VERSION ""

NS_ :

BS_:

BU_: DCM CCU C_ECU C_ECU_GW

BO_ 914 MET392: 32 C_ECU_GW
 SG_ MET392_23_0_ADD_ACNON_DRVRANG : 184|11@1+ (1,0) [0|1999] "km"  CCU
 SG_ MET392_21_0_ADD_ACNOFF_DRVRANG : 168|11@1+ (1,0) [0|1999] "km"  CCU
 SG_ MET392_18_0_TRIP_LASTCHG_TOTM : 144|20@1+ (1,0) [0|599940] "min"  CCU
 SG_ MET392_15_0_TRIPB_TOTAL_TIME : 120|20@1+ (1,0) [0|599940] "min"  CCU
 SG_ MET392_12_0_TRIPA_TOTAL_TIME : 96|20@1+ (1,0) [0|599940] "min"  CCU
 SG_ MET392_9_0_TRIP_LASTCHARGE_KM : 72|18@1+ (0.1,0) [0|16200] "km"  CCU
 SG_ MET392_8_2_TRIPB_RESET : 66|1@1+ (1,0) [0|1] "" Vector__XXX
 SG_ MET392_6_0_TRIPB_KM : 48|18@1+ (0.1,0) [0|16200] "km"  CCU
 SG_ MET392_5_2_TRIPA_RESET : 42|1@1+ (1,0) [0|1] "" Vector__XXX
 SG_ MET392_3_0_TRIPA_KM : 24|18@1+ (0.1,0) [0|16200] "km"  CCU
 SG_ MET392_2_0_E2E_COUNTER : 16|8@1+ (1,0) [0|255] ""  CCU
 SG_ MET392_0_0_CRC : 0|16@1+ (1,0) [0|65535] ""  CCU

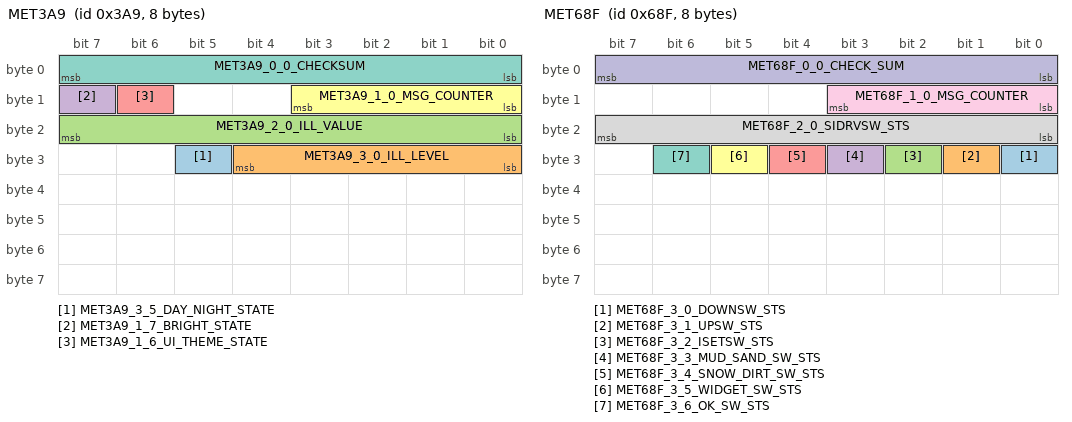
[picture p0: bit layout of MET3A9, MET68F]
BO_ 937 MET3A9: 8 C_ECU_GW
 SG_ MET3A9_3_5_DAY_NIGHT_STATE : 29|1@1+ (1,0) [0|1] ""  CCU
 SG_ MET3A9_3_0_ILL_LEVEL : 24|5@1+ (1,0) [0|21] ""  CCU
 SG_ MET3A9_2_0_ILL_VALUE : 16|8@1+ (0.4,0) [0|100] "%" Vector__XXX
 SG_ MET3A9_1_7_BRIGHT_STATE : 15|1@1+ (1,0) [0|1] ""  CCU
 SG_ MET3A9_1_6_UI_THEME_STATE : 14|1@1+ (1,0) [0|1] ""  CCU
 SG_ MET3A9_1_0_MSG_COUNTER : 8|4@1+ (1,0) [0|15] ""  CCU
 SG_ MET3A9_0_0_CHECKSUM : 0|8@1+ (1,0) [0|255] ""  CCU

BO_ 1679 MET68F: 8 C_ECU_GW
 SG_ MET68F_3_0_DOWNSW_STS : 24|1@1+ (1,0) [0|1] ""  CCU
 SG_ MET68F_3_1_UPSW_STS : 25|1@1+ (1,0) [0|1] ""  CCU
 SG_ MET68F_3_2_ISETSW_STS : 26|1@1+ (1,0) [0|1] ""  CCU
 SG_ MET68F_3_3_MUD_SAND_SW_STS : 27|1@1+ (1,0) [0|1] ""  CCU
 SG_ MET68F_3_4_SNOW_DIRT_SW_STS : 28|1@1+ (1,0) [0|1] ""  CCU
 SG_ MET68F_3_5_WIDGET_SW_STS : 29|1@1+ (1,0) [0|1] ""  CCU
 SG_ MET68F_3_6_OK_SW_STS : 30|1@1+ (1,0) [0|1] ""  CCU
 SG_ MET68F_2_0_SIDRVSW_STS : 16|8@1+ (1,0) [0|3] ""  CCU
 SG_ MET68F_1_0_MSG_COUNTER : 8|4@1+ (1,0) [0|15] ""  CCU
 SG_ MET68F_0_0_CHECK_SUM : 0|8@1+ (1,0) [0|255] ""  CCU

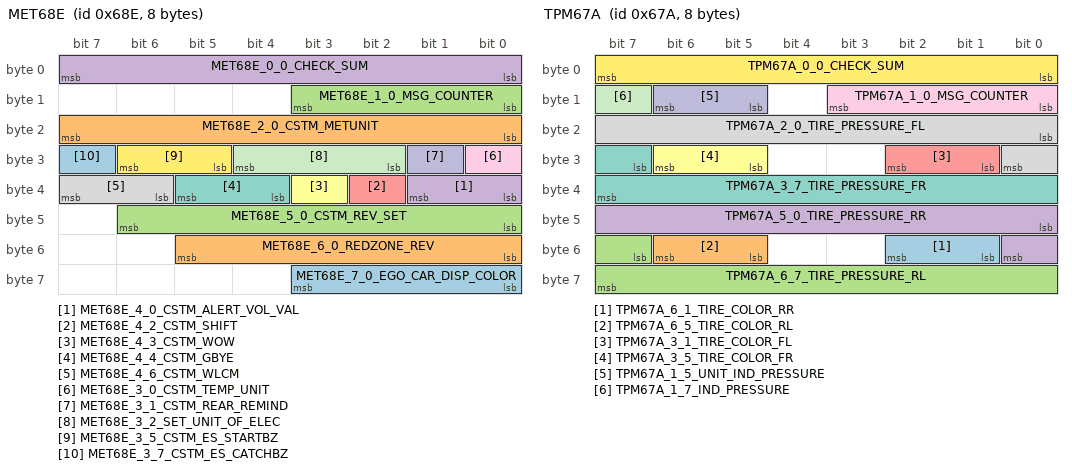
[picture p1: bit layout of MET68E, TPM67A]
BO_ 1678 MET68E: 8 C_ECU_GW
 SG_ MET68E_7_0_EGO_CAR_DISP_COLOR : 56|4@1+ (1,0) [0|9] "" Vector__XXX
 SG_ MET68E_6_0_REDZONE_REV : 48|6@1+ (100,5000) [0|40] "rpm"  CCU
 SG_ MET68E_5_0_CSTM_REV_SET : 40|7@1+ (1,0) [0|127] "" Vector__XXX
 SG_ MET68E_4_0_CSTM_ALERT_VOL_VAL : 32|2@1+ (1,0) [0|3] ""  CCU
 SG_ MET68E_4_2_CSTM_SHIFT : 34|1@1+ (1,0) [0|1] ""  CCU
 SG_ MET68E_4_3_CSTM_WOW : 35|1@1+ (1,0) [0|1] ""  CCU
 SG_ MET68E_4_4_CSTM_GBYE : 36|2@1+ (1,0) [0|3] ""  CCU
 SG_ MET68E_4_6_CSTM_WLCM : 38|2@1+ (1,0) [0|3] ""  CCU
 SG_ MET68E_3_0_CSTM_TEMP_UNIT : 24|1@1+ (1,0) [0|1] ""  CCU
 SG_ MET68E_3_1_CSTM_REAR_REMIND : 25|1@1+ (1,0) [0|1] ""  CCU
 SG_ MET68E_3_2_SET_UNIT_OF_ELEC : 26|3@1+ (1,0) [0|7] ""  DCM,CCU
 SG_ MET68E_3_5_CSTM_ES_STARTBZ : 29|2@1+ (1,0) [0|2] ""  CCU
 SG_ MET68E_3_7_CSTM_ES_CATCHBZ : 31|1@1+ (1,0) [0|1] ""  CCU
 SG_ MET68E_2_0_CSTM_METUNIT : 16|8@1+ (1,0) [0|0] ""  CCU
 SG_ MET68E_1_0_MSG_COUNTER : 8|4@1+ (1,0) [0|15] ""  DCM,CCU
 SG_ MET68E_0_0_CHECK_SUM : 0|8@1+ (1,0) [0|255] ""  DCM,CCU

BO_ 1674 MET68A: 32 C_ECU_GW
 SG_ MET68A_31_0_METBZ_STS_CH0 : 248|1@1+ (1,0) [0|1] ""  CCU
 SG_ MET68A_31_1_METBZ_STS_CH1 : 249|1@1+ (1,0) [0|1] ""  CCU
 SG_ MET68A_31_2_METBZ_WARN_CH0 : 250|1@1+ (1,0) [0|1] ""  CCU
 SG_ MET68A_31_3_METBZ_PTN_CH0 : 251|1@1+ (1,0) [0|1] ""  CCU
 SG_ MET68A_31_4_METBZ_WARN_CH1 : 252|1@1+ (1,0) [0|1] ""  CCU
 SG_ MET68A_31_5_METBZ_PTN_CH1 : 253|1@1+ (1,0) [0|1] ""  CCU
 SG_ MET68A_31_6_VOL_ATN_REQ : 254|2@1+ (1,0) [0|3] ""  CCU
 SG_ MET68A_30_0_METBZ_KIND_CH1 : 240|8@1+ (1,0) [0|255] ""  CCU
 SG_ MET68A_29_0_METBZ_KIND_CH0 : 232|8@1+ (1,0) [0|255] ""  CCU
 SG_ MET68A_26_0_TRIPB_VAL : 208|24@1+ (0.1,0) [0|1677721.5] ""  CCU
 SG_ MET68A_23_0_TRIPA_VAL : 184|24@1+ (0.1,0) [0|1677721.5] ""  CCU
 SG_ MET68A_22_6_VOL_MUTE_REQ : 182|2@1+ (1,0) [0|3] ""  CCU
 SG_ MET68A_21_0_IGNONDIST_VAL : 168|14@1+ (1,0) [0|16383] ""  CCU
 SG_ MET68A_20_1_IGNONTM_MIN_VAL : 161|6@1+ (1,0) [0|59] "min"  CCU
 SG_ MET68A_19_0_AVSP_TRIPB_VAL : 152|9@1+ (1,0) [0|300] ""  CCU
 SG_ MET68A_18_1_IGNONTM_HOUR_VAL : 145|7@1+ (1,0) [0|99] "h"  CCU
 SG_ MET68A_17_0_AVSP_TRIPA_VAL : 136|9@1+ (1,0) [0|300] ""  CCU
 SG_ MET68A_16_0_TRIP_DISP_TYPE : 128|8@1+ (1,0) [0|0] ""  DCM,CCU
 SG_ MET68A_13_0_TRIP_VAL : 104|24@1+ (0.1,0) [0|9999.9] ""  CCU
 SG_ MET68A_12_0_TEMPBAR_PER : 96|8@1+ (1,0) [0|250] ""  CCU
 SG_ MET68A_11_0_FUELBAR_PER : 88|8@1+ (1,0) [0|100] ""  CCU
 SG_ MET68A_9_0_TACHOREV_VAL : 72|16@1+ (1,0) [0|8000] "rpm"  CCU
 SG_ MET68A_7_0_SPD_COR_VAL : 56|16@1+ (1,0) [0|65535] ""  CCU
 SG_ MET68A_6_1_CID_TONE_DOWN : 49|5@1+ (1,0) [0|31] ""  CCU
 SG_ MET68A_6_6_SI_FAIL_FLAG : 54|1@1+ (1,0) [0|1] ""  CCU
 SG_ MET68A_5_0_DMSPD_SUB_VAL : 40|9@1+ (1,0) [0|300] ""  CCU
 SG_ MET68A_4_1_ILM_AIDM : 33|1@1+ (1,0) [0|1] ""  CCU
 SG_ MET68A_4_2_TEMP_ICON : 34|3@1+ (1,0) [0|7] ""  CCU
 SG_ MET68A_4_5_SIDRIVE_MET_DISP : 37|3@1+ (1,0) [0|7] ""  CCU
 SG_ MET68A_3_0_DMSPD_VAL : 24|9@1+ (1,0) [0|300] ""  CCU
 SG_ MET68A_2_0_E2E_COUNTER : 16|8@1+ (1,0) [0|255] ""  DCM,CCU
 SG_ MET68A_0_0_CRC : 0|16@1+ (1,0) [0|65535] ""  DCM,CCU

BO_ 1673 MET689: 32 C_ECU_GW
 SG_ MET689_20_0_VOICE_GUIDE_SUP : 160|1@1+ (1,0) [0|1] ""  CCU
 SG_ MET689_19_0_SPORT_CONT : 152|8@1+ (1,0) [0|255] ""  CCU
 SG_ MET689_18_0_STI_SUP : 144|8@1+ (1,0) [0|255] "" Vector__XXX
 SG_ MET689_17_0_REARVIEW : 136|1@1+ (1,0) [0|1] ""  CCU
 SG_ MET689_16_0_GSR_ELKS_SUP : 128|1@1+ (1,0) [0|1] ""  CCU
 SG_ MET689_16_1_GSR_AEBS_SUP : 129|1@1+ (1,0) [0|1] ""  CCU
 SG_ MET689_16_2_GSR_DDAW_SUP : 130|1@1+ (1,0) [0|1] ""  CCU
 SG_ MET689_16_3_GSR_ISA_SUP : 131|1@1+ (1,0) [0|1] ""  CCU
 SG_ MET689_16_4_IACC_SUP : 132|1@1+ (1,0) [0|1] ""  CCU
 SG_ MET689_16_5_REAR_PANEL_SUP : 133|1@1+ (1,0) [0|1] ""  CCU
 SG_ MET689_16_6_SEAT_HEATER_SUP : 134|1@1+ (1,0) [0|1] ""  CCU
 SG_ MET689_16_7_SEAT_VENT_SUP : 135|1@1+ (1,0) [0|1] ""  CCU
 SG_ MET689_15_0_CAMERA : 120|8@1+ (1,0) [0|8] ""  CCU
 SG_ MET689_14_0_SXM_VARIANT : 112|8@1+ (1,0) [0|255] "" Vector__XXX
 SG_ MET689_13_0_DAB : 104|1@1+ (1,0) [0|1] ""  CCU
 SG_ MET689_13_1_SXM : 105|1@1+ (1,0) [0|1] ""  CCU
 SG_ MET689_13_2_EMBEDDED_NAVI : 106|1@1+ (1,0) [0|1] ""  CCU
 SG_ MET689_12_0_SPK_AMP : 96|8@1+ (1,0) [0|17] ""  CCU
 SG_ MET689_11_0_DEST_VEHICLE : 88|8@1+ (1,0) [0|255] ""  CCU
 SG_ MET689_10_0_RDIFF_TEMP_SUP : 80|1@1+ (1,0) [0|1] ""  CCU
 SG_ MET689_10_1_SIDRIVE_SW_TYPE : 81|2@1+ (1,0) [0|3] ""  CCU
 SG_ MET689_10_3_XMODE_SW_TYPE : 83|2@1+ (1,0) [0|3] ""  CCU
 SG_ MET689_9_0_GPF_SUP : 72|1@1+ (1,0) [0|1] ""  CCU
 SG_ MET689_9_1_SRH_SUP : 73|1@1+ (1,0) [0|1] ""  CCU
 SG_ MET689_9_2_AUTO_DOOR_MIRROR_SUP : 74|1@1+ (1,0) [0|1] ""  CCU
 SG_ MET689_9_3_REAR_REMIND_SUP : 75|1@1+ (1,0) [0|1] ""  CCU
 SG_ MET689_9_4_DRIVE_TYPE : 76|1@1+ (1,0) [0|1] ""  CCU
 SG_ MET689_9_5_TPMSDISP_SUP : 77|1@1+ (1,0) [0|1] ""  CCU
 SG_ MET689_9_6_GSI_SUP : 78|1@1+ (1,0) [0|1] ""  CCU
 SG_ MET689_9_7_SRVD_SUP : 79|1@1+ (1,0) [0|1] ""  CCU
 SG_ MET689_8_0_XMODE_SUP : 64|8@1+ (1,0) [0|3] ""  CCU
 SG_ MET689_7_0_SIDRIVE_SUP : 56|8@1+ (1,0) [0|19] ""  CCU
 SG_ MET689_6_0_GRADE_INFO : 48|8@1+ (1,0) [0|1] ""  CCU
 SG_ MET689_5_0_VEHICLE_TYPE : 40|8@1+ (1,0) [0|255] ""  CCU
 SG_ MET689_4_0_DEST_GRP : 32|8@1+ (1,0) [0|255] ""  CCU
 SG_ MET689_3_0_VEHICLE_MODEL : 24|8@1+ (1,0) [0|255] ""  CCU
 SG_ MET689_2_0_E2E_COUNTER : 16|8@1+ (1,0) [0|255] ""  CCU
 SG_ MET689_0_0_CRC : 0|16@1+ (1,0) [0|65535] ""  CCU

BO_ 1658 TPM67A: 8 C_ECU_GW
 SG_ TPM67A_6_1_TIRE_COLOR_RR : 49|2@1+ (1,0) [0|3] ""  CCU
 SG_ TPM67A_6_5_TIRE_COLOR_RL : 53|2@1+ (1,0) [0|3] ""  CCU
 SG_ TPM67A_6_7_TIRE_PRESSURE_RL : 55|9@1+ (1,0) [0|511] ""  DCM,CCU
 SG_ TPM67A_5_0_TIRE_PRESSURE_RR : 40|9@1+ (1,0) [0|511] ""  DCM,CCU
 SG_ TPM67A_3_1_TIRE_COLOR_FL : 25|2@1+ (1,0) [0|3] ""  CCU
 SG_ TPM67A_3_5_TIRE_COLOR_FR : 29|2@1+ (1,0) [0|3] ""  CCU
 SG_ TPM67A_3_7_TIRE_PRESSURE_FR : 31|9@1+ (1,0) [0|511] ""  DCM,CCU
 SG_ TPM67A_2_0_TIRE_PRESSURE_FL : 16|9@1+ (1,0) [0|511] ""  DCM,CCU
 SG_ TPM67A_1_0_MSG_COUNTER : 8|4@1+ (1,0) [0|15] ""  DCM,CCU
 SG_ TPM67A_1_5_UNIT_IND_PRESSURE : 13|2@1+ (1,0) [0|3] ""  DCM,CCU
 SG_ TPM67A_1_7_IND_PRESSURE : 15|1@1+ (1,0) [0|1] ""  CCU
 SG_ TPM67A_0_0_CHECK_SUM : 0|8@1+ (1,0) [0|255] ""  DCM,CCU

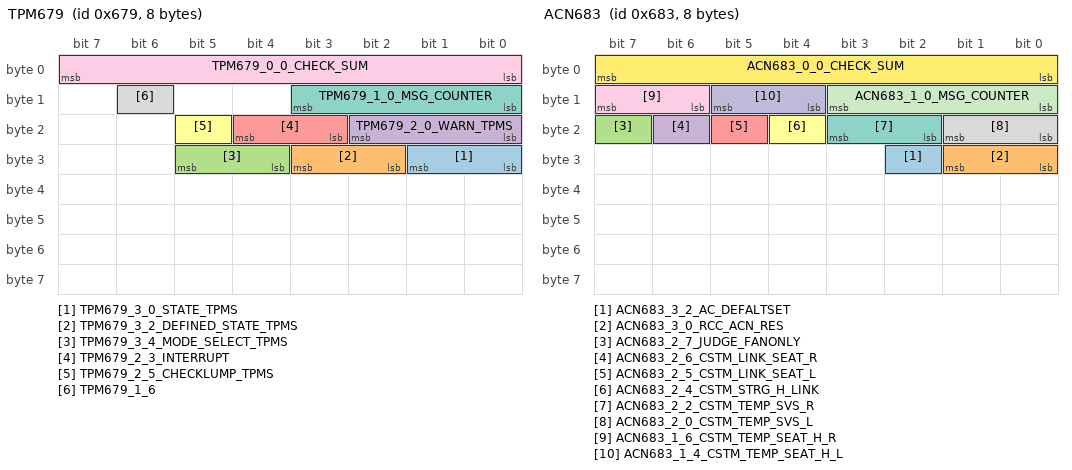
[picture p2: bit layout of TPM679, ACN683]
BO_ 1657 TPM679: 8 C_ECU_GW
 SG_ TPM679_3_0_STATE_TPMS : 24|2@1+ (1,0) [0|3] ""  CCU
 SG_ TPM679_3_2_DEFINED_STATE_TPMS : 26|2@1+ (1,0) [0|3] ""  CCU
 SG_ TPM679_3_4_MODE_SELECT_TPMS : 28|2@1+ (1,0) [0|3] ""  CCU
 SG_ TPM679_2_0_WARN_TPMS : 16|3@1+ (1,0) [0|7] ""  DCM
 SG_ TPM679_2_3_INTERRUPT : 19|2@1+ (1,0) [0|2] "" Vector__XXX
 SG_ TPM679_2_5_CHECKLUMP_TPMS : 21|1@1+ (1,0) [0|1] "" Vector__XXX
 SG_ TPM679_1_0_MSG_COUNTER : 8|4@1+ (1,0) [0|15] ""  DCM,CCU
 SG_ TPM679_1_6 : 14|1@1+ (1,0) [0|1] "" Vector__XXX
 SG_ TPM679_0_0_CHECK_SUM : 0|8@1+ (1,0) [0|255] ""  DCM,CCU

BO_ 826 ABG33A: 8 C_ECU_GW
 SG_ ABG33A_7_0_VELOCITYCHANGE_VX_MAX : 56|8@1+ (1,0) [-101|101] "km/h" Vector__XXX
 SG_ ABG33A_6_0_VELOCITYCHANGE_VX_MAX : 48|8@1+ (1,0) [-101|101] "km/h" Vector__XXX
 SG_ ABG33A_5_0_P_SIDE_ABG_DEPLOY : 40|1@1+ (1,0) [0|1] ""  CCU
 SG_ ABG33A_5_1_D_SIDE_ABG_DEPLOY : 41|1@1+ (1,0) [0|1] ""  CCU
 SG_ ABG33A_5_2_FRONT_FAR_ABG_DEPLOY : 42|1@1+ (1,0) [0|1] ""  CCU
 SG_ ABG33A_5_3_REAR_FAR_ABG_DEPLOY : 43|1@1+ (1,0) [0|1] ""  CCU
 SG_ ABG33A_5_4_REAR_RH_ABG_DEPLOY : 44|1@1+ (1,0) [0|1] ""  CCU
 SG_ ABG33A_5_5_REAR_LH_ABG_DEPLOY : 45|1@1+ (1,0) [0|1] ""  CCU
 SG_ ABG33A_5_6_P_CURTAIN_ABG_DEPLOY : 46|1@1+ (1,0) [0|1] ""  CCU
 SG_ ABG33A_5_7_D_CURTAIN_ABG_DEPLOY : 47|1@1+ (1,0) [0|1] ""  CCU
 SG_ ABG33A_4_0_D_FRONT_ABG_DEPLOY : 32|1@1+ (1,0) [0|1] ""  CCU
 SG_ ABG33A_4_1_P_FRONT_ABG_DEPLOY : 33|1@1+ (1,0) [0|1] ""  CCU
 SG_ ABG33A_4_2_P_ABG_DEPLOY : 34|1@1+ (1,0) [0|1] ""  CCU
 SG_ ABG33A_4_3_D_ABG_DEPLOY : 35|1@1+ (1,0) [0|1] ""  CCU
 SG_ ABG33A_4_4_P_BELT_PRETENTION : 36|1@1+ (1,0) [0|1] ""  CCU
 SG_ ABG33A_4_5_D_BELT_PRETENTION : 37|1@1+ (1,0) [0|1] ""  CCU
 SG_ ABG33A_4_6_D_KNEE_ABG_DEPLOY : 38|1@1+ (1,0) [0|1] ""  CCU
 SG_ ABG33A_4_7_P_KNEE_ABG_DEPLOY : 39|1@1+ (1,0) [0|1] "" Vector__XXX
 SG_ ABG33A_3_0_BELT_WRNING_PASS : 24|2@1+ (1,0) [0|3] "" Vector__XXX
 SG_ ABG33A_3_2_BUCKLESW_DRVR : 26|2@1+ (1,0) [0|3] "" Vector__XXX
 SG_ ABG33A_3_4_OCCUPATION_PASS : 28|2@1+ (1,0) [0|3] ""  CCU
 SG_ ABG33A_3_6_IND_ACT_ABG_PASS : 30|2@1+ (1,0) [0|3] "" Vector__XXX
 SG_ ABG33A_2_0_IND_WARN_ABG : 16|2@1+ (1,0) [0|3] ""  CCU
 SG_ ABG33A_2_2_DETECT_CRUSH : 18|3@1+ (1,0) [0|7] ""  CCU
 SG_ ABG33A_2_5_STATUS_CRUSH_ECALL : 21|3@1+ (1,0) [0|7] "" Vector__XXX
 SG_ ABG33A_1_0_MSG_COUNTER : 8|4@1+ (1,0) [0|15] "" Vector__XXX
 SG_ ABG33A_1_4_FLG_ABGIND_CTRL : 12|1@1+ (1,0) [0|1] "" Vector__XXX
 SG_ ABG33A_1_5_REQ_COMM_CONT : 13|1@1+ (1,0) [0|1] "" Vector__XXX
 SG_ ABG33A_1_6_COLLISION_COUNTER : 14|2@1+ (1,0) [0|3] "" Vector__XXX
 SG_ ABG33A_0_0_CHECK_SUM : 0|8@1+ (1,0) [0|255] "" Vector__XXX

BO_ 961 DMS3C1: 8 C_ECU_GW
 SG_ DMS3C1_7_4_SHORT_DIST_DETECT : 60|1@1+ (1,0) [0|1] ""  CCU
 SG_ DMS3C1_7_5_PRESENCE_DETECT : 61|1@1+ (1,0) [0|1] "" Vector__XXX
 SG_ DMS3C1_7_6_RADER_EQUIP : 62|1@1+ (1,0) [0|1] "" Vector__XXX
 SG_ DMS3C1_7_7_LOSING_POSTURE_DETECT : 63|1@1+ (1,0) [0|1] ""  CCU
 SG_ DMS3C1_6_0_ID_RECOG_CANCEL : 48|1@1+ (1,0) [0|1] ""  CCU
 SG_ DMS3C1_6_1_ID_ENABLE_FLAG : 49|1@1+ (1,0) [0|1] "" Vector__XXX
 SG_ DMS3C1_6_2_PERMIT_AVN_FLAG : 50|1@1+ (1,0) [0|1] "" Vector__XXX
 SG_ DMS3C1_6_4_DISTRACTION_STATUS : 52|1@1+ (1,0) [0|1] ""  CCU
 SG_ DMS3C1_6_5_DROWSINESS_STATUS : 53|1@1+ (1,0) [0|1] ""  CCU
 SG_ DMS3C1_6_6_DROWSINESS_LV2_STATUS : 54|1@1+ (1,0) [0|1] ""  CCU
 SG_ DMS3C1_6_7_NOT_DETECTED_STATUS : 55|1@1+ (1,0) [0|1] "" Vector__XXX
 SG_ DMS3C1_5_0_ID_LIST : 40|5@1+ (1,0) [0|31] ""  CCU
 SG_ DMS3C1_5_5_ID_EDIT_FLAG : 45|3@1+ (1,0) [0|6] ""  CCU
 SG_ DMS3C1_4_0_DMS_IND_REQ_FLAG : 32|3@1+ (1,0) [0|7] ""  CCU
 SG_ DMS3C1_4_3_DMS_RECOG_STATUS : 35|1@1+ (1,0) [0|1] ""  CCU
 SG_ DMS3C1_4_4_DRIVER_STATUS : 36|4@1+ (1,0) [0|3] "" Vector__XXX
 SG_ DMS3C1_3_0_DRIVER_REGIST_ID : 24|4@1+ (1,0) [0|15] ""  CCU
 SG_ DMS3C1_3_4_CUST_EDIT_FLAG : 28|2@1+ (1,0) [0|3] ""  CCU
 SG_ DMS3C1_3_6_ID_RECOG_FLAG : 30|1@1+ (1,0) [0|1] ""  CCU
 SG_ DMS3C1_2_0_LEVEL_DROWS : 16|3@1+ (1,0) [0|2] ""  CCU
 SG_ DMS3C1_2_3_DROWS_DETECT_FLAG : 19|1@1+ (1,0) [0|1] ""  CCU
 SG_ DMS3C1_2_7_DIST_DETECT_FLAG : 23|1@1+ (1,0) [0|1] ""  CCU
 SG_ DMS3C1_1_0_MSG_COUNTER : 8|4@1+ (1,0) [0|15] ""  CCU
 SG_ DMS3C1_1_4_WAKE_UP_FRAME : 12|1@1+ (1,0) [0|1] "" Vector__XXX
 SG_ DMS3C1_1_5_REQ_COMM_CONT : 13|1@1+ (1,0) [0|1] "" Vector__XXX
 SG_ DMS3C1_1_7_EYE_DIST_FLAG : 15|1@1+ (1,0) [0|1] "" Vector__XXX
 SG_ DMS3C1_0_0_CHKSUM : 0|8@1+ (1,0) [0|255] ""  CCU

BO_ 1651 ACN673: 8 C_ECU_GW
 SG_ ACN673_7_2_REQ_STRG_H : 58|2@1+ (1,0) [0|3] "" Vector__XXX
 SG_ ACN673_7_1_SEAT_H_L_AUTOIND : 57|1@1+ (1,0) [0|1] ""  CCU
 SG_ ACN673_7_0_SEAT_H_R_AUTOIND : 56|1@1+ (1,0) [0|1] ""  CCU
 SG_ ACN673_6_0_RR_FAN_SYMBOL : 48|1@1+ (1,0) [0|1] ""  CCU
 SG_ ACN673_6_2_SEAT_H_R : 50|3@1+ (1,0) [0|7] ""  CCU
 SG_ ACN673_6_5_SEAT_H_L : 53|3@1+ (1,0) [0|7] ""  CCU
 SG_ ACN673_5_0_DR_ONLY : 40|2@1+ (1,0) [0|3] ""  CCU
 SG_ ACN673_5_2_STRG_H : 42|2@1+ (1,0) [0|3] ""  CCU
 SG_ ACN673_5_4_AC_SI_DS_SET : 44|2@1+ (1,0) [0|3] "" Vector__XXX
 SG_ ACN673_5_6_STRG_H_AUTOIND : 46|1@1+ (1,0) [0|1] ""  CCU
 SG_ ACN673_5_7_AC_SI_DS_FLG : 47|1@1+ (1,0) [0|1] "" Vector__XXX
 SG_ ACN673_4_0_SEAT_HEATER_DR : 32|2@1+ (1,0) [0|3] ""  CCU
 SG_ ACN673_4_2_SEAT_HEATER_PA : 34|2@1+ (1,0) [0|3] ""  CCU
 SG_ ACN673_4_4_SEAT_HEATER : 36|1@1+ (1,0) [0|1] "" Vector__XXX
 SG_ ACN673_4_5_TEMP_SET_TYPE : 37|2@1+ (1,0) [0|3] ""  CCU
 SG_ ACN673_4_7_VENTI_SEAT_EX_HI : 39|1@1+ (1,0) [0|1] "" Vector__XXX
 SG_ ACN673_1_0_MSG_COUNTER : 8|4@1+ (1,0) [0|15] ""  CCU
 SG_ ACN673_1_6_SYNC_RR : 14|1@1+ (1,0) [0|1] "" Vector__XXX
 SG_ ACN673_1_7_RR_LOCK : 15|1@1+ (1,0) [0|1] "" Vector__XXX
 SG_ ACN673_0_0_CHECK_SUM : 0|8@1+ (1,0) [0|255] ""  CCU

BO_ 1650 ACN672: 8 C_ECU_GW
 SG_ ACN672_7_0_INFO_AUTO3MODE : 56|2@1+ (1,0) [0|3] ""  CCU
 SG_ ACN672_7_2_INFO_REAR_TEMP : 58|6@1+ (1,0) [0|44] "" Vector__XXX
 SG_ ACN672_6_0_DEF : 48|1@1+ (1,0) [0|1] ""  CCU
 SG_ ACN672_6_1_FAN_SYMBOL : 49|1@1+ (1,0) [0|1] ""  CCU
 SG_ ACN672_6_2_REAR_MODE : 50|2@1+ (1,0) [0|3] "" Vector__XXX
 SG_ ACN672_6_4_UNIT_TEMP : 52|1@1+ (1,0) [0|1] ""  CCU
 SG_ ACN672_6_5_SPEC_AC_UNIT : 53|2@1+ (1,0) [0|3] ""  CCU
 SG_ ACN672_6_7_REAR_AC : 55|1@1+ (1,0) [0|1] ""  CCU
 SG_ ACN672_5_0_AC_VR_MODE : 40|2@1+ (1,0) [0|3] ""  CCU
 SG_ ACN672_5_2_INFO_TEMP_PASS : 42|6@1+ (1,0) [0|63] ""  CCU
 SG_ ACN672_4_0_AC_INTERRUPT_DISPLAY : 32|1@1+ (1,0) [0|1] "" Vector__XXX
 SG_ ACN672_4_1_AC_VR_ACTION : 33|1@1+ (1,0) [0|1] "" Vector__XXX
 SG_ ACN672_4_2_INFO_TEMP_DRVR : 34|6@1+ (1,0) [0|63] ""  CCU
 SG_ ACN672_3_0_MAX_AC : 24|1@1+ (1,0) [0|1] ""  CCU
 SG_ ACN672_3_1_INFO_SYNC_OR_SING : 25|1@1+ (1,0) [0|1] ""  CCU
 SG_ ACN672_3_2_INFO_FULL_OR_AUTO : 26|2@1+ (1,0) [0|3] ""  CCU
 SG_ ACN672_3_4_INFO_AC_ON : 28|1@1+ (1,0) [0|1] ""  CCU
 SG_ ACN672_3_5_INFO_RDEF : 29|1@1+ (1,0) [0|1] ""  CCU
 SG_ ACN672_3_6_INFO_CIRCULATION : 30|2@1+ (1,0) [0|3] ""  CCU
 SG_ ACN672_2_0_INFO_MODE_VENT : 16|4@1+ (1,0) [0|15] ""  CCU
 SG_ ACN672_2_4_INFO_FANONLY : 20|1@1+ (1,0) [0|1] ""  CCU
 SG_ ACN672_2_5_INFO_LEV_BLOWERFAN : 21|3@1+ (1,0) [0|7] ""  CCU
 SG_ ACN672_1_0_MSG_COUNTER : 8|4@1+ (1,0) [0|15] ""  CCU
 SG_ ACN672_1_4_LVL_BLOWERFAN_RR : 12|3@1+ (1,0) [0|7] "" Vector__XXX
 SG_ ACN672_1_7_REAR_AUTO : 15|1@1+ (1,0) [0|1] ""  CCU
 SG_ ACN672_0_0_CHECK_SUM : 0|8@1+ (1,0) [0|255] ""  CCU

BO_ 722 ACN2D2: 8 C_ECU_GW
 SG_ ACN2D2_7_0_PD_PRESSURE : 56|8@1+ (0.0146866,0) [0|3.74509] "Mpa" Vector__XXX
 SG_ ACN2D2_6_0_TRQ_COMP_ESTM : 48|8@1+ (0.3921568627451,0) [0|100] "Nm" Vector__XXX
 SG_ ACN2D2_5_0_REQ_ENG_RPM : 40|3@1+ (1,0) [0|6] "" Vector__XXX
 SG_ ACN2D2_5_3_REQ_IDLE_COMP_RPM : 43|5@1+ (25,650) [650|1425] "rpm" Vector__XXX
 SG_ ACN2D2_4_0_LVL_PTC : 32|2@1+ (1,0) [0|3] "" Vector__XXX
 SG_ ACN2D2_4_2_MARGIN_OF_AC : 34|3@1+ (1,0) [0|7] "" Vector__XXX
 SG_ ACN2D2_4_5_LVL_BLOWER_FAN : 37|3@1+ (1,0) [0|7] "" Vector__XXX
 SG_ ACN2D2_3_0_PERMIT_ISS : 24|2@1+ (1,0) [0|3] "" Vector__XXX
 SG_ ACN2D2_3_2_TRQ_PAT_COMP_ESTM : 26|3@1+ (1,0) [0|6] "" Vector__XXX
 SG_ ACN2D2_3_5_IND_ROOM_TEMP : 29|3@1+ (1,0) [0|4] ""  CCU
 SG_ ACN2D2_2_0_FAIL_TRQ_COMP_ESTM : 16|1@1+ (1,0) [0|1] "" Vector__XXX
 SG_ ACN2D2_2_1_FAIL_AC : 17|1@1+ (1,0) [0|1] "" Vector__XXX
 SG_ ACN2D2_2_2_REQ_INHIBIT_LOCKUP : 18|1@1+ (1,0) [0|1] "" Vector__XXX
 SG_ ACN2D2_2_3_AC_ON : 19|1@1+ (1,0) [0|1] "" Vector__XXX
 SG_ ACN2D2_2_4_RDEFOGSW : 20|1@1+ (1,0) [0|1] "" Vector__XXX
 SG_ ACN2D2_2_5_WARM_UP : 21|1@1+ (1,0) [0|1] "" Vector__XXX
 SG_ ACN2D2_2_6_AC_AUTO_MANUAL : 22|1@1+ (1,0) [0|1] "" Vector__XXX
 SG_ ACN2D2_2_7_COMP_TYPE : 23|1@1+ (1,0) [0|1] "" Vector__XXX
 SG_ ACN2D2_1_0_MSG_COUNTER : 8|4@1+ (1,0) [0|15] "" Vector__XXX
 SG_ ACN2D2_1_4 : 12|1@1+ (1,0) [0|1] "" Vector__XXX
 SG_ ACN2D2_1_5 : 13|1@1+ (1,0) [0|1] "" Vector__XXX
 SG_ ACN2D2_1_6 : 14|1@1+ (1,0) [0|1] "" Vector__XXX
 SG_ ACN2D2_1_7_WARM_POWER_CONT : 15|1@1+ (1,0) [0|1] "" Vector__XXX
 SG_ ACN2D2_0_0_CHECK_SUM : 0|8@1+ (1,0) [0|255] "" Vector__XXX

BO_ 1667 ACN683: 8 C_ECU_GW
 SG_ ACN683_3_2_AC_DEFALTSET : 26|1@1+ (1,0) [0|1] ""  CCU
 SG_ ACN683_3_0_RCC_ACN_RES : 24|2@1+ (1,0) [0|3] "" Vector__XXX
 SG_ ACN683_2_7_JUDGE_FANONLY : 23|1@1+ (1,0) [0|1] ""  CCU
 SG_ ACN683_2_6_CSTM_LINK_SEAT_R : 22|1@1+ (1,0) [0|1] ""  CCU
 SG_ ACN683_2_5_CSTM_LINK_SEAT_L : 21|1@1+ (1,0) [0|1] ""  CCU
 SG_ ACN683_2_4_CSTM_STRG_H_LINK : 20|1@1+ (1,0) [0|1] ""  CCU
 SG_ ACN683_2_2_CSTM_TEMP_SVS_R : 18|2@1+ (1,0) [0|3] ""  CCU
 SG_ ACN683_2_0_CSTM_TEMP_SVS_L : 16|2@1+ (1,0) [0|3] ""  CCU
 SG_ ACN683_1_6_CSTM_TEMP_SEAT_H_R : 14|2@1+ (1,0) [0|3] ""  CCU
 SG_ ACN683_1_4_CSTM_TEMP_SEAT_H_L : 12|2@1+ (1,0) [0|3] ""  CCU
 SG_ ACN683_1_0_MSG_COUNTER : 8|4@1+ (1,0) [0|15] ""  CCU
 SG_ ACN683_0_0_CHECK_SUM : 0|8@1+ (1,0) [0|255] ""  CCU

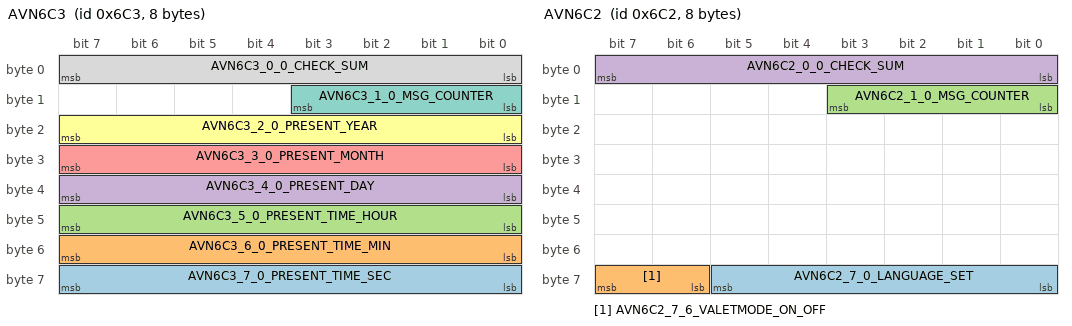
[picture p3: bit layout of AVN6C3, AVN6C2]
BO_ 1731 AVN6C3: 8 CCU
 SG_ AVN6C3_7_0_PRESENT_TIME_SEC : 63|8@0+ (1,0) [0|255] "s"  C_ECU
 SG_ AVN6C3_6_0_PRESENT_TIME_MIN : 55|8@0+ (1,0) [0|255] "m"  C_ECU
 SG_ AVN6C3_5_0_PRESENT_TIME_HOUR : 47|8@0+ (1,0) [0|255] "h"  C_ECU
 SG_ AVN6C3_4_0_PRESENT_DAY : 39|8@0+ (1,0) [0|255] "Day"  C_ECU
 SG_ AVN6C3_3_0_PRESENT_MONTH : 31|8@0+ (1,0) [0|255] "Month"  C_ECU
 SG_ AVN6C3_2_0_PRESENT_YEAR : 23|8@0+ (1,0) [0|255] "Year"  C_ECU
 SG_ AVN6C3_1_0_MSG_COUNTER : 11|4@0+ (1,0) [0|15] ""  C_ECU
 SG_ AVN6C3_0_0_CHECK_SUM : 7|8@0+ (1,0) [0|255] ""  C_ECU

BO_ 1730 AVN6C2: 8 CCU
 SG_ AVN6C2_7_0_LANGUAGE_SET : 61|6@0+ (1,0) [0|33] ""  DCM,C_ECU_GW
 SG_ AVN6C2_7_6_VALETMODE_ON_OFF : 63|2@0+ (1,0) [0|3] ""  C_ECU,C_ECU_GW
 SG_ AVN6C2_1_0_MSG_COUNTER : 11|4@0+ (1,0) [0|15] ""  DCM,C_ECU_GW
 SG_ AVN6C2_0_0_CHECK_SUM : 7|8@0+ (1,0) [0|255] ""  DCM,C_ECU_GW

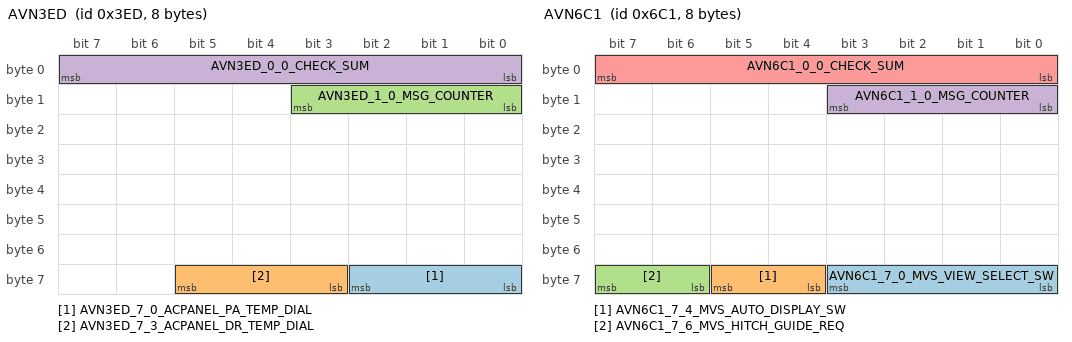
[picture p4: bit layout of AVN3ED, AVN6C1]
BO_ 1005 AVN3ED: 8 CCU
 SG_ AVN3ED_7_0_ACPANEL_PA_TEMP_DIAL : 58|3@0+ (1,0) [0|7] ""  C_ECU_GW
 SG_ AVN3ED_7_3_ACPANEL_DR_TEMP_DIAL : 61|3@0+ (1,0) [0|7] ""  C_ECU_GW
 SG_ AVN3ED_1_0_MSG_COUNTER : 11|4@0+ (1,0) [0|15] ""  C_ECU_GW
 SG_ AVN3ED_0_0_CHECK_SUM : 7|8@0+ (1,0) [0|255] ""  C_ECU_GW

BO_ 1729 AVN6C1: 8 CCU
 SG_ AVN6C1_7_0_MVS_VIEW_SELECT_SW : 59|4@0+ (1,0) [0|6] ""  C_ECU_GW
 SG_ AVN6C1_7_4_MVS_AUTO_DISPLAY_SW : 61|2@0+ (1,0) [0|3] ""  C_ECU_GW
 SG_ AVN6C1_7_6_MVS_HITCH_GUIDE_REQ : 63|2@0+ (1,0) [0|3] ""  C_ECU_GW
 SG_ AVN6C1_1_0_MSG_COUNTER : 11|4@0+ (1,0) [0|15] ""  C_ECU_GW
 SG_ AVN6C1_0_0_CHECK_SUM : 7|8@0+ (1,0) [0|255] ""  C_ECU_GW

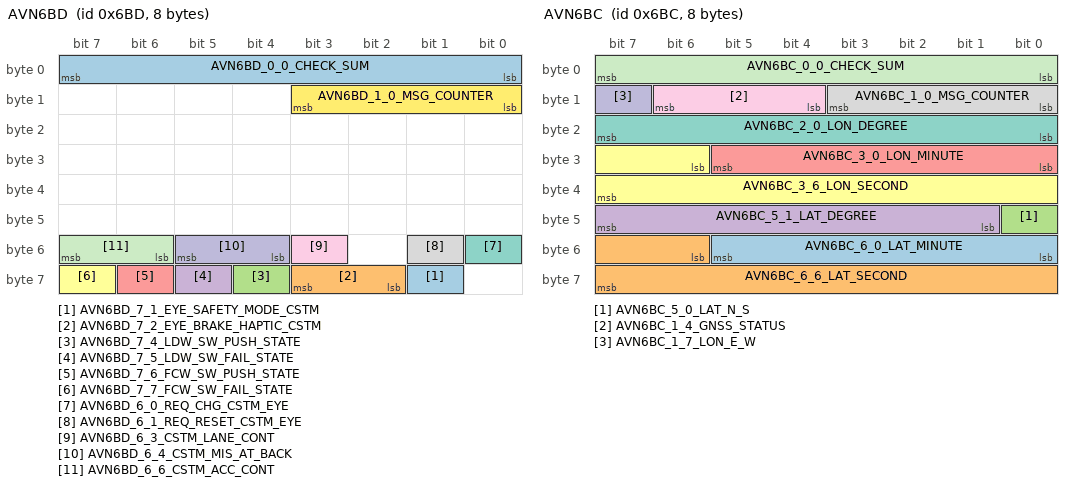
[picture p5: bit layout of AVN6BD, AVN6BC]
BO_ 1725 AVN6BD: 8 CCU
 SG_ AVN6BD_7_1_EYE_SAFETY_MODE_CSTM : 57|1@0+ (1,0) [0|1] ""  C_ECU_GW
 SG_ AVN6BD_7_2_EYE_BRAKE_HAPTIC_CSTM : 59|2@0+ (1,0) [0|3] ""  C_ECU_GW
 SG_ AVN6BD_7_4_LDW_SW_PUSH_STATE : 60|1@0+ (1,0) [0|1] ""  C_ECU_GW
 SG_ AVN6BD_7_5_LDW_SW_FAIL_STATE : 61|1@0+ (1,0) [0|1] ""  C_ECU_GW
 SG_ AVN6BD_7_6_FCW_SW_PUSH_STATE : 62|1@0+ (1,0) [0|1] ""  C_ECU_GW
 SG_ AVN6BD_7_7_FCW_SW_FAIL_STATE : 63|1@0+ (1,0) [0|1] ""  C_ECU_GW
 SG_ AVN6BD_6_0_REQ_CHG_CSTM_EYE : 48|1@0+ (1,0) [0|1] ""  C_ECU_GW
 SG_ AVN6BD_6_1_REQ_RESET_CSTM_EYE : 49|1@0+ (1,0) [0|1] ""  C_ECU_GW
 SG_ AVN6BD_6_3_CSTM_LANE_CONT : 51|1@0+ (1,0) [0|1] ""  C_ECU_GW
 SG_ AVN6BD_6_4_CSTM_MIS_AT_BACK : 53|2@0+ (1,0) [0|3] ""  C_ECU_GW
 SG_ AVN6BD_6_6_CSTM_ACC_CONT : 55|2@0+ (1,0) [0|3] ""  C_ECU_GW
 SG_ AVN6BD_1_0_MSG_COUNTER : 11|4@0+ (1,0) [0|15] ""  C_ECU_GW
 SG_ AVN6BD_0_0_CHECK_SUM : 7|8@0+ (1,0) [0|255] ""  C_ECU_GW

BO_ 1724 AVN6BC: 8 CCU
 SG_ AVN6BC_6_0_LAT_MINUTE : 48|6@1+ (1,0) [0|59] ""  C_ECU,C_ECU_GW
 SG_ AVN6BC_6_6_LAT_SECOND : 54|10@1+ (0.1,0) [0|59.9] ""  C_ECU,C_ECU_GW
 SG_ AVN6BC_5_0_LAT_N_S : 40|1@1+ (1,0) [0|1] ""  C_ECU,C_ECU_GW
 SG_ AVN6BC_5_1_LAT_DEGREE : 41|7@1+ (1,0) [0|90] ""  C_ECU,C_ECU_GW
 SG_ AVN6BC_3_0_LON_MINUTE : 24|6@1+ (1,0) [0|59] ""  C_ECU,C_ECU_GW
 SG_ AVN6BC_3_6_LON_SECOND : 30|10@1+ (0.1,0) [0|59.9] ""  C_ECU,C_ECU_GW
 SG_ AVN6BC_2_0_LON_DEGREE : 16|8@1+ (1,0) [0|180] ""  C_ECU,C_ECU_GW
 SG_ AVN6BC_1_0_MSG_COUNTER : 8|4@1+ (1,0) [0|15] ""  C_ECU,C_ECU_GW
 SG_ AVN6BC_1_4_GNSS_STATUS : 12|3@1+ (1,0) [0|7] ""  C_ECU,C_ECU_GW
 SG_ AVN6BC_1_7_LON_E_W : 15|1@1+ (1,0) [0|1] ""  C_ECU,C_ECU_GW
 SG_ AVN6BC_0_0_CHECK_SUM : 0|8@1+ (1,0) [0|255] ""  C_ECU,C_ECU_GW

BO_ 1723 AVN6BB: 8 CCU
 SG_ AVN6BB_7_0_ISA_IACC_OFFSET_CSTM : 56|5@1+ (1,0) [0|20] ""  C_ECU_GW
 SG_ AVN6BB_7_5_EYE_TOLLBOOTH_DECEL : 61|1@1+ (1,0) [0|1] ""  C_ECU_GW
 SG_ AVN6BB_7_6_EYE_CURVE_DECEL_CSTM : 62|1@1+ (1,0) [0|1] ""  C_ECU_GW
 SG_ AVN6BB_7_7_EYE_GREEN_LIGHT_CSTM : 63|1@1+ (1,0) [0|1] ""  C_ECU_GW
 SG_ AVN6BB_6_0_CCU_FAIL : 48|1@1+ (1,0) [0|1] ""  C_ECU_GW
 SG_ AVN6BB_6_1_EYE_P_CR_CSTM : 49|1@1+ (1,0) [0|1] ""  C_ECU_GW
 SG_ AVN6BB_6_2_EYE_ALK_B_LDW_CSTM : 50|2@1+ (1,0) [0|3] ""  C_ECU_GW
 SG_ AVN6BB_6_4_EYE_CSTM_REQ : 52|1@1+ (1,0) [0|1] ""  C_ECU_GW
 SG_ AVN6BB_6_5_EYE_ELK_CSTM : 53|1@1+ (1,0) [0|1] ""  C_ECU_GW
 SG_ AVN6BB_6_6_EYE_ALKB_EDGE_CSTM : 54|1@1+ (1,0) [0|1] ""  C_ECU_GW
 SG_ AVN6BB_6_7_FCW_ON_OFF : 55|1@1+ (1,0) [0|1] ""  C_ECU_GW
 SG_ AVN6BB_5_0_DMS_SELECT_ID : 40|4@1+ (1,0) [0|5] ""  C_ECU_GW
 SG_ AVN6BB_5_4_TPMS_TH_MODE_CSTM : 44|2@1+ (1,0) [0|3] ""  C_ECU_GW
 SG_ AVN6BB_5_6_DMS_SET_REQ : 46|1@1+ (1,0) [0|1] ""  C_ECU_GW
 SG_ AVN6BB_5_7_DMS_RECOG_SET : 47|1@1+ (1,0) [0|1] ""  C_ECU_GW
 SG_ AVN6BB_4_0_DMS_EDIT_REQ : 32|4@1+ (1,0) [0|15] ""  C_ECU_GW
 SG_ AVN6BB_4_4_VEHICLE_DEMO : 36|1@1+ (1,0) [0|1] ""  C_ECU_GW
 SG_ AVN6BB_4_5_SRVD_CSTM_REQ : 37|1@1+ (1,0) [0|1] ""  C_ECU_GW
 SG_ AVN6BB_4_6_SEAT_RESET_REQ : 38|1@1+ (1,0) [0|1] ""  C_ECU_GW
 SG_ AVN6BB_4_7_SEATAWAY_SET_CSTM : 39|1@1+ (1,0) [0|1] ""  C_ECU,C_ECU_GW
 SG_ AVN6BB_3_0_SRVD_ON_OFF : 24|1@1+ (1,0) [0|1] ""  C_ECU_GW
 SG_ AVN6BB_3_1_PRG_RESET_REQ : 25|1@1+ (1,0) [0|1] ""  C_ECU_GW
 SG_ AVN6BB_3_2_PRG_MEM_CSTM : 26|1@1+ (1,0) [0|1] ""  C_ECU_GW
 SG_ AVN6BB_3_3_DMS_ON_OFF : 27|1@1+ (1,0) [0|1] ""  C_ECU_GW
 SG_ AVN6BB_3_4_MIR_RESET_REQ : 28|1@1+ (1,0) [0|1] ""  C_ECU_GW
 SG_ AVN6BB_3_5_MIR_AFOLD_CSTM : 29|1@1+ (1,0) [0|1] ""  C_ECU,C_ECU_GW
 SG_ AVN6BB_3_6_MIR_RTILT_CSTM : 30|1@1+ (1,0) [0|1] ""  C_ECU_GW
 SG_ AVN6BB_3_7_EYE_TSA_CSTM : 31|1@1+ (1,0) [0|1] ""  C_ECU_GW
 SG_ AVN6BB_2_0_AVH_ON_OFF : 16|2@1+ (1,0) [0|3] ""  C_ECU_GW
 SG_ AVN6BB_2_2_VDC_ON_OFF : 18|2@1+ (1,0) [0|3] ""  C_ECU_GW
 SG_ AVN6BB_2_4_CCU_HALT_RESET : 20|1@1+ (1,0) [0|1] ""  C_ECU_GW
 SG_ AVN6BB_2_5_EYE_LDW_TIMING_CSTM : 21|1@1+ (1,0) [0|1] ""  C_ECU_GW
 SG_ AVN6BB_2_6_FCW_CSTM : 22|2@1+ (1,0) [0|3] ""  C_ECU_GW
 SG_ AVN6BB_1_0_MSG_COUNTER : 8|4@1+ (1,0) [0|15] ""  C_ECU,C_ECU_GW
 SG_ AVN6BB_1_4_EYE_WARN_CSTM : 12|1@1+ (1,0) [0|1] ""  C_ECU_GW
 SG_ AVN6BB_1_5_EYE_FCTI_CSTM : 13|2@1+ (1,0) [0|3] ""  C_ECU_GW
 SG_ AVN6BB_1_7_LDW_WARNING_ON_OFF : 15|1@1+ (1,0) [0|1] ""  C_ECU_GW
 SG_ AVN6BB_0_0_CHECK_SUM : 0|8@1+ (1,0) [0|255] ""  C_ECU,C_ECU_GW

BO_ 1722 AVN6BA: 8 CCU
 SG_ AVN6BA_7_0_GUIDE_LINE_REAR : 56|1@1+ (1,0) [0|1] ""  C_ECU_GW
 SG_ AVN6BA_7_1_GUIDE_LINE_SIDE : 57|1@1+ (1,0) [0|1] ""  C_ECU_GW
 SG_ AVN6BA_7_2_GUIDE_LINE_FRONT : 58|1@1+ (1,0) [0|1] ""  C_ECU_GW
 SG_ AVN6BA_7_3_STEER_ANGLE_INTERLOCK : 59|1@1+ (1,0) [0|1] ""  C_ECU_GW
 SG_ AVN6BA_7_4_BACK_CAMERA_DELAY : 60|1@1+ (1,0) [0|1] ""  C_ECU_GW
 SG_ AVN6BA_7_5_REQ_STOP_CAMERA_OUT : 61|1@1+ (1,0) [0|1] ""  C_ECU_GW
 SG_ AVN6BA_7_6_VIEW_CHANGE_SW : 62|2@1+ (1,0) [0|3] ""  C_ECU_GW
 SG_ AVN6BA_6_0_CLIMAITE_PA_TEMP : 48|6@1- (0.5,13) [1|44] "℃/?"  C_ECU_GW
 SG_ AVN6BA_6_6_CLIMATE_SYNC : 54|1@1+ (1,0) [0|1] ""  C_ECU_GW
 SG_ AVN6BA_6_7_CLIMATE_F_DEF : 55|1@1+ (1,0) [0|1] ""  C_ECU_GW
 SG_ AVN6BA_5_0_CLIMAITE_DR_TEMP : 40|6@1- (0.5,13) [1|44] "℃/?"  C_ECU_GW
 SG_ AVN6BA_5_6_CLIMAITE_AUTO : 46|1@1+ (1,0) [0|1] ""  C_ECU_GW
 SG_ AVN6BA_5_7_CLIMAITE_MAX_AC : 47|1@1+ (1,0) [0|1] ""  C_ECU_GW
 SG_ AVN6BA_4_0_CLIMAITE_VR : 32|3@1+ (1,0) [0|4] ""  C_ECU_GW
 SG_ AVN6BA_4_3_CLIMATE_AC : 35|1@1+ (1,0) [0|1] ""  C_ECU_GW
 SG_ AVN6BA_4_4_CLIMAITE_FAN : 36|4@1+ (1,0) [0|15] ""  C_ECU_GW
 SG_ AVN6BA_3_0_PERSONAL_IC_SH : 24|3@1+ (1,0) [0|7] ""  C_ECU_GW
 SG_ AVN6BA_3_4_CSTM_SONNER : 28|1@1+ (1,0) [0|1] ""  C_ECU_GW
 SG_ AVN6BA_3_5_CSTM_RAB : 29|1@1+ (1,0) [0|1] ""  C_ECU_GW
 SG_ AVN6BA_3_6_REQ_CHG_CSTM_RAB : 30|1@1+ (1,0) [0|1] ""  C_ECU_GW
 SG_ AVN6BA_3_7_CLIMATE_R_DEF : 31|1@1+ (1,0) [0|1] ""  C_ECU_GW
 SG_ AVN6BA_2_0_CLIMATE_PTC : 16|1@1+ (1,0) [0|1] ""  C_ECU_GW
 SG_ AVN6BA_2_1_CLIMATE_MODE : 17|1@1+ (1,0) [0|1] ""  C_ECU_GW
 SG_ AVN6BA_2_2_CLIMATE_SEAT_C_L : 18|1@1+ (1,0) [0|1] ""  C_ECU_GW
 SG_ AVN6BA_2_3_CLIMATE_SEAT_C_R : 19|1@1+ (1,0) [0|1] ""  C_ECU_GW
 SG_ AVN6BA_2_4_CLIMATE_SEAT_H_L : 20|1@1+ (1,0) [0|1] ""  C_ECU_GW
 SG_ AVN6BA_2_5_CLIMATE_SEAT_H_R : 21|1@1+ (1,0) [0|1] ""  C_ECU_GW
 SG_ AVN6BA_2_6_CLIMATE_INNER_AIR : 22|1@1+ (1,0) [0|1] ""  C_ECU_GW
 SG_ AVN6BA_2_7_CLIMATE_ON_OFF : 23|1@1+ (1,0) [0|1] ""  C_ECU_GW
 SG_ AVN6BA_1_0_MSG_COUNTER : 8|4@1+ (1,0) [0|15] ""  C_ECU_GW
 SG_ AVN6BA_1_4_CLIMAITE_STATUS : 12|3@1+ (1,0) [0|7] ""  C_ECU_GW
 SG_ AVN6BA_1_7_CLIMAITE_ON_OFF : 15|1@1+ (1,0) [0|1] ""  C_ECU_GW
 SG_ AVN6BA_0_0_CHECK_SUM : 0|8@1+ (1,0) [0|255] ""  C_ECU_GW

BO_ 1713 AVN6B1: 8 CCU
 SG_ AVN6B1_7_1_PRESENT_YEAR : 57|7@1+ (1,0) [0|126] "Year"  C_ECU,C_ECU_GW
 SG_ AVN6B1_6_0_PRESENT_DAY : 48|5@1+ (1,0) [1|31] "Day"  C_ECU,C_ECU_GW
 SG_ AVN6B1_6_5_PRESENT_MONTH : 53|4@1+ (1,0) [1|12] "Month"  C_ECU,C_ECU_GW
 SG_ AVN6B1_5_0_FAIL_AVN : 40|1@1+ (1,0) [0|1] ""  C_ECU_GW
 SG_ AVN6B1_5_1_IN_OPERATION : 41|1@1+ (1,0) [0|1] ""  C_ECU_GW
 SG_ AVN6B1_5_2_TYPE_NAVI : 42|2@1+ (1,0) [0|3] ""  C_ECU_GW
 SG_ AVN6B1_5_4_XM_ENABLE : 44|2@1+ (1,0) [0|3] ""  C_ECU_GW
 SG_ AVN6B1_5_6_FLG_ABLE_WELCOME_SCL : 46|1@1+ (1,0) [0|1] ""  C_ECU_GW
 SG_ AVN6B1_5_7_STEER_ANGLE_INTERLOCK : 47|1@1+ (1,0) [0|1] ""  C_ECU_GW
 SG_ AVN6B1_4_0_PRESENT_TIME_SEC : 32|6@1+ (1,0) [0|59] "s"  C_ECU,C_ECU_GW
 SG_ AVN6B1_4_7_BACK_CAMERA_DELAY : 39|1@1+ (1,0) [0|1] ""  C_ECU_GW
 SG_ AVN6B1_3_0_PRESENT_TIME_MIN : 24|6@1+ (1,0) [0|59] "m"  C_ECU,C_ECU_GW
 SG_ AVN6B1_3_7_MVS_FTSNR_INTERRUPT : 31|1@1+ (1,0) [0|1] ""  C_ECU_GW
 SG_ AVN6B1_2_0_GPS_CLOCK_FLG : 16|1@1+ (1,0) [0|1] ""  C_ECU_GW
 SG_ AVN6B1_2_1_PRESENT_TIME_HOUR : 17|5@1+ (1,0) [0|23] "h"  C_ECU,C_ECU_GW
 SG_ AVN6B1_2_6_TIME_FORMAT : 22|2@1+ (1,0) [0|3] ""  C_ECU_GW
 SG_ AVN6B1_1_0_MSG_COUNTER : 8|4@1+ (1,0) [0|15] ""  C_ECU,C_ECU_GW
 SG_ AVN6B1_1_4_WAKE_UP_FRAME : 12|1@1+ (1,0) [0|1] ""  C_ECU_GW
 SG_ AVN6B1_1_5_REQ_COMM_CONT : 13|1@1+ (1,0) [0|1] ""  C_ECU_GW
 SG_ AVN6B1_1_6_ACTIVE_AVN_CSTM : 14|1@1+ (1,0) [0|1] ""  C_ECU_GW
 SG_ AVN6B1_1_7_REQ_STOP_CAMERA_OUT : 15|1@1+ (1,0) [0|1] ""  C_ECU_GW
 SG_ AVN6B1_0_0_CHECK_SUM : 0|8@1+ (1,0) [0|255] ""  C_ECU,C_ECU_GW

BO_ 1019 AVN3FB: 8 CCU
 SG_ AVN3FB_7_0_SMT_TIM_RESET_REQ : 56|1@1+ (1,0) [0|1] ""  C_ECU_GW
 SG_ AVN3FB_7_1_SMT_EG_CSTM_REQ : 57|1@1+ (1,0) [0|1] ""  C_ECU_GW
 SG_ AVN3FB_7_2_EYE_YEILD_CSTM : 58|1@1+ (1,0) [0|1] ""  C_ECU_GW
 SG_ AVN3FB_7_3_EYE_STOP_CSTM : 59|1@1+ (1,0) [0|1] ""  C_ECU_GW
 SG_ AVN3FB_7_4_EYE_NO_ENTRY_CSTM : 60|1@1+ (1,0) [0|1] ""  C_ECU_GW
 SG_ AVN3FB_7_5_MVS_CAMERA_SELECT_SW : 61|1@1+ (1,0) [0|1] ""  C_ECU_GW
 SG_ AVN3FB_7_7_ACPANEL_DR_ONLY : 63|1@1+ (1,0) [0|1] ""  C_ECU_GW
 SG_ AVN3FB_6_0_ACPANEL_PA_TEMP : 48|6@1+ (0.5,13) [1|44] "℃/?"  C_ECU,C_ECU_GW
 SG_ AVN3FB_6_6_ACPANEL_MODE_DOWN : 54|1@1+ (1,0) [0|1] ""  C_ECU_GW
 SG_ AVN3FB_6_7_ACPANEL_MODE_UP : 55|1@1+ (1,0) [0|1] ""  C_ECU_GW
 SG_ AVN3FB_5_0_ACPANEL_DR_TEMP : 40|6@1+ (0.5,13) [1|44] "℃/?"  C_ECU,C_ECU_GW
 SG_ AVN3FB_5_6_ACPANEL_FAN_DOWN : 46|1@1+ (1,0) [0|1] ""  C_ECU,C_ECU_GW
 SG_ AVN3FB_5_7_ACPANEL_FAN_UP : 47|1@1+ (1,0) [0|1] ""  C_ECU,C_ECU_GW
 SG_ AVN3FB_4_0_ACPANEL_FAN_LEVEL : 32|4@1+ (1,0) [0|15] ""  C_ECU,C_ECU_GW
 SG_ AVN3FB_4_4_ACPANEL_MODE_VENT : 36|4@1+ (1,0) [0|15] ""  C_ECU_GW
 SG_ AVN3FB_3_0_ACPANEL_PA_TEMP_DOWN : 24|1@1+ (1,0) [0|1] ""  C_ECU,C_ECU_GW
 SG_ AVN3FB_3_1_ACPANEL_PA_TEMP_UP : 25|1@1+ (1,0) [0|1] ""  C_ECU,C_ECU_GW
 SG_ AVN3FB_3_2_ACPANEL_DR_TEMP_DOWN : 26|1@1+ (1,0) [0|1] ""  C_ECU,C_ECU_GW
 SG_ AVN3FB_3_3_ACPANEL_DR_TEMP_UP : 27|1@1+ (1,0) [0|1] ""  C_ECU,C_ECU_GW
 SG_ AVN3FB_3_4_ACPANEL_SYNC : 28|1@1+ (1,0) [0|1] ""  C_ECU_GW
 SG_ AVN3FB_3_5_ACPANEL_AC : 29|1@1+ (1,0) [0|1] ""  C_ECU_GW
 SG_ AVN3FB_3_6_F_DEF_SW : 30|1@1+ (1,0) [0|1] ""  C_ECU_GW
 SG_ AVN3FB_3_7_R_DEF_SW : 31|1@1+ (1,0) [0|1] ""  C_ECU_GW
 SG_ AVN3FB_2_0_ACPANEL_AUTO : 16|1@1+ (1,0) [0|1] ""  C_ECU_GW
 SG_ AVN3FB_2_1_ACPANEL_MAX_AC : 17|1@1+ (1,0) [0|1] ""  C_ECU_GW
 SG_ AVN3FB_2_2_ACPANEL_SEAT_C_P : 18|1@1+ (1,0) [0|1] ""  C_ECU_GW
 SG_ AVN3FB_2_3_ACPANEL_SEAT_C_D : 19|1@1+ (1,0) [0|1] ""  C_ECU_GW
 SG_ AVN3FB_2_4_ACPANEL_SEAT_H_P : 20|1@1+ (1,0) [0|1] ""  C_ECU_GW
 SG_ AVN3FB_2_5_ACPANEL_SEAT_H_D : 21|1@1+ (1,0) [0|1] ""  C_ECU_GW
 SG_ AVN3FB_2_6_ACPANEL_INNER_AIR : 22|1@1+ (1,0) [0|1] ""  C_ECU_GW
 SG_ AVN3FB_2_7_ACPANEL_AC_ON_OFF : 23|1@1+ (1,0) [0|1] ""  C_ECU,C_ECU_GW
 SG_ AVN3FB_1_0_MSG_COUNTER : 8|4@1+ (1,0) [0|15] ""  C_ECU_GW
 SG_ AVN3FB_1_4_EYE_CSTM_REQ_3FB : 12|1@1+ (1,0) [0|1] ""  C_ECU_GW
 SG_ AVN3FB_1_5_DDAW_WARNING_CSTM : 13|1@1+ (1,0) [0|1] ""  C_ECU_GW
 SG_ AVN3FB_1_6_SIGN_SWITCH_SND : 14|1@1+ (1,0) [0|1] ""  C_ECU_GW
 SG_ AVN3FB_1_7_SLWF_CSTM : 15|1@1+ (1,0) [0|1] ""  C_ECU_GW
 SG_ AVN3FB_0_0_CHECK_SUM : 0|8@1+ (1,0) [0|255] ""  C_ECU_GW

BO_ 1299 AVN513: 8 CCU
 SG_ AVN513_1_4_ActiveWakeUpBit : 12|1@0+ (1,0) [0|1] ""  DCM,C_ECU
 SG_ AVN513_0_0_SourceNodeID : 7|8@0+ (1,0) [0|255] ""  DCM,C_ECU

BO_ 1696 AIL6A0: 8 C_ECU_GW
 SG_ AIL6A0_7_0_AIL_RENDER_STA : 56|3@1+ (1,0) [0|7] ""  CCU
 SG_ AIL6A0_7_3_AIL_RENDER_PAT_A_DIS : 59|1@1+ (1,0) [0|1] ""  CCU
 SG_ AIL6A0_7_4_AIL_RENDER_PAT_B_DIS : 60|1@1+ (1,0) [0|1] ""  CCU
 SG_ AIL6A0_7_5_AIL_RENDER_PAT_C_DIS : 61|1@1+ (1,0) [0|1] ""  CCU
 SG_ AIL6A0_7_6_AIL_RENDER_PAT_D_DIS : 62|1@1+ (1,0) [0|1] ""  CCU
 SG_ AIL6A0_7_7_AIL_RENDER_DR_MD_DIS : 63|1@1+ (1,0) [0|1] ""  CCU
 SG_ AIL6A0_6_0_AIL_FIRST_BRIGHT_STA : 48|4@1+ (1,0) [0|9] ""  CCU
 SG_ AIL6A0_6_4_AIL_SECOND_BRIGHT_STA : 52|4@1+ (1,0) [0|15] ""  CCU
 SG_ AIL6A0_5_0_AIL_SECOND_COLOR_STA : 40|6@1+ (1,0) [0|63] ""  CCU
 SG_ AIL6A0_5_6_AIL_CSTM_PRS_DIS_REQ : 46|1@1+ (1,0) [0|1] ""  CCU
 SG_ AIL6A0_5_7_AIL_RENDER_CSTM_DIS : 47|1@1+ (1,0) [0|1] ""  CCU
 SG_ AIL6A0_4_0_AIL_FIRST_COLOR_STA : 32|6@1+ (1,0) [0|63] ""  CCU
 SG_ AIL6A0_4_6_AIL_SECOND_COLOR_DIS : 38|1@1+ (1,0) [0|1] ""  CCU
 SG_ AIL6A0_4_7_AIL_SECOND_BRIGHT_DIS : 39|1@1+ (1,0) [0|1] ""  CCU
 SG_ AIL6A0_3_0_AIL_ADAS_VEH_DIS_STA : 24|1@1+ (1,0) [0|1] ""  CCU
 SG_ AIL6A0_3_1_AIL_ADAS_VEH_DIS__DIS : 25|1@1+ (1,0) [0|1] ""  CCU
 SG_ AIL6A0_3_2_AIL_ADAS_LANE_DEV_STA : 26|1@1+ (1,0) [0|1] ""  CCU
 SG_ AIL6A0_3_3_AIL_ADAS_LANE_DEV_DIS : 27|1@1+ (1,0) [0|1] ""  CCU
 SG_ AIL6A0_3_4_AIL_ADAS_FT_CROSS_STA : 28|1@1+ (1,0) [0|1] ""  CCU
 SG_ AIL6A0_3_5_AIL_ADAS_FT_CROSS_DIS : 29|1@1+ (1,0) [0|1] ""  CCU
 SG_ AIL6A0_3_6_AIL_ADAS_HANDS_FR_STA : 30|1@1+ (1,0) [0|1] ""  CCU
 SG_ AIL6A0_3_7_AIL_ADAS_HANDS_FR_DIS : 31|1@1+ (1,0) [0|1] ""  CCU
 SG_ AIL6A0_2_0_AIL_ADAS_EXP_STA : 16|1@1+ (1,0) [0|1] ""  CCU
 SG_ AIL6A0_2_1_AIL_ADAS_EXP_DIS : 17|1@1+ (1,0) [0|1] ""  CCU
 SG_ AIL6A0_2_2_AIL_NOTIFI_EXP_STA : 18|1@1+ (1,0) [0|1] ""  CCU
 SG_ AIL6A0_2_3_AIL_NOTIFI_EXP_DIS : 19|1@1+ (1,0) [0|1] ""  CCU
 SG_ AIL6A0_2_4_AIL_AIR_CON_EXP_STA : 20|1@1+ (1,0) [0|1] ""  CCU
 SG_ AIL6A0_2_5_AIL_AIR_CON_EXP_DIS : 21|1@1+ (1,0) [0|1] ""  CCU
 SG_ AIL6A0_1_0_MSG_COUNTER : 8|4@1+ (1,0) [0|15] ""  CCU
 SG_ AIL6A0_1_4_AIL_ON_OFF_STA : 12|1@1+ (1,0) [0|1] ""  CCU
 SG_ AIL6A0_1_6_AIL_WEL_FOL_STA : 14|1@1+ (1,0) [0|1] ""  CCU
 SG_ AIL6A0_1_7_AIL_WEL_FOL_DIS : 15|1@1+ (1,0) [0|1] ""  CCU
 SG_ AIL6A0_0_0_CHECK_SUM : 0|8@1+ (1,0) [0|255] ""  CCU

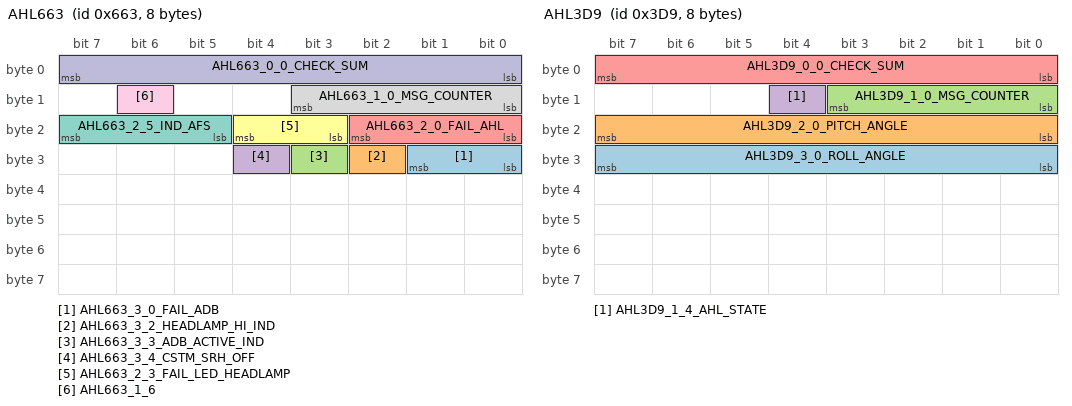
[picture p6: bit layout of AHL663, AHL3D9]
BO_ 1635 AHL663: 8 C_ECU_GW
 SG_ AHL663_3_0_FAIL_ADB : 24|2@1+ (1,0) [0|3] "" Vector__XXX
 SG_ AHL663_3_2_HEADLAMP_HI_IND : 26|1@1+ (1,0) [0|1] "" Vector__XXX
 SG_ AHL663_3_3_ADB_ACTIVE_IND : 27|1@1+ (1,0) [0|1] "" Vector__XXX
 SG_ AHL663_3_4_CSTM_SRH_OFF : 28|1@1+ (1,0) [0|1] ""  CCU
 SG_ AHL663_2_0_FAIL_AHL : 16|3@1+ (1,0) [0|7] "" Vector__XXX
 SG_ AHL663_2_3_FAIL_LED_HEADLAMP : 19|2@1+ (1,0) [0|3] "" Vector__XXX
 SG_ AHL663_2_5_IND_AFS : 21|3@1+ (1,0) [0|7] "" Vector__XXX
 SG_ AHL663_1_0_MSG_COUNTER : 8|4@1+ (1,0) [0|15] ""  CCU
 SG_ AHL663_1_6 : 14|1@1+ (1,0) [0|1] "" Vector__XXX
 SG_ AHL663_0_0_CHECK_SUM : 0|8@1+ (1,0) [0|255] ""  CCU

BO_ 985 AHL3D9: 8 C_ECU_GW
 SG_ AHL3D9_3_0_ROLL_ANGLE : 24|8@1- (1,0) [-65|65] "deg"  CCU
 SG_ AHL3D9_2_0_PITCH_ANGLE : 16|8@1- (1,0) [-65|65] "deg"  CCU
 SG_ AHL3D9_1_0_MSG_COUNTER : 8|4@1+ (1,0) [0|15] ""  CCU
 SG_ AHL3D9_1_4_AHL_STATE : 12|1@1+ (1,0) [0|1] "" Vector__XXX
 SG_ AHL3D9_0_0_CHECK_SUM : 0|8@1+ (1,0) [0|255] ""  CCU

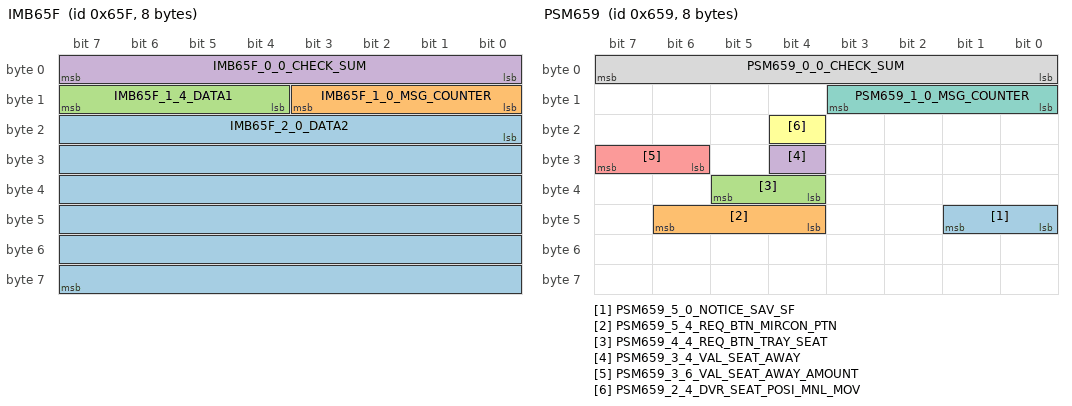
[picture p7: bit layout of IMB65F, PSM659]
BO_ 1631 IMB65F: 8 C_ECU_GW
 SG_ IMB65F_2_0_DATA2 : 16|48@1+ (1,0) [0|281474976710660] ""  DCM
 SG_ IMB65F_1_0_MSG_COUNTER : 8|4@1+ (1,0) [0|15] ""  DCM
 SG_ IMB65F_1_4_DATA1 : 12|4@1+ (1,0) [0|15] ""  DCM
 SG_ IMB65F_0_0_CHECK_SUM : 0|8@1+ (1,0) [0|255] ""  DCM

BO_ 1626 PSM65A: 8 Vector__XXX

BO_ 1625 PSM659: 8 C_ECU
 SG_ PSM659_5_0_NOTICE_SAV_SF : 40|2@1+ (1,0) [0|7] ""  CCU
 SG_ PSM659_5_4_REQ_BTN_MIRCON_PTN : 44|3@1+ (1,0) [0|7] ""  CCU
 SG_ PSM659_4_4_REQ_BTN_TRAY_SEAT : 36|2@1+ (1,0) [0|3] "" Vector__XXX
 SG_ PSM659_3_4_VAL_SEAT_AWAY : 28|1@1+ (1,0) [0|1] ""  CCU
 SG_ PSM659_3_6_VAL_SEAT_AWAY_AMOUNT : 30|2@1+ (1,0) [0|3] ""  CCU
 SG_ PSM659_2_4_DVR_SEAT_POSI_MNL_MOV : 20|1@1+ (1,0) [0|1] ""  CCU
 SG_ PSM659_1_0_MSG_COUNTER : 8|4@1+ (1,0) [0|15] ""  CCU
 SG_ PSM659_0_0_CHECK_SUM : 0|8@1+ (1,0) [0|255] ""  CCU

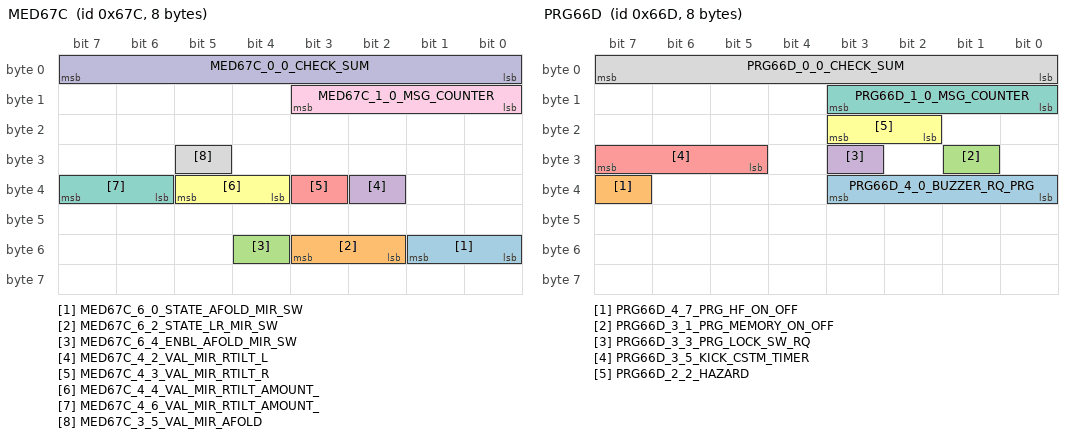
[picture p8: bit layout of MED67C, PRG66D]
BO_ 1660 MED67C: 8 C_ECU
 SG_ MED67C_6_0_STATE_AFOLD_MIR_SW : 48|2@1+ (1,0) [0|3] ""  CCU
 SG_ MED67C_6_2_STATE_LR_MIR_SW : 50|2@1+ (1,0) [0|3] ""  CCU
 SG_ MED67C_6_4_ENBL_AFOLD_MIR_SW : 52|1@1+ (1,0) [0|1] ""  CCU
 SG_ MED67C_4_2_VAL_MIR_RTILT_L : 34|1@1+ (1,0) [0|1] ""  CCU
 SG_ MED67C_4_3_VAL_MIR_RTILT_R : 35|1@1+ (1,0) [0|1] ""  CCU
 SG_ MED67C_4_4_VAL_MIR_RTILT_AMOUNT_ : 36|2@1+ (1,0) [0|3] "" Vector__XXX
 SG_ MED67C_4_6_VAL_MIR_RTILT_AMOUNT_ : 38|2@1+ (1,0) [0|3] "" Vector__XXX
 SG_ MED67C_3_5_VAL_MIR_AFOLD : 29|1@1+ (1,0) [0|1] ""  CCU
 SG_ MED67C_1_0_MSG_COUNTER : 8|4@1+ (1,0) [0|15] ""  CCU
 SG_ MED67C_0_0_CHECK_SUM : 0|8@1+ (1,0) [0|255] ""  CCU

BO_ 1645 PRG66D: 8 C_ECU
 SG_ PRG66D_4_0_BUZZER_RQ_PRG : 32|4@1+ (1,0) [0|15] "" Vector__XXX
 SG_ PRG66D_4_7_PRG_HF_ON_OFF : 39|1@1+ (1,0) [0|1] ""  CCU
 SG_ PRG66D_3_1_PRG_MEMORY_ON_OFF : 25|1@1+ (1,0) [0|1] ""  CCU
 SG_ PRG66D_3_3_PRG_LOCK_SW_RQ : 27|1@1+ (1,0) [0|1] "" Vector__XXX
 SG_ PRG66D_3_5_KICK_CSTM_TIMER : 29|3@1+ (1,0) [0|7] "" Vector__XXX
 SG_ PRG66D_2_2_HAZARD : 18|2@1+ (1,0) [0|3] ""  CCU
 SG_ PRG66D_1_0_MSG_COUNTER : 8|4@1+ (1,0) [0|15] ""  CCU
 SG_ PRG66D_0_0_CHECK_SUM : 0|8@1+ (1,0) [0|255] ""  CCU

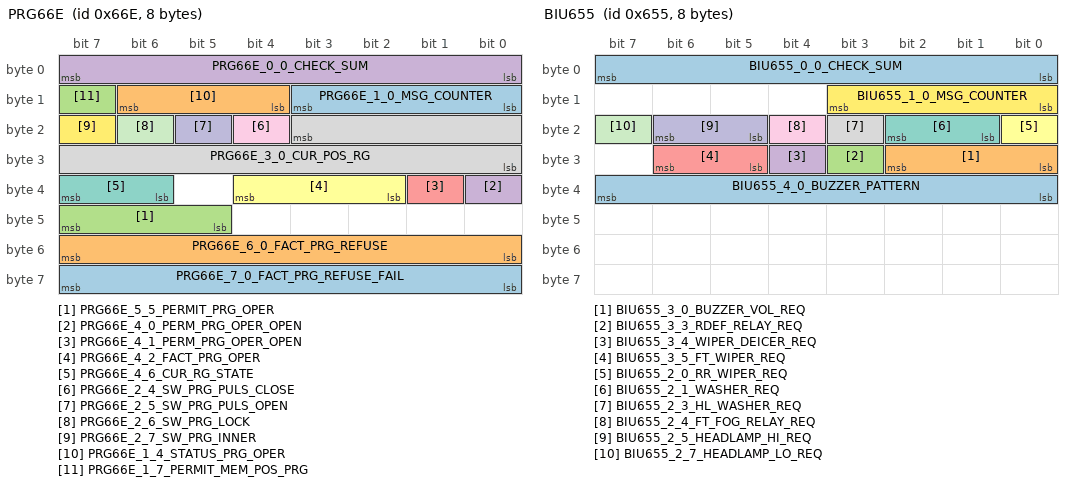
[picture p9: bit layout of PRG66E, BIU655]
BO_ 1646 PRG66E: 8 C_ECU_GW
 SG_ PRG66E_7_0_FACT_PRG_REFUSE_FAIL : 63|8@0+ (1,0) [0|255] "" Vector__XXX
 SG_ PRG66E_6_0_FACT_PRG_REFUSE : 55|8@0+ (1,0) [0|255] "" Vector__XXX
 SG_ PRG66E_5_5_PERMIT_PRG_OPER : 47|3@0+ (1,0) [0|7] "" Vector__XXX
 SG_ PRG66E_4_0_PERM_PRG_OPER_OPEN : 32|1@0+ (1,0) [0|1] "" Vector__XXX
 SG_ PRG66E_4_1_PERM_PRG_OPER_OPEN : 33|1@0+ (1,0) [0|1] "" Vector__XXX
 SG_ PRG66E_4_2_FACT_PRG_OPER : 36|3@0+ (1,0) [0|7] "" Vector__XXX
 SG_ PRG66E_4_6_CUR_RG_STATE : 39|2@0+ (1,0) [0|3] "" Vector__XXX
 SG_ PRG66E_3_0_CUR_POS_RG : 19|12@0+ (1,0) [0|4095] "" Vector__XXX
 SG_ PRG66E_2_4_SW_PRG_PULS_CLOSE : 20|1@0+ (1,0) [0|1] "" Vector__XXX
 SG_ PRG66E_2_5_SW_PRG_PULS_OPEN : 21|1@0+ (1,0) [0|1] "" Vector__XXX
 SG_ PRG66E_2_6_SW_PRG_LOCK : 22|1@0+ (1,0) [0|1] "" Vector__XXX
 SG_ PRG66E_2_7_SW_PRG_INNER : 23|1@0+ (1,0) [0|1] "" Vector__XXX
 SG_ PRG66E_1_0_MSG_COUNTER : 11|4@0+ (1,0) [0|15] ""  CCU
 SG_ PRG66E_1_4_STATUS_PRG_OPER : 14|3@0+ (1,0) [0|7] ""  CCU
 SG_ PRG66E_1_7_PERMIT_MEM_POS_PRG : 15|1@0+ (1,0) [0|1] "" Vector__XXX
 SG_ PRG66E_0_0_CHECK_SUM : 7|8@0+ (1,0) [0|255] ""  CCU

BO_ 818 PMN332: 8 C_ECU_GW
 SG_ PMN332_7_0_RES_CONTROL_STATUS : 56|2@1+ (1,0) [0|3] "" Vector__XXX
 SG_ PMN332_7_2_REQ_RES_P_LOCK : 58|1@1+ (1,0) [0|1] "" Vector__XXX
 SG_ PMN332_7_5_IGB_RELAY_REQ : 61|1@1+ (1,0) [0|1] "" Vector__XXX
 SG_ PMN332_7_6_IGA_RELAY_REQ : 62|1@1+ (1,0) [0|1] "" Vector__XXX
 SG_ PMN332_7_7_REQ_STOP_RES : 63|1@1+ (1,0) [0|1] "" Vector__XXX
 SG_ PMN332_6_0_RES_IDLE_TIME : 48|7@1+ (10,0) [0|1270] "sec" Vector__XXX
 SG_ PMN332_6_7_CUST : 55|1@1+ (1,0) [0|1] ""  CCU
 SG_ PMN332_5_0_PUSHSTART_SW : 40|1@1+ (1,0) [0|1] "" Vector__XXX
 SG_ PMN332_5_1_SIG_KEY_PUSHSTART : 41|1@1+ (1,0) [0|1] "" Vector__XXX
 SG_ PMN332_5_2_STATE_MODE_POWER : 42|2@1+ (1,0) [0|2] "" Vector__XXX
 SG_ PMN332_5_4_BUZ_2SHOT_IN : 44|1@1+ (1,0) [0|1] "" Vector__XXX
 SG_ PMN332_5_5_BUZ_INTERMIT1_IN : 45|1@1+ (1,0) [0|1] "" Vector__XXX
 SG_ PMN332_5_6_BUZ_INTERMIT2_IN : 46|1@1+ (1,0) [0|1] "" Vector__XXX
 SG_ PMN332_5_7_BUZ_CONTINUE_IN : 47|1@1+ (1,0) [0|1] "" Vector__XXX
 SG_ PMN332_2_0_WARN_SSP_SIG1 : 16|1@1+ (1,0) [0|1] "" Vector__XXX
 SG_ PMN332_2_1_WARN_SSP_SIG2 : 17|3@1+ (1,0) [0|4] ""  CCU
 SG_ PMN332_2_4_SMT_PWR_SIG : 20|2@1+ (1,0) [0|2] "" Vector__XXX
 SG_ PMN332_2_7_BUZ_1SHOT_IN : 23|1@1+ (1,0) [0|1] "" Vector__XXX
 SG_ PMN332_1_0_MSG_COUNTER : 8|4@1+ (1,0) [0|15] ""  CCU
 SG_ PMN332_0_0_CHECK_SUM : 0|8@1+ (1,0) [0|255] ""  CCU

BO_ 816 SMT330: 8 C_ECU_GW
 SG_ SMT330_7_0 : 56|1@1+ (1,0) [0|1] "" Vector__XXX
 SG_ SMT330_7_1 : 57|1@1+ (1,0) [0|1] "" Vector__XXX
 SG_ SMT330_7_3_HF_CAPA_ERR_ST : 59|1@1+ (1,0) [0|1] "" Vector__XXX
 SG_ SMT330_7_6_HF_RESP_ERR_ST : 62|1@1+ (1,0) [0|1] "" Vector__XXX
 SG_ SMT330_6_0_REQ_MESS_PUSHSTART : 48|4@1+ (1,0) [0|8] "" Vector__XXX
 SG_ SMT330_6_4_WARN_SSP_SIG1 : 52|4@1+ (1,0) [0|14] "" Vector__XXX
 SG_ SMT330_5_1_WIUL_CUST : 41|1@1+ (1,0) [0|1] ""  CCU
 SG_ SMT330_5_2_WAL_CUST : 42|1@1+ (1,0) [0|1] ""  CCU
 SG_ SMT330_5_3_WARN_SSP_SIG2 : 43|2@1+ (1,0) [0|2] "" Vector__XXX
 SG_ SMT330_5_5_WARN_SSP_SIG3 : 45|3@1+ (1,0) [0|4] "" Vector__XXX
 SG_ SMT330_4_0_PUSHSTART_SW : 32|1@1+ (1,0) [0|1] "" Vector__XXX
 SG_ SMT330_4_1_SIG_KEY_PUSHSTART : 33|1@1+ (1,0) [0|1] "" Vector__XXX
 SG_ SMT330_4_2_HF_TOUCH_STATUS : 34|3@1+ (1,0) [0|7] "" Vector__XXX
 SG_ SMT330_4_5_HF_KICK_STATUS : 37|2@1+ (1,0) [0|17] "" Vector__XXX
 SG_ SMT330_3_0_BUZ_1SHOT_IN : 24|1@1+ (1,0) [0|1] "" Vector__XXX
 SG_ SMT330_3_1_BUZ_2SHOT_IN : 25|1@1+ (1,0) [0|1] "" Vector__XXX
 SG_ SMT330_3_2_BUZ_INTERMIT1_IN : 26|1@1+ (1,0) [0|1] "" Vector__XXX
 SG_ SMT330_3_3_BUZ_INTERMIT2_IN : 27|1@1+ (1,0) [0|1] "" Vector__XXX
 SG_ SMT330_3_4_BUZ_CONTINUE_IN : 28|1@1+ (1,0) [0|1] "" Vector__XXX
 SG_ SMT330_3_5_BUZ_TRPON_OK_IN : 29|1@1+ (1,0) [0|1] "" Vector__XXX
 SG_ SMT330_3_6_STATE_MODE_POWER : 30|2@1+ (1,0) [0|2] "" Vector__XXX
 SG_ SMT330_1_0_MSG_COUNTER : 8|4@1+ (1,0) [0|15] ""  CCU
 SG_ SMT330_1_4_WAKE_UP_FRAME : 12|1@1+ (1,0) [0|1] "" Vector__XXX
 SG_ SMT330_1_5_REQ_COMM_CONT : 13|1@1+ (1,0) [0|1] "" Vector__XXX
 SG_ SMT330_1_6 : 14|1@1+ (1,0) [0|1] "" Vector__XXX
 SG_ SMT330_0_0_CHECK_SUM : 0|8@1+ (1,0) [0|255] ""  CCU

BO_ 1622 BIU656: 8 C_ECU_GW
 SG_ BIU656_6_0_KICK_OPEN_REQ_PRG : 48|1@1+ (1,0) [0|1] "" Vector__XXX
 SG_ BIU656_6_1_KICK_CLOSE_REQ_PRG : 49|1@1+ (1,0) [0|1] "" Vector__XXX
 SG_ BIU656_6_6_CARGO_LAMP_OUT : 54|1@1+ (1,0) [0|1] "" Vector__XXX
 SG_ BIU656_6_7_PERMITT_KEY_RG_UNL : 55|1@1+ (1,0) [0|1] "" Vector__XXX
 SG_ BIU656_5_0_PRG_DRVR_OPENERSW : 40|1@1+ (1,0) [0|1] "" Vector__XXX
 SG_ BIU656_5_1_HF_PRG_OFF_SW : 41|1@1+ (1,0) [0|1] "" Vector__XXX
 SG_ BIU656_5_2_PERMIT_OPEN_RG : 42|1@1+ (1,0) [0|1] "" Vector__XXX
 SG_ BIU656_5_3_BUZ_ON_OFF : 43|1@1+ (1,0) [0|1] "" Vector__XXX
 SG_ BIU656_5_4_PRG_DRVR_SW_PERMIT : 44|1@1+ (1,0) [0|1] "" Vector__XXX
 SG_ BIU656_5_5_CSTM_HF_PRG_LOCK : 45|1@1+ (1,0) [0|1] "" Vector__XXX
 SG_ BIU656_5_6_CSTM_KICK_SENSOR : 46|1@1+ (1,0) [0|1] ""  CCU
 SG_ BIU656_5_7_KICK_REQ_PRG : 47|1@1+ (1,0) [0|1] "" Vector__XXX
 SG_ BIU656_4_0_NOT_SMT_KEY_RG_SW : 32|2@1+ (1,0) [0|3] "" Vector__XXX
 SG_ BIU656_4_2_SMT_KEY_RG_SW : 34|2@1+ (1,0) [0|3] "" Vector__XXX
 SG_ BIU656_4_4_OPEN_RG_OPENER_SW : 36|2@1+ (1,0) [0|3] "" Vector__XXX
 SG_ BIU656_3_4_CHECKED_KEYNO : 28|3@1+ (1,0) [0|7] "" Vector__XXX
 SG_ BIU656_3_7_LOCKSTATUS_DRVR : 31|1@1+ (1,0) [0|1] "" Vector__XXX
 SG_ BIU656_2_0_TRIG_LOCK_UNLOCK : 16|12@1+ (1,0) [0|4095] "" Vector__XXX
 SG_ BIU656_1_0_MSG_COUNTER : 8|4@1+ (1,0) [0|15] "" Vector__XXX
 SG_ BIU656_0_0_CHECK_SUM : 0|8@1+ (1,0) [0|255] "" Vector__XXX

BO_ 1621 BIU655: 8 Vector__XXX
 SG_ BIU655_4_0_BUZZER_PATTERN : 32|8@1+ (1,0) [0|240] "" Vector__XXX
 SG_ BIU655_3_0_BUZZER_VOL_REQ : 24|3@1+ (1,0) [0|7] "" Vector__XXX
 SG_ BIU655_3_3_RDEF_RELAY_REQ : 27|1@1+ (1,0) [0|1] "" Vector__XXX
 SG_ BIU655_3_4_WIPER_DEICER_REQ : 28|1@1+ (1,0) [0|1] ""  CCU
 SG_ BIU655_3_5_FT_WIPER_REQ : 29|2@1+ (1,0) [0|3] "" Vector__XXX
 SG_ BIU655_2_0_RR_WIPER_REQ : 16|1@1+ (1,0) [0|1] "" Vector__XXX
 SG_ BIU655_2_1_WASHER_REQ : 17|2@1+ (1,0) [0|3] "" Vector__XXX
 SG_ BIU655_2_3_HL_WASHER_REQ : 19|1@1+ (1,0) [0|1] "" Vector__XXX
 SG_ BIU655_2_4_FT_FOG_RELAY_REQ : 20|1@1+ (1,0) [0|1] "" Vector__XXX
 SG_ BIU655_2_5_HEADLAMP_HI_REQ : 21|2@1+ (1,0) [0|3] "" Vector__XXX
 SG_ BIU655_2_7_HEADLAMP_LO_REQ : 23|1@1+ (1,0) [0|1] "" Vector__XXX
 SG_ BIU655_1_0_MSG_COUNTER : 8|4@1+ (1,0) [0|15] "" Vector__XXX
 SG_ BIU655_0_0_CHECK_SUM : 0|8@1+ (1,0) [0|255] "" Vector__XXX

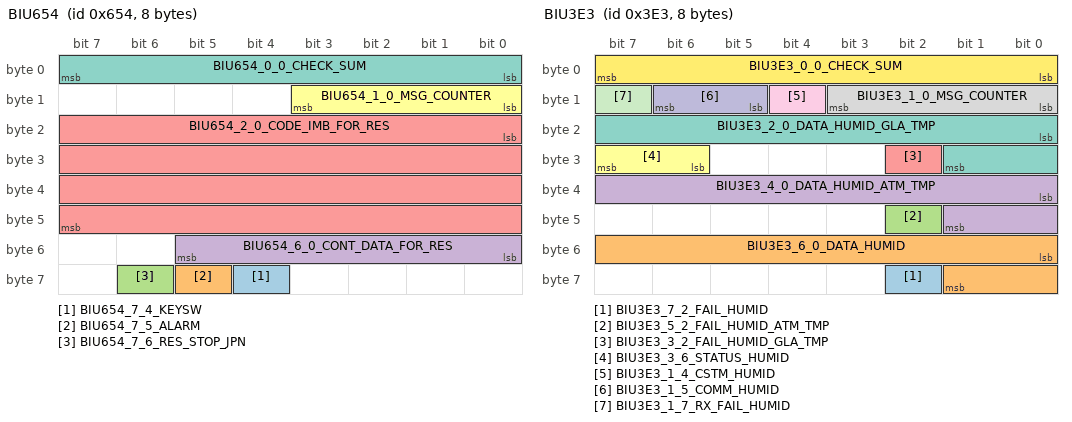
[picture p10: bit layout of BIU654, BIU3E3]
BO_ 1620 BIU654: 8 C_ECU_GW
 SG_ BIU654_7_4_KEYSW : 60|1@1+ (1,0) [0|1] "" Vector__XXX
 SG_ BIU654_7_5_ALARM : 61|1@1+ (1,0) [0|1] ""  DCM
 SG_ BIU654_7_6_RES_STOP_JPN : 62|1@1+ (1,0) [0|1] "" Vector__XXX
 SG_ BIU654_6_0_CONT_DATA_FOR_RES : 48|6@1+ (1,0) [0|63] "" Vector__XXX
 SG_ BIU654_2_0_CODE_IMB_FOR_RES : 16|32@1+ (1,0) [0|4294967295] "" Vector__XXX
 SG_ BIU654_1_0_MSG_COUNTER : 8|4@1+ (1,0) [0|15] ""  DCM
 SG_ BIU654_0_0_CHECK_SUM : 0|8@1+ (1,0) [0|255] ""  DCM

BO_ 1618 BIU652: 8 C_ECU_GW
 SG_ BIU652_7_0_IND_SECURITY_IMB : 56|8@1+ (1,0) [0|240] "" Vector__XXX
 SG_ BIU652_6_0_OCCUPATION_3RDRH : 48|1@1+ (1,0) [0|1] "" Vector__XXX
 SG_ BIU652_6_1_OCCUPATION_3RDCTR : 49|1@1+ (1,0) [0|1] "" Vector__XXX
 SG_ BIU652_6_2_OCCUPATION_3RDLH : 50|1@1+ (1,0) [0|1] "" Vector__XXX
 SG_ BIU652_6_3_OCCUPATION_RRRH : 51|1@1+ (1,0) [0|1] ""  CCU
 SG_ BIU652_6_4_OCCUPATION_RRCTR : 52|1@1+ (1,0) [0|1] ""  CCU
 SG_ BIU652_6_5_OCCUPATION_RRLH : 53|1@1+ (1,0) [0|1] ""  CCU
 SG_ BIU652_6_6_HORNHAZARD_RES_SIG : 54|1@1+ (1,0) [0|1] ""  DCM
 SG_ BIU652_6_7_OCCUPATION_DRVR : 55|1@1+ (1,0) [0|1] ""  CCU
 SG_ BIU652_5_0_STATUS_ROOMLAMP : 40|3@1+ (1,0) [0|7] "" Vector__XXX
 SG_ BIU652_5_3_HEADLAMP_SMALL : 43|1@1+ (1,0) [0|1] "" Vector__XXX
 SG_ BIU652_5_4_ALL_UNLOCK_STATE : 44|1@1+ (1,0) [0|1] ""  DCM
 SG_ BIU652_5_5_DRVR_UNLOCK_STATE : 45|1@1+ (1,0) [0|1] ""  DCM
 SG_ BIU652_5_6_ALL_LOCK_STATE : 46|1@1+ (1,0) [0|1] ""  DCM
 SG_ BIU652_4_0_TRIG_LOCK_UNLOCK : 32|8@1+ (1,0) [0|255] "" Vector__XXX
 SG_ BIU652_3_0_DOOR_DRVR : 24|1@1+ (1,0) [0|1] "" Vector__XXX
 SG_ BIU652_3_1_DOOR_PASS : 25|1@1+ (1,0) [0|1] "" Vector__XXX
 SG_ BIU652_3_2_DOOR_RRRH : 26|1@1+ (1,0) [0|1] "" Vector__XXX
 SG_ BIU652_3_3_DOOR_RRLH : 27|1@1+ (1,0) [0|1] "" Vector__XXX
 SG_ BIU652_3_4_DOOR_RG : 28|1@1+ (1,0) [0|1] ""  CCU
 SG_ BIU652_3_5_DOOR_TR : 29|1@1+ (1,0) [0|1] "" Vector__XXX
 SG_ BIU652_3_7_OPENSW_RG : 31|1@1+ (1,0) [0|1] "" Vector__XXX
 SG_ BIU652_2_0_LOCKSTATUS_DRVR : 16|1@1+ (1,0) [0|1] ""  DCM,CCU
 SG_ BIU652_2_1_LOCKSTATUS_PASS : 17|1@1+ (1,0) [0|1] ""  DCM,CCU
 SG_ BIU652_2_2_LOCKSTATUS_RRRH : 18|1@1+ (1,0) [0|1] ""  DCM,CCU
 SG_ BIU652_2_3_LOCKSTATUS_RRLH : 19|1@1+ (1,0) [0|1] ""  DCM,CCU
 SG_ BIU652_2_4_LOCKSTATUS_RG : 20|1@1+ (1,0) [0|1] ""  DCM,CCU
 SG_ BIU652_2_6_UNLOCK_DOORKEYSW : 22|1@1+ (1,0) [0|1] "" Vector__XXX
 SG_ BIU652_2_7_LOCK_DOORKEYSW : 23|1@1+ (1,0) [0|1] "" Vector__XXX
 SG_ BIU652_1_0_MSG_COUNTER : 8|4@1+ (1,0) [0|15] ""  DCM,CCU
 SG_ BIU652_0_0_CHECK_SUM : 0|8@1+ (1,0) [0|255] ""  DCM,CCU

BO_ 1617 BIU651: 8 C_ECU_GW
 SG_ BIU651_7_0_PWPOS_RL : 56|2@1+ (1,0) [0|3] ""  DCM,CCU
 SG_ BIU651_7_2_PWPOS_RR : 58|2@1+ (1,0) [0|3] ""  DCM,CCU
 SG_ BIU651_7_4_PWPOS_PASS : 60|2@1+ (1,0) [0|3] ""  DCM,CCU
 SG_ BIU651_7_6_PWPOS_DRVR : 62|2@1+ (1,0) [0|3] ""  DCM,CCU
 SG_ BIU651_6_0_IND_ACTIVE_HBA : 48|2@1+ (1,0) [0|3] ""  DCM
 SG_ BIU651_6_2_ADB_ACTIVE : 50|1@1+ (1,0) [0|1] ""  DCM,CCU
 SG_ BIU651_6_3_JUDGE_ILL : 51|1@1+ (1,0) [0|1] ""  CCU
 SG_ BIU651_6_4_TYPE_LO_BEAM : 52|2@1+ (1,0) [0|3] "" Vector__XXX
 SG_ BIU651_6_6_TYPE_HI_BEAM : 54|2@1+ (1,0) [0|3] "" Vector__XXX
 SG_ BIU651_5_0_SRF_ACTIVE : 40|1@1+ (1,0) [0|1] "" Vector__XXX
 SG_ BIU651_5_1_SRF_IND : 41|2@1+ (1,0) [0|3] "" Vector__XXX
 SG_ BIU651_5_3_SRF_LAMP_LIGHT : 43|1@1+ (1,0) [0|1] "" Vector__XXX
 SG_ BIU651_5_4_SRF_LAMP_LEFT : 44|1@1+ (1,0) [0|1] "" Vector__XXX
 SG_ BIU651_5_5_MSG_STATUS_HBA : 45|2@1+ (1,0) [0|3] "" Vector__XXX
 SG_ BIU651_5_7_IND_FAIL_HBA : 47|1@1+ (1,0) [0|1] "" Vector__XXX
 SG_ BIU651_4_0_BUZ_PATTERN : 32|4@1+ (1,0) [0|8] "" Vector__XXX
 SG_ BIU651_4_4_CSTM_OPE_ALARM : 36|2@1+ (1,0) [0|3] "" Vector__XXX
 SG_ BIU651_4_6_CSTM_HBA : 38|2@1+ (1,0) [0|3] "" Vector__XXX
 SG_ BIU651_3_0_HEADLAMP_PASS_SW : 24|1@1+ (1,0) [0|1] ""  CCU
 SG_ BIU651_3_1_HEADLAMP_AUTO_SW : 25|1@1+ (1,0) [0|1] ""  CCU
 SG_ BIU651_3_2_JUDGE_DOOR_LOCK : 26|1@1+ (1,0) [0|1] ""  CCU
 SG_ BIU651_3_3_JUDGE_DOOR_UNLOCK : 27|1@1+ (1,0) [0|1] "" Vector__XXX
 SG_ BIU651_3_4_HEADLAMP_Lo_SW : 28|1@1+ (1,0) [0|1] ""  CCU
 SG_ BIU651_3_5_HEADLAMP_HI_SW : 29|1@1+ (1,0) [0|1] ""  CCU
 SG_ BIU651_3_6_WIPER_AUTO_SW : 30|1@1+ (1,0) [0|1] ""  CCU
 SG_ BIU651_3_7_PRG_LIN_MEMORY_ON_OFF : 31|1@1+ (1,0) [0|1] "" Vector__XXX
 SG_ BIU651_2_0_CSTM_ILLUMI_SSR : 16|1@1+ (1,0) [0|1] "" Vector__XXX
 SG_ BIU651_2_1_HANDLE : 17|1@1+ (1,0) [0|1] "" Vector__XXX
 SG_ BIU651_2_2_CSTM_SMT : 18|1@1+ (1,0) [0|1] "" Vector__XXX
 SG_ BIU651_2_3_AJARDOOR_STATUS : 19|1@1+ (1,0) [0|1] "" Vector__XXX
 SG_ BIU651_2_4_ONETOUCH_LAMP_OUT : 20|1@1+ (1,0) [0|1] "" Vector__XXX
 SG_ BIU651_2_5_PRG_FAIL_FLAG : 21|1@1+ (1,0) [0|1] "" Vector__XXX
 SG_ BIU651_2_6_CSTM_PSMECU : 22|1@1+ (1,0) [0|1] "" Vector__XXX
 SG_ BIU651_2_7_STATE_REGIST_DEL : 23|1@1+ (1,0) [0|1] "" Vector__XXX
 SG_ BIU651_1_0_MSG_COUNTER : 8|4@1+ (1,0) [0|15] ""  DCM,CCU
 SG_ BIU651_1_4_SRPOS : 12|3@1+ (1,0) [0|7] ""  DCM
 SG_ BIU651_1_7_WIPER_INT_STATUS : 15|1@1+ (1,0) [0|1] ""  CCU
 SG_ BIU651_0_0_CHECK_SUM : 0|8@1+ (1,0) [0|255] ""  DCM,CCU

BO_ 995 BIU3E3: 8 C_ECU_GW
 SG_ BIU3E3_7_2_FAIL_HUMID : 58|1@1+ (1,0) [0|1] "" Vector__XXX
 SG_ BIU3E3_6_0_DATA_HUMID : 48|10@1+ (0.5,0) [0|100] "%" Vector__XXX
 SG_ BIU3E3_5_2_FAIL_HUMID_ATM_TMP : 42|1@1+ (1,0) [0|1] "" Vector__XXX
 SG_ BIU3E3_4_0_DATA_HUMID_ATM_TMP : 32|10@1+ (0.1,-40) [-40|62.3] "degC"  CCU
 SG_ BIU3E3_3_2_FAIL_HUMID_GLA_TMP : 26|1@1+ (1,0) [0|1] "" Vector__XXX
 SG_ BIU3E3_3_6_STATUS_HUMID : 30|2@1+ (1,0) [0|3] "" Vector__XXX
 SG_ BIU3E3_2_0_DATA_HUMID_GLA_TMP : 16|10@1+ (0.1,-40) [-40|62.3] "degC" Vector__XXX
 SG_ BIU3E3_1_0_MSG_COUNTER : 8|4@1+ (1,0) [0|15] "" Vector__XXX
 SG_ BIU3E3_1_4_CSTM_HUMID : 12|1@1+ (1,0) [0|1] "" Vector__XXX
 SG_ BIU3E3_1_5_COMM_HUMID : 13|2@1+ (1,0) [0|3] "" Vector__XXX
 SG_ BIU3E3_1_7_RX_FAIL_HUMID : 15|1@1+ (1,0) [0|1] "" Vector__XXX
 SG_ BIU3E3_0_0_CHECK_SUM : 0|8@1+ (1,0) [0|255] "" Vector__XXX

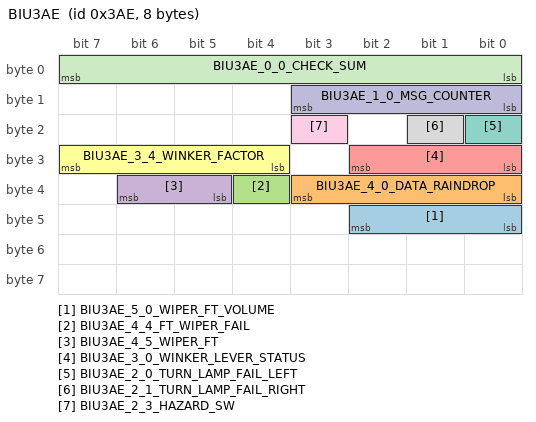
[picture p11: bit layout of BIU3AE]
BO_ 942 BIU3AE: 8 C_ECU_GW
 SG_ BIU3AE_5_0_WIPER_FT_VOLUME : 40|3@1+ (1,0) [0|5] "" Vector__XXX
 SG_ BIU3AE_4_0_DATA_RAINDROP : 32|4@1+ (1,0) [0|8] "" Vector__XXX
 SG_ BIU3AE_4_4_FT_WIPER_FAIL : 36|1@1+ (1,0) [0|1] "" Vector__XXX
 SG_ BIU3AE_4_5_WIPER_FT : 37|2@1+ (1,0) [0|3] ""  CCU
 SG_ BIU3AE_3_0_WINKER_LEVER_STATUS : 24|3@1+ (1,0) [0|5] ""  CCU
 SG_ BIU3AE_3_4_WINKER_FACTOR : 28|4@1+ (1,0) [0|15] ""  DCM,CCU
 SG_ BIU3AE_2_0_TURN_LAMP_FAIL_LEFT : 16|1@1+ (1,0) [0|1] "" Vector__XXX
 SG_ BIU3AE_2_1_TURN_LAMP_FAIL_RIGHT : 17|1@1+ (1,0) [0|1] "" Vector__XXX
 SG_ BIU3AE_2_3_HAZARD_SW : 19|1@1+ (1,0) [0|1] ""  CCU
 SG_ BIU3AE_1_0_MSG_COUNTER : 8|4@1+ (1,0) [0|15] ""  DCM
 SG_ BIU3AE_0_0_CHECK_SUM : 0|8@1+ (1,0) [0|255] ""  DCM

CM_ SG_ 914 MET392_23_0_ADD_ACNON_DRVRANG "充電後追加航続可能距離(ACN-ON)
";
CM_ SG_ 914 MET392_21_0_ADD_ACNOFF_DRVRANG "充電後追加航続可能距離(ACN-OFF)
";
CM_ SG_ 914 MET392_18_0_TRIP_LASTCHG_TOTM "TRIP LastCharge積算時間(min)
";
CM_ SG_ 914 MET392_15_0_TRIPB_TOTAL_TIME "TRIP B積算時間(min)
";
CM_ SG_ 914 MET392_12_0_TRIPA_TOTAL_TIME "TRIP A積算時間(min)
";
CM_ SG_ 914 MET392_9_0_TRIP_LASTCHARGE_KM "TRIP LastCharge(km固定)
";
CM_ SG_ 914 MET392_8_2_TRIPB_RESET "TRIP Bﾘｾｯﾄ完了通知
";
CM_ SG_ 914 MET392_6_0_TRIPB_KM "TRIP B(km固定)
";
CM_ SG_ 914 MET392_5_2_TRIPA_RESET "TRIP Aﾘｾｯﾄ完了通知
";
CM_ SG_ 914 MET392_3_0_TRIPA_KM "TRIP A(km固定)
";
CM_ SG_ 914 MET392_2_0_E2E_COUNTER "E2Eｶｳﾝﾀ
";
CM_ SG_ 914 MET392_0_0_CRC "CRC
";
CM_ SG_ 937 MET3A9_3_5_DAY_NIGHT_STATE "昼夜状態
";
CM_ SG_ 937 MET3A9_3_0_ILL_LEVEL "ｲﾙﾐ段数
";
CM_ SG_ 937 MET3A9_2_0_ILL_VALUE "ｲﾙﾐ輝度値
";
CM_ SG_ 937 MET3A9_1_7_BRIGHT_STATE "ﾌﾞﾗｲﾄ状態
";
CM_ SG_ 937 MET3A9_1_6_UI_THEME_STATE "UI Theme状態
";
CM_ SG_ 937 MET3A9_1_0_MSG_COUNTER "ﾒｯｾｰｼﾞｶｳﾝﾀ
";
CM_ SG_ 937 MET3A9_0_0_CHECKSUM "ﾁｪｯｸｻﾑ
";
CM_ SG_ 1679 MET68F_3_0_DOWNSW_STS "DOWN SW
";
CM_ SG_ 1679 MET68F_3_1_UPSW_STS "UP SW
";
CM_ SG_ 1679 MET68F_3_2_ISETSW_STS "i/SET SW
";
CM_ SG_ 1679 MET68F_3_3_MUD_SAND_SW_STS "MUD SAND SW_STS
";
CM_ SG_ 1679 MET68F_3_4_SNOW_DIRT_SW_STS "SNOW DIRT SW
";
CM_ SG_ 1679 MET68F_3_5_WIDGET_SW_STS "WIDGET SW
";
CM_ SG_ 1679 MET68F_3_6_OK_SW_STS "OK SW
";
CM_ SG_ 1679 MET68F_2_0_SIDRVSW_STS "SI-Drive/SI-DS SW
";
CM_ SG_ 1679 MET68F_1_0_MSG_COUNTER "ﾒｯｾｰｼﾞｶｳﾝﾀ
";
CM_ SG_ 1679 MET68F_0_0_CHECK_SUM "ﾁｪｯｸｻﾑ
";
CM_ SG_ 1678 MET68E_7_0_EGO_CAR_DISP_COLOR "自車表示色
";
CM_ SG_ 1678 MET68E_6_0_REDZONE_REV "REDZONE回転数
";
CM_ SG_ 1678 MET68E_5_0_CSTM_REV_SET "ﾕｰｻﾞ設定回転数
";
CM_ SG_ 1678 MET68E_4_0_CSTM_ALERT_VOL_VAL "警報音量状態値
";
CM_ SG_ 1678 MET68E_4_2_CSTM_SHIFT "ｼﾌﾄ表示設定状態値
";
CM_ SG_ 1678 MET68E_4_3_CSTM_WOW "初期演出設定状態値
";
CM_ SG_ 1678 MET68E_4_4_CSTM_GBYE "GoodBye設定状態値
";
CM_ SG_ 1678 MET68E_4_6_CSTM_WLCM "Welcome設定状態値
";
CM_ SG_ 1678 MET68E_3_0_CSTM_TEMP_UNIT "外気温単位設定値
";
CM_ SG_ 1678 MET68E_3_1_CSTM_REAR_REMIND "後席ﾘﾏｲﾝﾀﾞ 設定値
";
CM_ SG_ 1678 MET68E_3_2_SET_UNIT_OF_ELEC "MET単位 設定値(BEV)
";
CM_ SG_ 1678 MET68E_3_5_CSTM_ES_STARTBZ "先行車発進お知らせ 現在設定値
";
CM_ SG_ 1678 MET68E_3_7_CSTM_ES_CATCHBZ "先行車捕捉音 現在設定値
";
CM_ SG_ 1678 MET68E_2_0_CSTM_METUNIT "MET単位 設定値
";
CM_ SG_ 1678 MET68E_1_0_MSG_COUNTER "ﾒｯｾｰｼﾞｶｳﾝﾀ
";
CM_ SG_ 1678 MET68E_0_0_CHECK_SUM "ﾁｪｯｸｻﾑ
";
CM_ SG_ 1674 MET68A_31_0_METBZ_STS_CH0 "METブザーCH0吹鳴情報
";
CM_ SG_ 1674 MET68A_31_1_METBZ_STS_CH1 "METブザーCH1吹鳴情報
";
CM_ SG_ 1674 MET68A_31_2_METBZ_WARN_CH0 "METブザーCH0警告パターン情報
";
CM_ SG_ 1674 MET68A_31_3_METBZ_PTN_CH0 "METブザーCH0吹鳴パターン情報
";
CM_ SG_ 1674 MET68A_31_4_METBZ_WARN_CH1 "METブザーCH1警告パターン情報
";
CM_ SG_ 1674 MET68A_31_5_METBZ_PTN_CH1 "METブザーCH1吹鳴パターン情報
";
CM_ SG_ 1674 MET68A_31_6_VOL_ATN_REQ "音量ｱｯﾃﾈｰﾄ要求
";
CM_ SG_ 1674 MET68A_30_0_METBZ_KIND_CH1 "ﾌﾞｻﾞｰ種別(CH1)
";
CM_ SG_ 1674 MET68A_29_0_METBZ_KIND_CH0 "ﾌﾞｻﾞｰ種別(CH0)
";
CM_ SG_ 1674 MET68A_26_0_TRIPB_VAL "TRIP B(km or miles)
";
CM_ SG_ 1674 MET68A_23_0_TRIPA_VAL "TRIP A(km or miles)
";
CM_ SG_ 1674 MET68A_22_6_VOL_MUTE_REQ "音量ﾐｭｰﾄ要求
";
CM_ SG_ 1674 MET68A_21_0_IGNONDIST_VAL "区間距離
";
CM_ SG_ 1674 MET68A_20_1_IGNONTM_MIN_VAL "区間時間(分)
";
CM_ SG_ 1674 MET68A_19_0_AVSP_TRIPB_VAL "平均車速(Trip B)
";
CM_ SG_ 1674 MET68A_18_1_IGNONTM_HOUR_VAL "区間時間(時)
";
CM_ SG_ 1674 MET68A_17_0_AVSP_TRIPA_VAL "平均車速(Trip A)
";
CM_ SG_ 1674 MET68A_16_0_TRIP_DISP_TYPE "TRIPｴﾘｱ表示ｺﾝﾃﾝﾂ
";
CM_ SG_ 1674 MET68A_13_0_TRIP_VAL "TRIP(km or mile)
";
CM_ SG_ 1674 MET68A_12_0_TEMPBAR_PER "水温計表示割合
";
CM_ SG_ 1674 MET68A_11_0_FUELBAR_PER "FUEL計表示割合
";
CM_ SG_ 1674 MET68A_9_0_TACHOREV_VAL "ﾀｺ回転数
";
CM_ SG_ 1674 MET68A_7_0_SPD_COR_VAL "車速補正値（指示規格）
";
CM_ SG_ 1674 MET68A_6_1_CID_TONE_DOWN "CIDﾄｰﾝﾀﾞｳﾝ
";
CM_ SG_ 1674 MET68A_6_6_SI_FAIL_FLAG "SIﾌｪｰﾙﾌﾗｸﾞ
";
CM_ SG_ 1674 MET68A_5_0_DMSPD_SUB_VAL "現在車速ｻﾌﾞ(ﾃﾞｼﾞﾀﾙ車速)予備領域
";
CM_ SG_ 1674 MET68A_4_1_ILM_AIDM "昼夜情報
";
CM_ SG_ 1674 MET68A_4_2_TEMP_ICON "水温ｱｲｺﾝ状態
";
CM_ SG_ 1674 MET68A_4_5_SIDRIVE_MET_DISP "SI-DRIVE MET表示情報
";
CM_ SG_ 1674 MET68A_3_0_DMSPD_VAL "現在車速(ﾃﾞｼﾞﾀﾙ車速)
";
CM_ SG_ 1674 MET68A_2_0_E2E_COUNTER "E2Eｶｳﾝﾀ
";
CM_ SG_ 1674 MET68A_0_0_CRC "CRC
";
CM_ SG_ 1673 MET689_20_0_VOICE_GUIDE_SUP "音声ｶﾞｲﾀﾞﾝｽ有無
";
CM_ SG_ 1673 MET689_19_0_SPORT_CONT "ｽﾎﾟｰﾂｺﾝﾃﾝﾂ有無
";
CM_ SG_ 1673 MET689_18_0_STI_SUP "STI有無STI表示方式
";
CM_ SG_ 1673 MET689_17_0_REARVIEW "ｽﾏｰﾄﾘｱﾋﾞｭｰﾐﾗｰ有無
";
CM_ SG_ 1673 MET689_16_0_GSR_ELKS_SUP "GSR-ELKS機能有無
";
CM_ SG_ 1673 MET689_16_1_GSR_AEBS_SUP "GSR-AEBS機能有無
";
CM_ SG_ 1673 MET689_16_2_GSR_DDAW_SUP "GSR-DDAW機能有無
";
CM_ SG_ 1673 MET689_16_3_GSR_ISA_SUP "GSR-ISA機能有無
";
CM_ SG_ 1673 MET689_16_4_IACC_SUP "iACC機能有無
";
CM_ SG_ 1673 MET689_16_5_REAR_PANEL_SUP "ﾘｱﾋｰｺﾝﾊﾟﾈﾙ 有無
";
CM_ SG_ 1673 MET689_16_6_SEAT_HEATER_SUP "ｼｰﾄﾋｰﾀ 有無
";
CM_ SG_ 1673 MET689_16_7_SEAT_VENT_SUP "ｼｰﾄ空調 有無
";
CM_ SG_ 1673 MET689_15_0_CAMERA "ｶﾒﾗｼｽﾃﾑ情報
";
CM_ SG_ 1673 MET689_14_0_SXM_VARIANT "SXMバリアント
";
CM_ SG_ 1673 MET689_13_0_DAB "DABｱﾝﾃﾅ有無
";
CM_ SG_ 1673 MET689_13_1_SXM "SXMｱﾝﾃﾅ有無
";
CM_ SG_ 1673 MET689_13_2_EMBEDDED_NAVI "ｴﾝﾍﾞﾃﾞｯﾄﾅﾋﾞ有無
";
CM_ SG_ 1673 MET689_12_0_SPK_AMP "ｽﾋﾟｰｶｰ+AMP
";
CM_ SG_ 1673 MET689_11_0_DEST_VEHICLE "仕向地情報(車両別)
";
CM_ SG_ 1673 MET689_10_0_RDIFF_TEMP_SUP "REAR DIFF TEMP機能有無
";
CM_ SG_ 1673 MET689_10_1_SIDRIVE_SW_TYPE "SIﾄﾞﾗｲﾌﾞSW種別
";
CM_ SG_ 1673 MET689_10_3_XMODE_SW_TYPE "XﾓｰﾄﾞSW種別
";
CM_ SG_ 1673 MET689_9_0_GPF_SUP "GPF機能有無
";
CM_ SG_ 1673 MET689_9_1_SRH_SUP "SRH有無
";
CM_ SG_ 1673 MET689_9_2_AUTO_DOOR_MIRROR_SUP "ｵｰﾄ電動格納ﾄﾞｱﾐﾗｰ有無
";
CM_ SG_ 1673 MET689_9_3_REAR_REMIND_SUP "後席ﾘﾏｲﾝﾄﾞ機能有無
";
CM_ SG_ 1673 MET689_9_4_DRIVE_TYPE "FF/AWD判定結果
";
CM_ SG_ 1673 MET689_9_5_TPMSDISP_SUP "TPMS表示判定結果
";
CM_ SG_ 1673 MET689_9_6_GSI_SUP "GSI表示有無
";
CM_ SG_ 1673 MET689_9_7_SRVD_SUP "SRVD有無
";
CM_ SG_ 1673 MET689_8_0_XMODE_SUP "Xモード有無
";
CM_ SG_ 1673 MET689_7_0_SIDRIVE_SUP "SIﾄﾞﾗｲﾌﾞ有無
";
CM_ SG_ 1673 MET689_6_0_GRADE_INFO "ｸﾞﾚｰﾄﾞ情報
";
CM_ SG_ 1673 MET689_5_0_VEHICLE_TYPE "車型情報
";
CM_ SG_ 1673 MET689_4_0_DEST_GRP "仕向地(ｸﾞﾙｰﾌﾟ)
";
CM_ SG_ 1673 MET689_3_0_VEHICLE_MODEL "車両ﾓﾃﾞﾙ
";
CM_ SG_ 1673 MET689_2_0_E2E_COUNTER "E2Eｶｳﾝﾀ
";
CM_ SG_ 1673 MET689_0_0_CRC "CRC
";
CM_ SG_ 1658 TPM67A_6_1_TIRE_COLOR_RR "ﾀｲﾔRR表示　色
";
CM_ SG_ 1658 TPM67A_6_5_TIRE_COLOR_RL "ﾀｲﾔRL表示 色
";
CM_ SG_ 1658 TPM67A_6_7_TIRE_PRESSURE_RL "ﾀｲﾔRL 空気圧表示
";
CM_ SG_ 1658 TPM67A_5_0_TIRE_PRESSURE_RR "ﾀｲﾔRR 空気圧表示
";
CM_ SG_ 1658 TPM67A_3_1_TIRE_COLOR_FL "ﾀｲﾔFL表示 色
";
CM_ SG_ 1658 TPM67A_3_5_TIRE_COLOR_FR "ﾀｲﾔFR表示 色
";
CM_ SG_ 1658 TPM67A_3_7_TIRE_PRESSURE_FR "ﾀｲﾔFR 空気圧表示
";
CM_ SG_ 1658 TPM67A_2_0_TIRE_PRESSURE_FL "ﾀｲﾔFL 空気圧表示
";
CM_ SG_ 1658 TPM67A_1_0_MSG_COUNTER "ﾒｯｾｰｼﾞｶｳﾝﾀ
";
CM_ SG_ 1658 TPM67A_1_5_UNIT_IND_PRESSURE "空気圧表示単位
";
CM_ SG_ 1658 TPM67A_1_7_IND_PRESSURE "空気圧表示有無ﾌﾗｸﾞ
";
CM_ SG_ 1658 TPM67A_0_0_CHECK_SUM "ﾁｪｯｸｻﾑ
";
CM_ SG_ 1657 TPM679_3_0_STATE_TPMS "TPMS状態ﾌﾗｸﾞ
";
CM_ SG_ 1657 TPM679_3_2_DEFINED_STATE_TPMS "TPMS状態確定
";
CM_ SG_ 1657 TPM679_3_4_MODE_SELECT_TPMS "TPMSカスタマイズMode種別
";
CM_ SG_ 1657 TPM679_2_0_WARN_TPMS "TPMSｳｫｰﾆﾝｸﾞ
";
CM_ SG_ 1657 TPM679_2_3_INTERRUPT "割り込み表示
";
CM_ SG_ 1657 TPM679_2_5_CHECKLUMP_TPMS "TPMSチェックランプ点灯信号
";
CM_ SG_ 1657 TPM679_1_0_MSG_COUNTER "ﾒｯｾｰｼﾞｶｳﾝﾀ
";
CM_ SG_ 1657 TPM679_1_6 "予約:通信継続要求ﾌﾗｸﾞ(拡張)
";
CM_ SG_ 1657 TPM679_0_0_CHECK_SUM "ﾁｪｯｸｻﾑ
";
CM_ SG_ 826 ABG33A_7_0_VELOCITYCHANGE_VX_MAX "衝突時ΔVx MAX
";
CM_ SG_ 826 ABG33A_6_0_VELOCITYCHANGE_VX_MAX "衝突時ΔVx MAX
";
CM_ SG_ 826 ABG33A_5_0_P_SIDE_ABG_DEPLOY "P席ｻｲﾄﾞｴｱﾊﾞｯｸﾞ展開判定
";
CM_ SG_ 826 ABG33A_5_1_D_SIDE_ABG_DEPLOY "D席ｻｲﾄﾞｴｱﾊﾞｯｸﾞ展開判定
";
CM_ SG_ 826 ABG33A_5_2_FRONT_FAR_ABG_DEPLOY "前席ﾌｧｰｻｲﾄﾞｴｱﾊﾞｯｸﾞ展開判定
";
CM_ SG_ 826 ABG33A_5_3_REAR_FAR_ABG_DEPLOY "後席ﾌｧｰｻｲﾄﾞｴｱﾊﾞｯｸﾞ展開判定
";
CM_ SG_ 826 ABG33A_5_4_REAR_RH_ABG_DEPLOY "後席ｻｲﾄﾞｴｱﾊﾞｯｸﾞRH展開判定
";
CM_ SG_ 826 ABG33A_5_5_REAR_LH_ABG_DEPLOY "後席ｻｲﾄﾞｴｱﾊﾞｯｸﾞLH展開判定
";
CM_ SG_ 826 ABG33A_5_6_P_CURTAIN_ABG_DEPLOY "P席ｶｰﾃﾝｴｱﾊﾞｯｸﾞ展開判定
";
CM_ SG_ 826 ABG33A_5_7_D_CURTAIN_ABG_DEPLOY "D席ｶｰﾃﾝｴｱﾊﾞｯｸﾞ展開判定
";
CM_ SG_ 826 ABG33A_4_0_D_FRONT_ABG_DEPLOY "D席ﾌﾛﾝﾄｴｱﾊﾞｯｸﾞ展開判定
";
CM_ SG_ 826 ABG33A_4_1_P_FRONT_ABG_DEPLOY "P席ﾌﾛﾝﾄｴｱﾊﾞｯｸﾞ展開判定
";
CM_ SG_ 826 ABG33A_4_2_P_ABG_DEPLOY "P席ｼｰﾄｸｯｼｮﾝｴｱﾊﾞｯｸﾞ展開判定
";
CM_ SG_ 826 ABG33A_4_3_D_ABG_DEPLOY "D席ｼｰﾄｸｯｼｮﾝｴｱﾊﾞｯｸﾞ展開判定
";
CM_ SG_ 826 ABG33A_4_4_P_BELT_PRETENTION "P席ｼｰﾄﾍﾞﾙﾄﾌﾟﾘﾃﾝｼｮﾅ展開判定
";
CM_ SG_ 826 ABG33A_4_5_D_BELT_PRETENTION "D席ｼｰﾄﾍﾞﾙﾄﾌﾟﾘﾃﾝｼｮﾅ展開判定
";
CM_ SG_ 826 ABG33A_4_6_D_KNEE_ABG_DEPLOY "D席ﾆｰｴｱﾊﾞｯｸﾞ展開判定
";
CM_ SG_ 826 ABG33A_4_7_P_KNEE_ABG_DEPLOY "P席ﾆｰｴｱﾊﾞｯｸﾞ展開判定
";
CM_ SG_ 826 ABG33A_3_0_BELT_WRNING_PASS "P席ﾍﾞﾙﾄ状態(ｳｫｰﾆﾝｸﾞ出力用)
";
CM_ SG_ 826 ABG33A_3_2_BUCKLESW_DRVR "D席ﾊﾞｯｸﾙｽｲｯﾁ
";
CM_ SG_ 826 ABG33A_3_4_OCCUPATION_PASS "P席乗員有無信号
";
CM_ SG_ 826 ABG33A_3_6_IND_ACT_ABG_PASS "P席A/B作動ﾓｰﾄﾞｲﾝｼﾞｹｰﾀ
";
CM_ SG_ 826 ABG33A_2_0_IND_WARN_ABG "ｴｱﾊﾞｯｸﾞｳｫｰﾆﾝｸﾞﾗﾝﾌﾟ点灯・点滅要求
";
CM_ SG_ 826 ABG33A_2_2_DETECT_CRUSH "衝突検知信号
";
CM_ SG_ 826 ABG33A_2_5_STATUS_CRUSH_ECALL "衝突形態
";
CM_ SG_ 826 ABG33A_1_0_MSG_COUNTER "ﾒｯｾｰｼﾞｶｳﾝﾀ
";
CM_ SG_ 826 ABG33A_1_4_FLG_ABGIND_CTRL "P席 A/B ON/OFFｲﾝｼﾞｹｰﾀ点灯要求有無ﾌﾗｸﾞ
";
CM_ SG_ 826 ABG33A_1_5_REQ_COMM_CONT "通信継続要求
";
CM_ SG_ 826 ABG33A_1_6_COLLISION_COUNTER "衝突判定回数
";
CM_ SG_ 826 ABG33A_0_0_CHECK_SUM "ﾁｪｯｸｻﾑ
";
CM_ SG_ 961 DMS3C1_7_4_SHORT_DIST_DETECT "ショートディストラクション判定フラグ
";
CM_ SG_ 961 DMS3C1_7_5_PRESENCE_DETECT "後席乗員検知情報
";
CM_ SG_ 961 DMS3C1_7_6_RADER_EQUIP "ミリ波搭載情報
";
CM_ SG_ 961 DMS3C1_7_7_LOSING_POSTURE_DETECT "異常姿勢検知フラグ
";
CM_ SG_ 961 DMS3C1_6_0_ID_RECOG_CANCEL "ID認識中断フラグ
";
CM_ SG_ 961 DMS3C1_6_1_ID_ENABLE_FLAG "ID有効フラグ
";
CM_ SG_ 961 DMS3C1_6_2_PERMIT_AVN_FLAG "AVN操作許可フラグ
";
CM_ SG_ 961 DMS3C1_6_4_DISTRACTION_STATUS "脇見状態フラグ
";
CM_ SG_ 961 DMS3C1_6_5_DROWSINESS_STATUS "閉眼状態フラグ
";
CM_ SG_ 961 DMS3C1_6_6_DROWSINESS_LV2_STATUS "強い眠気状態フラグ
";
CM_ SG_ 961 DMS3C1_6_7_NOT_DETECTED_STATUS "顔未検出状態フラグ
";
CM_ SG_ 961 DMS3C1_5_0_ID_LIST "ID登録リスト
";
CM_ SG_ 961 DMS3C1_5_5_ID_EDIT_FLAG "ID設定フラグ
";
CM_ SG_ 961 DMS3C1_4_0_DMS_IND_REQ_FLAG "インジゲータ点灯フラグ
";
CM_ SG_ 961 DMS3C1_4_3_DMS_RECOG_STATUS "個人認識ON/OFF状態
";
CM_ SG_ 961 DMS3C1_4_4_DRIVER_STATUS "D席乗員状態
";
CM_ SG_ 961 DMS3C1_3_0_DRIVER_REGIST_ID "個人ID
";
CM_ SG_ 961 DMS3C1_3_4_CUST_EDIT_FLAG "カスタマイズ操作フラグ
";
CM_ SG_ 961 DMS3C1_3_6_ID_RECOG_FLAG "ID識別フラグ
";
CM_ SG_ 961 DMS3C1_2_0_LEVEL_DROWS "居眠り深度
";
CM_ SG_ 961 DMS3C1_2_3_DROWS_DETECT_FLAG "居眠り判定フラグ
";
CM_ SG_ 961 DMS3C1_2_7_DIST_DETECT_FLAG "脇見判定フラグ
";
CM_ SG_ 961 DMS3C1_1_0_MSG_COUNTER "メッセージカウンタ
";
CM_ SG_ 961 DMS3C1_1_4_WAKE_UP_FRAME "ｳｪｲｸｱｯﾌﾟﾌﾚｰﾑ識別ﾌﾗｸﾞ
";
CM_ SG_ 961 DMS3C1_1_5_REQ_COMM_CONT "通信継続要求ﾌﾗｸﾞ
";
CM_ SG_ 961 DMS3C1_1_7_EYE_DIST_FLAG "早鳴りフラグ
";
CM_ SG_ 961 DMS3C1_0_0_CHKSUM "ﾁｪｯｸｻﾑ
";
CM_ SG_ 1651 ACN673_7_2_REQ_STRG_H "ステアリングヒータ動作要求
";
CM_ SG_ 1651 ACN673_7_1_SEAT_H_L_AUTOIND "シートヒータ空調（左側） AUTOIND点灯
";
CM_ SG_ 1651 ACN673_7_0_SEAT_H_R_AUTOIND "シートヒータ空調（右側） AUTOIND点灯
";
CM_ SG_ 1651 ACN673_6_0_RR_FAN_SYMBOL "RR FAN SYMBOL
";
CM_ SG_ 1651 ACN673_6_2_SEAT_H_R "シートヒータ空調（右側）
";
CM_ SG_ 1651 ACN673_6_5_SEAT_H_L "シートヒータ空調（左側）
";
CM_ SG_ 1651 ACN673_5_0_DR_ONLY "一席集中状態
";
CM_ SG_ 1651 ACN673_5_2_STRG_H "ステアリングヒータ状態
";
CM_ SG_ 1651 ACN673_5_4_AC_SI_DS_SET "SI-DS空調設定
";
CM_ SG_ 1651 ACN673_5_6_STRG_H_AUTOIND "ステアリングヒータ AUTO IND点灯
";
CM_ SG_ 1651 ACN673_5_7_AC_SI_DS_FLG "SI-DS空調有無フラグ
";
CM_ SG_ 1651 ACN673_4_0_SEAT_HEATER_DR "Dr席　シートヒーター作動状態
";
CM_ SG_ 1651 ACN673_4_2_SEAT_HEATER_PA "Pa席　シートヒーター作動状態
";
CM_ SG_ 1651 ACN673_4_4_SEAT_HEATER "シートヒーター有無
";
CM_ SG_ 1651 ACN673_4_5_TEMP_SET_TYPE "設定温度タイプ
";
CM_ SG_ 1651 ACN673_4_7_VENTI_SEAT_EX_HI "シート空調EX-HI
";
CM_ SG_ 1651 ACN673_1_0_MSG_COUNTER "ﾒｯｾｰｼﾞｶｳﾝﾀ
";
CM_ SG_ 1651 ACN673_1_6_SYNC_RR "SYNC_RR
";
CM_ SG_ 1651 ACN673_1_7_RR_LOCK "RR_LOCK
";
CM_ SG_ 1651 ACN673_0_0_CHECK_SUM "ﾁｪｯｸｻﾑ
";
CM_ SG_ 1650 ACN672_7_0_INFO_AUTO3MODE "AUTO3モード
";
CM_ SG_ 1650 ACN672_7_2_INFO_REAR_TEMP "Rr設定温度
";
CM_ SG_ 1650 ACN672_6_0_DEF "DEF
";
CM_ SG_ 1650 ACN672_6_1_FAN_SYMBOL "FAN SYMBOL
";
CM_ SG_ 1650 ACN672_6_2_REAR_MODE "Rr吹き出し口ﾓｰﾄﾞ
";
CM_ SG_ 1650 ACN672_6_4_UNIT_TEMP "温度仕様
";
CM_ SG_ 1650 ACN672_6_5_SPEC_AC_UNIT "空調仕様
";
CM_ SG_ 1650 ACN672_6_7_REAR_AC "ﾘｱ空調有無
";
CM_ SG_ 1650 ACN672_5_0_AC_VR_MODE "ｴｱｺﾝ音声認識ﾓｰﾄﾞ
";
CM_ SG_ 1650 ACN672_5_2_INFO_TEMP_PASS "Pa設定温度
";
CM_ SG_ 1650 ACN672_4_0_AC_INTERRUPT_DISPLAY "ｴｱｺﾝ割り込み画面表示
";
CM_ SG_ 1650 ACN672_4_1_AC_VR_ACTION "ｴｱｺﾝ音声認識ｺﾏﾝﾄﾞ実行
";
CM_ SG_ 1650 ACN672_4_2_INFO_TEMP_DRVR "Dr設定温度
";
CM_ SG_ 1650 ACN672_3_0_MAX_AC "MAX A/C
";
CM_ SG_ 1650 ACN672_3_1_INFO_SYNC_OR_SING "SYNC
";
CM_ SG_ 1650 ACN672_3_2_INFO_FULL_OR_AUTO "FULL及びAUTO
";
CM_ SG_ 1650 ACN672_3_4_INFO_AC_ON "A/C
";
CM_ SG_ 1650 ACN672_3_5_INFO_RDEF "Rrﾃﾞﾌ
";
CM_ SG_ 1650 ACN672_3_6_INFO_CIRCULATION "内外気
";
CM_ SG_ 1650 ACN672_2_0_INFO_MODE_VENT "吹き出し口ﾓｰﾄﾞ
";
CM_ SG_ 1650 ACN672_2_4_INFO_FANONLY "送風モード
";
CM_ SG_ 1650 ACN672_2_5_INFO_LEV_BLOWERFAN "ﾌｧﾝ段数
";
CM_ SG_ 1650 ACN672_1_0_MSG_COUNTER "ﾒｯｾｰｼﾞｶｳﾝﾀ
";
CM_ SG_ 1650 ACN672_1_4_LVL_BLOWERFAN_RR "Rrﾌｧﾝ段数
";
CM_ SG_ 1650 ACN672_1_7_REAR_AUTO "Rr AUTO
";
CM_ SG_ 1650 ACN672_0_0_CHECK_SUM "ﾁｪｯｸｻﾑ
";
CM_ SG_ 722 ACN2D2_7_0_PD_PRESSURE "A/C PD圧力値
";
CM_ SG_ 722 ACN2D2_6_0_TRQ_COMP_ESTM "ｺﾝﾌﾟﾚｯｻﾄﾙｸ推定値
";
CM_ SG_ 722 ACN2D2_5_0_REQ_ENG_RPM "ｴｱｺﾝ要求ｴﾝｼﾞﾝ回転数
";
CM_ SG_ 722 ACN2D2_5_3_REQ_IDLE_COMP_RPM "ｱｲﾄﾞﾙ時要求ｺﾝﾌﾟﾚｯｻ回転数
";
CM_ SG_ 722 ACN2D2_4_0_LVL_PTC "PTC段数 電気負荷情報
";
CM_ SG_ 722 ACN2D2_4_2_MARGIN_OF_AC "ｴｱｺﾝ余裕度
";
CM_ SG_ 722 ACN2D2_4_5_LVL_BLOWER_FAN "ﾌﾞﾛｱﾌｧﾝSW（電気負荷情報）
";
CM_ SG_ 722 ACN2D2_3_0_PERMIT_ISS "ISS作動許可
";
CM_ SG_ 722 ACN2D2_3_2_TRQ_PAT_COMP_ESTM "A/C見込みﾄﾙｸﾊﾟﾀｰﾝ
";
CM_ SG_ 722 ACN2D2_3_5_IND_ROOM_TEMP "室温表示
";
CM_ SG_ 722 ACN2D2_2_0_FAIL_TRQ_COMP_ESTM "ｺﾝﾌﾟﾚｯｻﾄﾙｸ推定値ﾌｪｰﾙ
";
CM_ SG_ 722 ACN2D2_2_1_FAIL_AC "A/Cﾌｪｰﾙ
";
CM_ SG_ 722 ACN2D2_2_2_REQ_INHIBIT_LOCKUP "L/U禁止要求
";
CM_ SG_ 722 ACN2D2_2_3_AC_ON "A/C信号
";
CM_ SG_ 722 ACN2D2_2_4_RDEFOGSW "RﾃﾞﾌｫｯｶﾞSW
";
CM_ SG_ 722 ACN2D2_2_5_WARM_UP "ｳｫｰﾑｱｯﾌﾟ信号
";
CM_ SG_ 722 ACN2D2_2_6_AC_AUTO_MANUAL "ｵｰﾄｴｱｺﾝ・ﾏﾆｭｱﾙｴｱｺﾝ判別信号
";
CM_ SG_ 722 ACN2D2_2_7_COMP_TYPE "ｺﾝﾌﾟﾚｯｻﾀｲﾌﾟ
";
CM_ SG_ 722 ACN2D2_1_0_MSG_COUNTER "ﾒｯｾｰｼﾞｶｳﾝﾀ
";
CM_ SG_ 722 ACN2D2_1_4 "ｳｪｲｸｱｯﾌﾟﾌﾚｰﾑ識別ﾌﾗｸﾞ
";
CM_ SG_ 722 ACN2D2_1_5 "通信継続要求ﾌﾗｸﾞ
";
CM_ SG_ 722 ACN2D2_1_6 "予約:通信継続要求ﾌﾗｸﾞ(拡張)
";
CM_ SG_ 722 ACN2D2_1_7_WARM_POWER_CONT "暖房促進制御信号
";
CM_ SG_ 722 ACN2D2_0_0_CHECK_SUM "ﾁｪｯｸｻﾑ
";
CM_ SG_ 1667 ACN683_3_2_AC_DEFALTSET "空調デフォルト設定コマンドフラグ
";
CM_ SG_ 1667 ACN683_3_0_RCC_ACN_RES "テレマリモ空作動結果通知フラグ
";
CM_ SG_ 1667 ACN683_2_7_JUDGE_FANONLY "送風モード作動可否
";
CM_ SG_ 1667 ACN683_2_6_CSTM_LINK_SEAT_R "右側シートヒータ空調AUTO連動カスタマイズ
";
CM_ SG_ 1667 ACN683_2_5_CSTM_LINK_SEAT_L "左側 シートヒータ空調
AUTO連動カスタマイズ
";
CM_ SG_ 1667 ACN683_2_4_CSTM_STRG_H_LINK "ステアリングヒータ
AUTO連動カスタマイズ
";
CM_ SG_ 1667 ACN683_2_2_CSTM_TEMP_SVS_R "右側 シートベンチレーション温度 
カスタマイズ
";
CM_ SG_ 1667 ACN683_2_0_CSTM_TEMP_SVS_L "左側 シートベンチレーション温度 
カスタマイズ
";
CM_ SG_ 1667 ACN683_1_6_CSTM_TEMP_SEAT_H_R "右側 シートヒータ温度 
カスタマイズ
";
CM_ SG_ 1667 ACN683_1_4_CSTM_TEMP_SEAT_H_L "左側 シートヒータ温度
カスタマイズ
";
CM_ SG_ 1667 ACN683_1_0_MSG_COUNTER "メッセージカウンタ
";
CM_ SG_ 1667 ACN683_0_0_CHECK_SUM "チェックサム
";
CM_ SG_ 1731 AVN6C3_7_0_PRESENT_TIME_SEC "現在時刻情報(秒)
";
CM_ SG_ 1731 AVN6C3_6_0_PRESENT_TIME_MIN "現在時刻情報(分)
";
CM_ SG_ 1731 AVN6C3_5_0_PRESENT_TIME_HOUR "現在時刻情報(時)
";
CM_ SG_ 1731 AVN6C3_4_0_PRESENT_DAY "現在時刻情報(日)
";
CM_ SG_ 1731 AVN6C3_3_0_PRESENT_MONTH "現在時刻情報(月)
";
CM_ SG_ 1731 AVN6C3_2_0_PRESENT_YEAR "現在時刻情報(年)
";
CM_ SG_ 1731 AVN6C3_1_0_MSG_COUNTER "ﾒｯｾｰｼﾞｶｳﾝﾀ
";
CM_ SG_ 1731 AVN6C3_0_0_CHECK_SUM "ﾁｪｯｸｻﾑ
";
CM_ SG_ 1730 AVN6C2_7_0_LANGUAGE_SET "言語設定情報
";
CM_ SG_ 1730 AVN6C2_7_6_VALETMODE_ON_OFF "ValetMode状態
";
CM_ SG_ 1730 AVN6C2_1_0_MSG_COUNTER "ﾒｯｾｰｼﾞｶｳﾝﾀ
";
CM_ SG_ 1730 AVN6C2_0_0_CHECK_SUM "ﾁｪｯｸｻﾑ
";
CM_ SG_ 1005 AVN3ED_7_0_ACPANEL_PA_TEMP_DIAL "ｴｱｺﾝﾊﾟﾈﾙ P席TEMP ダイヤルSW情報
";
CM_ SG_ 1005 AVN3ED_7_3_ACPANEL_DR_TEMP_DIAL "ｴｱｺﾝﾊﾟﾈﾙ D席TEMP ダイヤルSW情報
";
CM_ SG_ 1005 AVN3ED_1_0_MSG_COUNTER "ﾒｯｾｰｼﾞｶｳﾝﾀ
";
CM_ SG_ 1005 AVN3ED_0_0_CHECK_SUM "ﾁｪｯｸｻﾑ
";
CM_ SG_ 1729 AVN6C1_7_0_MVS_VIEW_SELECT_SW "MVS映像切替画面内ｽｲｯﾁ情報
";
CM_ SG_ 1729 AVN6C1_7_4_MVS_AUTO_DISPLAY_SW "MVSカメラ自動表示スイッチ情報
";
CM_ SG_ 1729 AVN6C1_7_6_MVS_HITCH_GUIDE_REQ "ヒッチボールガイド線ON/OFF変更要求
";
CM_ SG_ 1729 AVN6C1_1_0_MSG_COUNTER "ﾒｯｾｰｼﾞｶｳﾝﾀ
";
CM_ SG_ 1729 AVN6C1_0_0_CHECK_SUM "ﾁｪｯｸｻﾑ
";
CM_ SG_ 1725 AVN6BD_7_1_EYE_SAFETY_MODE_CSTM "障害物なし加速抑制カスタマイズ
";
CM_ SG_ 1725 AVN6BD_7_2_EYE_BRAKE_HAPTIC_CSTM "ブレーキハプティックカスタマイズ
";
CM_ SG_ 1725 AVN6BD_7_4_LDW_SW_PUSH_STATE "LDW音OFFハードSW押下状態
";
CM_ SG_ 1725 AVN6BD_7_5_LDW_SW_FAIL_STATE "LDW音OFFハードSW異常状態
";
CM_ SG_ 1725 AVN6BD_7_6_FCW_SW_PUSH_STATE "FCW音OFFハードSW押下状態
";
CM_ SG_ 1725 AVN6BD_7_7_FCW_SW_FAIL_STATE "FCW音OFFハードSW異常状態
";
CM_ SG_ 1725 AVN6BD_6_0_REQ_CHG_CSTM_EYE "アイサイトカスタマイズ要求変更
";
CM_ SG_ 1725 AVN6BD_6_1_REQ_RESET_CSTM_EYE "アイサイトカスタマイズリセット要求
";
CM_ SG_ 1725 AVN6BD_6_3_CSTM_LANE_CONT "アイサイトカスタマイズ変更設定(通行車線)
";
CM_ SG_ 1725 AVN6BD_6_4_CSTM_MIS_AT_BACK "アイサイトカスタマイズ変更設定(AT誤後進抑制制御)
";
CM_ SG_ 1725 AVN6BD_6_6_CSTM_ACC_CONT "アイサイトカスタマイズ変更設定(ACC加速特性)
";
CM_ SG_ 1725 AVN6BD_1_0_MSG_COUNTER "ﾒｯｾｰｼﾞｶｳﾝﾀ
";
CM_ SG_ 1725 AVN6BD_0_0_CHECK_SUM "ﾁｪｯｸｻﾑ
";
CM_ SG_ 1724 AVN6BC_6_0_LAT_MINUTE "緯度_分
";
CM_ SG_ 1724 AVN6BC_6_6_LAT_SECOND "緯度_秒
";
CM_ SG_ 1724 AVN6BC_5_0_LAT_N_S "緯度_南北
";
CM_ SG_ 1724 AVN6BC_5_1_LAT_DEGREE "緯度_度
";
CM_ SG_ 1724 AVN6BC_3_0_LON_MINUTE "経度_分
";
CM_ SG_ 1724 AVN6BC_3_6_LON_SECOND "経度_秒
";
CM_ SG_ 1724 AVN6BC_2_0_LON_DEGREE "経度_度
";
CM_ SG_ 1724 AVN6BC_1_0_MSG_COUNTER "ﾒｯｾｰｼﾞｶｳﾝﾀ
";
CM_ SG_ 1724 AVN6BC_1_4_GNSS_STATUS "GNSS測位状態
";
CM_ SG_ 1724 AVN6BC_1_7_LON_E_W "経度_東西
";
CM_ SG_ 1724 AVN6BC_0_0_CHECK_SUM "ﾁｪｯｸｻﾑ
";
CM_ SG_ 1723 AVN6BB_7_0_ISA_IACC_OFFSET_CSTM "ISA制限車速・iACCセット車速オフセット値
";
CM_ SG_ 1723 AVN6BB_7_5_EYE_TOLLBOOTH_DECEL "料金所減速ｶｽﾀﾏｲｽﾞ(高度運転支援)
";
CM_ SG_ 1723 AVN6BB_7_6_EYE_CURVE_DECEL_CSTM "カーブ減速ｶｽﾀﾏｲｽﾞ（高度運転支援）
";
CM_ SG_ 1723 AVN6BB_7_7_EYE_GREEN_LIGHT_CSTM "青信号切り替わりお知らせ設定
";
CM_ SG_ 1723 AVN6BB_6_0_CCU_FAIL "CCU/CIDﾌｪｰﾙﾌﾗｸﾞ
";
CM_ SG_ 1723 AVN6BB_6_1_EYE_P_CR_CSTM "P-CR ON/OFF設定
";
CM_ SG_ 1723 AVN6BB_6_2_EYE_ALK_B_LDW_CSTM "車線逸脱防止+車線逸脱警報 ON/OFF設定
";
CM_ SG_ 1723 AVN6BB_6_4_EYE_CSTM_REQ "EyeSightｶｽﾀﾏｲｽﾞ変更要求
";
CM_ SG_ 1723 AVN6BB_6_5_EYE_ELK_CSTM "ELK ON/OFF設定
";
CM_ SG_ 1723 AVN6BB_6_6_EYE_ALKB_EDGE_CSTM "ﾛｰﾄﾞｴｯｼﾞALKBｶｽﾀﾏｲｽﾞ（ALKの制御種別）
";
CM_ SG_ 1723 AVN6BB_6_7_FCW_ON_OFF "FCW機能 ON/OFF設定
";
CM_ SG_ 1723 AVN6BB_5_0_DMS_SELECT_ID "DMS選択ID
";
CM_ SG_ 1723 AVN6BB_5_4_TPMS_TH_MODE_CSTM "TPMS閾値ﾓｰﾄﾞｶｽﾀﾏｲｽﾞ
";
CM_ SG_ 1723 AVN6BB_5_6_DMS_SET_REQ "DMS設定変更要求ﾌﾗｸﾞ
";
CM_ SG_ 1723 AVN6BB_5_7_DMS_RECOG_SET "DMS個人認識ON/OFF設定
";
CM_ SG_ 1723 AVN6BB_4_0_DMS_EDIT_REQ "DMS操作中ﾌﾗｸﾞ
";
CM_ SG_ 1723 AVN6BB_4_4_VEHICLE_DEMO "車両連携デモモード（DMSなど）
";
CM_ SG_ 1723 AVN6BB_4_5_SRVD_CSTM_REQ "SRVDｶｽﾀﾏｲｽﾞ変更要求
";
CM_ SG_ 1723 AVN6BB_4_6_SEAT_RESET_REQ "ｼｰﾄｶｽﾀﾏｲｽﾞﾘｾｯﾄ要求
";
CM_ SG_ 1723 AVN6BB_4_7_SEATAWAY_SET_CSTM "ｼｰﾄ後退設定変更要求
";
CM_ SG_ 1723 AVN6BB_3_0_SRVD_ON_OFF "SRVD ON/OFF SW情報
";
CM_ SG_ 1723 AVN6BB_3_1_PRG_RESET_REQ "PRGｶｽﾀﾏｲｽﾞﾘｾｯﾄ要求
";
CM_ SG_ 1723 AVN6BB_3_2_PRG_MEM_CSTM "PRGﾒﾓﾘ設定変更要求
";
CM_ SG_ 1723 AVN6BB_3_3_DMS_ON_OFF "DMS ON/OFF SW情報
";
CM_ SG_ 1723 AVN6BB_3_4_MIR_RESET_REQ "ﾄﾞｱﾐﾗｰｶｽﾀﾏｲｽﾞﾘｾｯﾄ要求
";
CM_ SG_ 1723 AVN6BB_3_5_MIR_AFOLD_CSTM "ｵｰﾄ電動格納ﾄﾞｱﾐﾗｰ設定変更要求
";
CM_ SG_ 1723 AVN6BB_3_6_MIR_RTILT_CSTM "ﾘﾊﾞｰｽ連動ﾄﾞｱﾐﾗｰ設定変更要求
";
CM_ SG_ 1723 AVN6BB_3_7_EYE_TSA_CSTM "標識認識連動TSA（ISA/iACC） ON/OFF設定
";
CM_ SG_ 1723 AVN6BB_2_0_AVH_ON_OFF "AVH ON/OFF SW情報
";
CM_ SG_ 1723 AVN6BB_2_2_VDC_ON_OFF "VDC ON/OFF 情報
";
CM_ SG_ 1723 AVN6BB_2_4_CCU_HALT_RESET "CCUリセット・一時停止フラグ
";
CM_ SG_ 1723 AVN6BB_2_5_EYE_LDW_TIMING_CSTM "LDWタイミングユーザ設定値
";
CM_ SG_ 1723 AVN6BB_2_6_FCW_CSTM "FCWカスタマイズ設定
";
CM_ SG_ 1723 AVN6BB_1_0_MSG_COUNTER "ﾒｯｾｰｼﾞｶｳﾝﾀ
";
CM_ SG_ 1723 AVN6BB_1_4_EYE_WARN_CSTM "ｽﾃｱ振動ｶｽﾀﾏｲｽﾞ
";
CM_ SG_ 1723 AVN6BB_1_5_EYE_FCTI_CSTM "FCTI(交差車両接近通知)
";
CM_ SG_ 1723 AVN6BB_1_7_LDW_WARNING_ON_OFF "LDW音 ON/OFF設定
";
CM_ SG_ 1723 AVN6BB_0_0_CHECK_SUM "ﾁｪｯｸｻﾑ
";
CM_ SG_ 1722 AVN6BA_7_0_GUIDE_LINE_REAR "Rカメラガイド線表示設定(ON/OFF)
";
CM_ SG_ 1722 AVN6BA_7_1_GUIDE_LINE_SIDE "Sカメラガイド線表示設定(ON/OFF)
";
CM_ SG_ 1722 AVN6BA_7_2_GUIDE_LINE_FRONT "Fカメラガイド線表示設定(ON/OFF)
";
CM_ SG_ 1722 AVN6BA_7_3_STEER_ANGLE_INTERLOCK "Rカメラガイド線舵角連動設定(連動/固定)
";
CM_ SG_ 1722 AVN6BA_7_4_BACK_CAMERA_DELAY "Rカメラ9秒Delay表示設定(ON/OFF)
";
CM_ SG_ 1722 AVN6BA_7_5_REQ_STOP_CAMERA_OUT "カメラ映像出力停止要求フラグ
";
CM_ SG_ 1722 AVN6BA_7_6_VIEW_CHANGE_SW "カメラ切替SW信号
";
CM_ SG_ 1722 AVN6BA_6_0_CLIMAITE_PA_TEMP "音声認識ｴｱｺﾝ Pa_TEMP
";
CM_ SG_ 1722 AVN6BA_6_6_CLIMATE_SYNC "ｴｱｺﾝﾊﾟﾈﾙ SYNC SW
";
CM_ SG_ 1722 AVN6BA_6_7_CLIMATE_F_DEF "Front DEF SW
";
CM_ SG_ 1722 AVN6BA_5_0_CLIMAITE_DR_TEMP "音声認識ｴｱｺﾝ Dr_TEMP
";
CM_ SG_ 1722 AVN6BA_5_6_CLIMAITE_AUTO "音声認識ｴｱｺﾝ AUTO SW
";
CM_ SG_ 1722 AVN6BA_5_7_CLIMAITE_MAX_AC "音声認識ｴｱｺﾝ MAX A/C SW
";
CM_ SG_ 1722 AVN6BA_4_0_CLIMAITE_VR "音声認識ｴｱｺﾝ操作ﾌﾗｸﾞ
";
CM_ SG_ 1722 AVN6BA_4_3_CLIMATE_AC "ｴｱｺﾝﾊﾟﾈﾙ A/C SW
";
CM_ SG_ 1722 AVN6BA_4_4_CLIMAITE_FAN "音声認識ｴｱｺﾝ FAN
";
CM_ SG_ 1722 AVN6BA_3_0_PERSONAL_IC_SH "ﾊﾟｰｿﾅﾗｲｽﾞ：H/Unit（ｽﾏｰﾄﾌｫﾝ無し時）による個人識別ｺｰﾄﾞ
";
CM_ SG_ 1722 AVN6BA_3_4_CSTM_SONNER "ｿﾅｰｶｽﾀﾏｲｽﾞ変更設定(ｿﾅｰ ON/OFF)
";
CM_ SG_ 1722 AVN6BA_3_5_CSTM_RAB "ｿﾅｰｶｽﾀﾏｲｽﾞ変更設定(RAB　ON/OFF)
";
CM_ SG_ 1722 AVN6BA_3_6_REQ_CHG_CSTM_RAB "RABｿﾅｰｶｽﾀﾏｲｽﾞ要求変更
";
CM_ SG_ 1722 AVN6BA_3_7_CLIMATE_R_DEF "Rear DEF SW
";
CM_ SG_ 1722 AVN6BA_2_0_CLIMATE_PTC "ｴｱｺﾝﾊﾟﾈﾙ PTC 強制ON SW
";
CM_ SG_ 1722 AVN6BA_2_1_CLIMATE_MODE "ｴｱｺﾝﾊﾟﾈﾙ MODE SW
";
CM_ SG_ 1722 AVN6BA_2_2_CLIMATE_SEAT_C_L "ｴｱｺﾝﾊﾟﾈﾙ ﾍﾞﾝﾁﾚｰｼｮﾝｼｰﾄ左 SW
";
CM_ SG_ 1722 AVN6BA_2_3_CLIMATE_SEAT_C_R "ｴｱｺﾝﾊﾟﾈﾙ ﾍﾞﾝﾁﾚｰｼｮﾝｼｰﾄ右 SW
";
CM_ SG_ 1722 AVN6BA_2_4_CLIMATE_SEAT_H_L "ｴｱｺﾝﾊﾟﾈﾙ SEAT HEATER左 SW
";
CM_ SG_ 1722 AVN6BA_2_5_CLIMATE_SEAT_H_R "ｴｱｺﾝﾊﾟﾈﾙ SEAT HEATER右 SW
";
CM_ SG_ 1722 AVN6BA_2_6_CLIMATE_INNER_AIR "ｴｱｺﾝﾊﾟﾈﾙ 内外気 SW
";
CM_ SG_ 1722 AVN6BA_2_7_CLIMATE_ON_OFF "ｴｱｺﾝﾊﾟﾈﾙ 空調ON/OFF SW
";
CM_ SG_ 1722 AVN6BA_1_0_MSG_COUNTER "ﾒｯｾｰｼﾞｶｳﾝﾀ
";
CM_ SG_ 1722 AVN6BA_1_4_CLIMAITE_STATUS "音声認識状態表示
";
CM_ SG_ 1722 AVN6BA_1_7_CLIMAITE_ON_OFF "音声認識 ON/OFF
";
CM_ SG_ 1722 AVN6BA_0_0_CHECK_SUM "ﾁｪｯｸｻﾑ
";
CM_ SG_ 1713 AVN6B1_7_1_PRESENT_YEAR "現在年月日(年)
";
CM_ SG_ 1713 AVN6B1_6_0_PRESENT_DAY "現在年月日（日）
";
CM_ SG_ 1713 AVN6B1_6_5_PRESENT_MONTH "現在年月日(月)
";
CM_ SG_ 1713 AVN6B1_5_0_FAIL_AVN "AVNﾌｪｰﾙ情報
";
CM_ SG_ 1713 AVN6B1_5_1_IN_OPERATION "操作中ﾌﾗｸﾞ
";
CM_ SG_ 1713 AVN6B1_5_2_TYPE_NAVI "ﾅﾋﾞ有無ﾌﾗｸﾞ
";
CM_ SG_ 1713 AVN6B1_5_4_XM_ENABLE "XM有無ﾌﾗｸﾞ
";
CM_ SG_ 1713 AVN6B1_5_6_FLG_ABLE_WELCOME_SCL "ｳｪﾙｶﾑ画面表示可能ﾌﾗｸﾞ
";
CM_ SG_ 1713 AVN6B1_5_7_STEER_ANGLE_INTERLOCK "Rカメラガイド線舵角連動設定(ON/OFF)（H/Unit）
";
CM_ SG_ 1713 AVN6B1_4_0_PRESENT_TIME_SEC "現在時刻(秒)
";
CM_ SG_ 1713 AVN6B1_4_7_BACK_CAMERA_DELAY "Rカメラ9秒Delay表示設定(ON/OFF)（H/Unit）
";
CM_ SG_ 1713 AVN6B1_3_0_PRESENT_TIME_MIN "現在時刻(分)
";
CM_ SG_ 1713 AVN6B1_3_7_MVS_FTSNR_INTERRUPT "ｸﾘｿﾅ自動前方視界支援設定
";
CM_ SG_ 1713 AVN6B1_2_0_GPS_CLOCK_FLG "時刻補正有効ﾌﾗｸﾞ
";
CM_ SG_ 1713 AVN6B1_2_1_PRESENT_TIME_HOUR "現在時刻(時)
";
CM_ SG_ 1713 AVN6B1_2_6_TIME_FORMAT "タイムフォーマット切替(12h/24h)
";
CM_ SG_ 1713 AVN6B1_1_0_MSG_COUNTER "ﾒｯｾｰｼﾞｶｳﾝﾀ
";
CM_ SG_ 1713 AVN6B1_1_4_WAKE_UP_FRAME "ｳｪｲｸｱｯﾌﾟﾌﾚｰﾑ識別ﾌﾗｸﾞ
";
CM_ SG_ 1713 AVN6B1_1_5_REQ_COMM_CONT "通信継続要求ﾌﾗｸﾞ
";
CM_ SG_ 1713 AVN6B1_1_6_ACTIVE_AVN_CSTM "車両ｶｽﾀﾏｲｽﾞ実施状態ﾌﾗｸﾞ（H/Unit）
";
CM_ SG_ 1713 AVN6B1_1_7_REQ_STOP_CAMERA_OUT "カメラ映像出力停止要求フラグ（H/Unit）
";
CM_ SG_ 1713 AVN6B1_0_0_CHECK_SUM "ﾁｪｯｸｻﾑ
";
CM_ SG_ 1019 AVN3FB_7_0_SMT_TIM_RESET_REQ "自動ｴﾝｼﾞﾝ停止ﾀｲﾏﾘｾｯﾄ要求
";
CM_ SG_ 1019 AVN3FB_7_1_SMT_EG_CSTM_REQ "自動ｴﾝｼﾞﾝ停止カスタマイズ変更要求
";
CM_ SG_ 1019 AVN3FB_7_2_EYE_YEILD_CSTM "特殊標識表示ON/OFF設定（前方優先道路）
";
CM_ SG_ 1019 AVN3FB_7_3_EYE_STOP_CSTM "特殊標識表示ON/OFF設定（一時停止）
";
CM_ SG_ 1019 AVN3FB_7_4_EYE_NO_ENTRY_CSTM "特殊標識表示ON/OFF設定（進入禁止）
";
CM_ SG_ 1019 AVN3FB_7_5_MVS_CAMERA_SELECT_SW "MVSｶﾒﾗ切替画面内ｽｲｯﾁ情報
";
CM_ SG_ 1019 AVN3FB_7_7_ACPANEL_DR_ONLY "ｴｱｺﾝﾊﾟﾈﾙ 一席集中 SW
";
CM_ SG_ 1019 AVN3FB_6_0_ACPANEL_PA_TEMP "ｴｱｺﾝﾊﾟﾈﾙ Ｐ席TEMP
";
CM_ SG_ 1019 AVN3FB_6_6_ACPANEL_MODE_DOWN "ｴｱｺﾝﾊﾟﾈﾙ 吹き出し口MODE- SW
";
CM_ SG_ 1019 AVN3FB_6_7_ACPANEL_MODE_UP "ｴｱｺﾝﾊﾟﾈﾙ 吹き出し口MODE+ SW
";
CM_ SG_ 1019 AVN3FB_5_0_ACPANEL_DR_TEMP "ｴｱｺﾝﾊﾟﾈﾙ D席TEMP
";
CM_ SG_ 1019 AVN3FB_5_6_ACPANEL_FAN_DOWN "ｴｱｺﾝﾊﾟﾈﾙ FAN DOWN SW
";
CM_ SG_ 1019 AVN3FB_5_7_ACPANEL_FAN_UP "ｴｱｺﾝﾊﾟﾈﾙ FAN UP SW
";
CM_ SG_ 1019 AVN3FB_4_0_ACPANEL_FAN_LEVEL "ｴｱｺﾝﾊﾟﾈﾙ FAN段数
";
CM_ SG_ 1019 AVN3FB_4_4_ACPANEL_MODE_VENT "ｴｱｺﾝﾊﾟﾈﾙ 吹き出し口MODE指定
";
CM_ SG_ 1019 AVN3FB_3_0_ACPANEL_PA_TEMP_DOWN "ｴｱｺﾝﾊﾟﾈﾙ P席TEMP設定DOWN SW
";
CM_ SG_ 1019 AVN3FB_3_1_ACPANEL_PA_TEMP_UP "ｴｱｺﾝﾊﾟﾈﾙ P席TEMP設定UP SW
";
CM_ SG_ 1019 AVN3FB_3_2_ACPANEL_DR_TEMP_DOWN "ｴｱｺﾝﾊﾟﾈﾙ D席TEMP設定DOWN SW
";
CM_ SG_ 1019 AVN3FB_3_3_ACPANEL_DR_TEMP_UP "ｴｱｺﾝﾊﾟﾈﾙ D席TEMP設定UP SW
";
CM_ SG_ 1019 AVN3FB_3_4_ACPANEL_SYNC "ｴｱｺﾝﾊﾟﾈﾙ SYNC SW
";
CM_ SG_ 1019 AVN3FB_3_5_ACPANEL_AC "ｴｱｺﾝﾊﾟﾈﾙ A/C SW
";
CM_ SG_ 1019 AVN3FB_3_6_F_DEF_SW "Front DEF SW
";
CM_ SG_ 1019 AVN3FB_3_7_R_DEF_SW "Rear DEF SW
";
CM_ SG_ 1019 AVN3FB_2_0_ACPANEL_AUTO "ｴｱｺﾝﾊﾟﾈﾙ AUTO SW
";
CM_ SG_ 1019 AVN3FB_2_1_ACPANEL_MAX_AC "ｴｱｺﾝﾊﾟﾈﾙ MAX A/C SW
";
CM_ SG_ 1019 AVN3FB_2_2_ACPANEL_SEAT_C_P "ｴｱｺﾝﾊﾟﾈﾙ ﾍﾞﾝﾁﾚｰｼｮﾝｼｰﾄ P席 SW
";
CM_ SG_ 1019 AVN3FB_2_3_ACPANEL_SEAT_C_D "ｴｱｺﾝﾊﾟﾈﾙ ﾍﾞﾝﾁﾚｰｼｮﾝｼｰﾄ D席 SW
";
CM_ SG_ 1019 AVN3FB_2_4_ACPANEL_SEAT_H_P "ｴｱｺﾝﾊﾟﾈﾙ SEAT HEATER P席 SW
";
CM_ SG_ 1019 AVN3FB_2_5_ACPANEL_SEAT_H_D "ｴｱｺﾝﾊﾟﾈﾙ SEAT HEATER D席 SW
";
CM_ SG_ 1019 AVN3FB_2_6_ACPANEL_INNER_AIR "ｴｱｺﾝﾊﾟﾈﾙ 内外気 SW
";
CM_ SG_ 1019 AVN3FB_2_7_ACPANEL_AC_ON_OFF "ｴｱｺﾝﾊﾟﾈﾙ 空調ON/OFF
";
CM_ SG_ 1019 AVN3FB_1_0_MSG_COUNTER "ﾒｯｾｰｼﾞｶｳﾝﾀ
";
CM_ SG_ 1019 AVN3FB_1_4_EYE_CSTM_REQ_3FB "EyeSightｶｽﾀﾏｲｽﾞ変更要求_3FB
";
CM_ SG_ 1019 AVN3FB_1_5_DDAW_WARNING_CSTM "DDAW ON/OFF設定
";
CM_ SG_ 1019 AVN3FB_1_6_SIGN_SWITCH_SND "標識切り替わり音 ON/OFF設定
";
CM_ SG_ 1019 AVN3FB_1_7_SLWF_CSTM "SLWF ON/OFF設定
";
CM_ SG_ 1019 AVN3FB_0_0_CHECK_SUM "ﾁｪｯｸｻﾑ
";
CM_ SG_ 1299 AVN513_1_4_ActiveWakeUpBit "Active Wakeup ﾌﾗｸﾞ
";
CM_ SG_ 1299 AVN513_0_0_SourceNodeID "送信元ID
";
CM_ SG_ 1696 AIL6A0_7_0_AIL_RENDER_STA "AIL 演出
";
CM_ SG_ 1696 AIL6A0_7_3_AIL_RENDER_PAT_A_DIS "AIL演出_パターンA表示有無
";
CM_ SG_ 1696 AIL6A0_7_4_AIL_RENDER_PAT_B_DIS "AIL演出_パターンB表示有無
";
CM_ SG_ 1696 AIL6A0_7_5_AIL_RENDER_PAT_C_DIS "AIL演出_パターンC表示有無
";
CM_ SG_ 1696 AIL6A0_7_6_AIL_RENDER_PAT_D_DIS "AIL 演出_パターンD表示有無
";
CM_ SG_ 1696 AIL6A0_7_7_AIL_RENDER_DR_MD_DIS "AIL 演出_走行モード連動表示有無
";
CM_ SG_ 1696 AIL6A0_6_0_AIL_FIRST_BRIGHT_STA "AIL 第1照明_輝度状態
";
CM_ SG_ 1696 AIL6A0_6_4_AIL_SECOND_BRIGHT_STA "AIL 第2照明_輝度状態
";
CM_ SG_ 1696 AIL6A0_5_0_AIL_SECOND_COLOR_STA "AIL第2照明_カラー状態
";
CM_ SG_ 1696 AIL6A0_5_6_AIL_CSTM_PRS_DIS_REQ "AIL CUSTOMプリセット表示要求
";
CM_ SG_ 1696 AIL6A0_5_7_AIL_RENDER_CSTM_DIS "AIL 演出_CUSTOM・CUSTOMプリセット表示有無
";
CM_ SG_ 1696 AIL6A0_4_0_AIL_FIRST_COLOR_STA "AIL 第1照明_カラー状態
";
CM_ SG_ 1696 AIL6A0_4_6_AIL_SECOND_COLOR_DIS "AIL 第2照明_カラー表示有無
";
CM_ SG_ 1696 AIL6A0_4_7_AIL_SECOND_BRIGHT_DIS "AIL第2照明_輝度表示有無
";
CM_ SG_ 1696 AIL6A0_3_0_AIL_ADAS_VEH_DIS_STA "AIL ADAS_車間距離連動変更要求
";
CM_ SG_ 1696 AIL6A0_3_1_AIL_ADAS_VEH_DIS__DIS "AIL ADAS_車間距離連動表示有無
";
CM_ SG_ 1696 AIL6A0_3_2_AIL_ADAS_LANE_DEV_STA "AIL ADAS_車線逸脱連動状態
";
CM_ SG_ 1696 AIL6A0_3_3_AIL_ADAS_LANE_DEV_DIS "AIL ADAS_車線逸脱連動表示有無
";
CM_ SG_ 1696 AIL6A0_3_4_AIL_ADAS_FT_CROSS_STA "AIL ADAS_前側方飛び出し連動状態
";
CM_ SG_ 1696 AIL6A0_3_5_AIL_ADAS_FT_CROSS_DIS "AIL ADAS_前側方飛び出し連動表示有無
";
CM_ SG_ 1696 AIL6A0_3_6_AIL_ADAS_HANDS_FR_STA "AIL ADAS_ハンズフリー切り替え連動状態
";
CM_ SG_ 1696 AIL6A0_3_7_AIL_ADAS_HANDS_FR_DIS "AIL ADAS_ハンズフリー切り替え連動表示有無
";
CM_ SG_ 1696 AIL6A0_2_0_AIL_ADAS_EXP_STA "AIL ADAS連動状態
";
CM_ SG_ 1696 AIL6A0_2_1_AIL_ADAS_EXP_DIS "AIL ADAS連動表示有無
";
CM_ SG_ 1696 AIL6A0_2_2_AIL_NOTIFI_EXP_STA "AIL おしらせ連動状態
";
CM_ SG_ 1696 AIL6A0_2_3_AIL_NOTIFI_EXP_DIS "AIL おしらせ連動表示有無
";
CM_ SG_ 1696 AIL6A0_2_4_AIL_AIR_CON_EXP_STA "AIL 空調連動状態
";
CM_ SG_ 1696 AIL6A0_2_5_AIL_AIR_CON_EXP_DIS "AIL 空調連動表示有無
";
CM_ SG_ 1696 AIL6A0_1_0_MSG_COUNTER "メッセージカウンタ
";
CM_ SG_ 1696 AIL6A0_1_4_AIL_ON_OFF_STA "AIL ON/OFF状態
";
CM_ SG_ 1696 AIL6A0_1_6_AIL_WEL_FOL_STA "AIL ｳｴﾙｶﾑﾌｫﾛｰﾐｰ連動状態
";
CM_ SG_ 1696 AIL6A0_1_7_AIL_WEL_FOL_DIS "AIL ｳｴﾙｶﾑﾌｫﾛｰﾐｰ連動表示有無
";
CM_ SG_ 1696 AIL6A0_0_0_CHECK_SUM "チェックサム
";
CM_ SG_ 1635 AHL663_3_0_FAIL_ADB "ADB故障警告灯
";
CM_ SG_ 1635 AHL663_3_2_HEADLAMP_HI_IND "ﾍｯﾄﾞﾗﾝﾌﾟ Hiﾋﾞｰﾑｲﾝｼﾞｹｰﾀ
";
CM_ SG_ 1635 AHL663_3_3_ADB_ACTIVE_IND "ADB作動ｲﾝｼﾞｹｰﾀ
";
CM_ SG_ 1635 AHL663_3_4_CSTM_SRH_OFF "SRH OFF 機能ｶｽﾀﾏｲｽﾞ設定
";
CM_ SG_ 1635 AHL663_2_0_FAIL_AHL "ｵｰﾄﾍｯﾄﾞﾗﾝﾌﾟﾚﾍﾞﾗ異常
";
CM_ SG_ 1635 AHL663_2_3_FAIL_LED_HEADLAMP "LEDﾍｯﾄﾞﾗﾝﾌﾟ異常
";
CM_ SG_ 1635 AHL663_2_5_IND_AFS "AFSｲﾝｼﾞｹｰﾀ信号
";
CM_ SG_ 1635 AHL663_1_0_MSG_COUNTER "ﾒｯｾｰｼﾞｶｳﾝﾀ
";
CM_ SG_ 1635 AHL663_1_6 "予約:通信継続要求ﾌﾗｸﾞ(拡張)
";
CM_ SG_ 1635 AHL663_0_0_CHECK_SUM "ﾁｪｯｸｻﾑ
";
CM_ SG_ 985 AHL3D9_3_0_ROLL_ANGLE "ロール角
";
CM_ SG_ 985 AHL3D9_2_0_PITCH_ANGLE "ピッチ角
";
CM_ SG_ 985 AHL3D9_1_0_MSG_COUNTER "ﾒｯｾｰｼﾞｶｳﾝﾀ
";
CM_ SG_ 985 AHL3D9_1_4_AHL_STATE "AHL状態
";
CM_ SG_ 985 AHL3D9_0_0_CHECK_SUM "チェックサム
";
CM_ SG_ 1631 IMB65F_2_0_DATA2 "照合データ2
";
CM_ SG_ 1631 IMB65F_1_0_MSG_COUNTER "ﾒｯｾｰｼﾞｶｳﾝﾀ
";
CM_ SG_ 1631 IMB65F_1_4_DATA1 "照合データ1
";
CM_ SG_ 1631 IMB65F_0_0_CHECK_SUM "ﾁｪｯｸｻﾑ
";
CM_ SG_ 1625 PSM659_5_4_REQ_BTN_MIRCON_PTN "ミラコン画面ボタン表示要求
";
CM_ SG_ 1625 PSM659_4_4_REQ_BTN_TRAY_SEAT "トレイ画面シートボタン表示要求
";
CM_ SG_ 1625 PSM659_3_4_VAL_SEAT_AWAY "ｼｰﾄ後退設定値
";
CM_ SG_ 1625 PSM659_3_6_VAL_SEAT_AWAY_AMOUNT "シート後退量設定値
";
CM_ SG_ 1625 PSM659_2_4_DVR_SEAT_POSI_MNL_MOV "D席シート位置マニュアル作動フラグ
";
CM_ SG_ 1625 PSM659_1_0_MSG_COUNTER "ﾒｯｾｰｼﾞｶｳﾝﾀ
";
CM_ SG_ 1625 PSM659_0_0_CHECK_SUM "ﾁｪｯｸｻﾑ
";
CM_ SG_ 1660 MED67C_6_0_STATE_AFOLD_MIR_SW "電格SW状態
";
CM_ SG_ 1660 MED67C_6_2_STATE_LR_MIR_SW "鏡面SW左右選択状態
";
CM_ SG_ 1660 MED67C_6_4_ENBL_AFOLD_MIR_SW "電格SW有効無効
";
CM_ SG_ 1660 MED67C_4_2_VAL_MIR_RTILT_L "リバース連動ドアミラー左　設定値
";
CM_ SG_ 1660 MED67C_4_3_VAL_MIR_RTILT_R "リバース連動ドアミラー右　設定値
";
CM_ SG_ 1660 MED67C_4_4_VAL_MIR_RTILT_AMOUNT_ "リバース連動チルトダウン量　左　設定値
";
CM_ SG_ 1660 MED67C_4_6_VAL_MIR_RTILT_AMOUNT_ "リバース連動チルトダウン量　右　設定値
";
CM_ SG_ 1660 MED67C_3_5_VAL_MIR_AFOLD "ｵｰﾄ電動格納ドアミラー設定値
";
CM_ SG_ 1660 MED67C_1_0_MSG_COUNTER "ﾒｯｾｰｼﾞｶｳﾝﾀ
";
CM_ SG_ 1660 MED67C_0_0_CHECK_SUM "ﾁｪｯｸｻﾑ
";
CM_ SG_ 1645 PRG66D_4_0_BUZZER_RQ_PRG "PRGﾌﾞｻﾞｰ吹鳴要求
";
CM_ SG_ 1645 PRG66D_4_7_PRG_HF_ON_OFF "PRGハンズフリーON/OFF状態
";
CM_ SG_ 1645 PRG66D_3_1_PRG_MEMORY_ON_OFF "PRGﾒﾓﾘ機能　ON/OFF状態
";
CM_ SG_ 1645 PRG66D_3_3_PRG_LOCK_SW_RQ "PRGﾛｯｸSW作動要求
";
CM_ SG_ 1645 PRG66D_3_5_KICK_CSTM_TIMER "ｷｯｸｾﾝｻｶｽﾀﾏｲｽﾞ時間
";
CM_ SG_ 1645 PRG66D_2_2_HAZARD "ハザード信号
";
CM_ SG_ 1645 PRG66D_1_0_MSG_COUNTER "ﾒｯｾｰｼﾞｶｳﾝﾀ
";
CM_ SG_ 1645 PRG66D_0_0_CHECK_SUM "ﾁｪｯｸｻﾑ
";
CM_ SG_ 1646 PRG66E_7_0_FACT_PRG_REFUSE_FAIL "PRG作動拒否要因（故障）
";
CM_ SG_ 1646 PRG66E_6_0_FACT_PRG_REFUSE "PRG作動拒否要因（故障除く）
";
CM_ SG_ 1646 PRG66E_5_5_PERMIT_PRG_OPER "PRG作動可否
";
CM_ SG_ 1646 PRG66E_4_0_PERM_PRG_OPER_OPEN "PRG閉作動可否
";
CM_ SG_ 1646 PRG66E_4_1_PERM_PRG_OPER_OPEN "PRG開作動可否
";
CM_ SG_ 1646 PRG66E_4_2_FACT_PRG_OPER "PRG作動要因
";
CM_ SG_ 1646 PRG66E_4_6_CUR_RG_STATE "リヤゲート現在位置
";
CM_ SG_ 1646 PRG66E_3_0_CUR_POS_RG "リヤゲート全閉からの位置
";
CM_ SG_ 1646 PRG66E_2_4_SW_PRG_PULS_CLOSE "PRGプルスタート作動　閉方向
";
CM_ SG_ 1646 PRG66E_2_5_SW_PRG_PULS_OPEN "PRGプルスタート作動　開方向
";
CM_ SG_ 1646 PRG66E_2_6_SW_PRG_LOCK "PRGロックSW ON/OFF
";
CM_ SG_ 1646 PRG66E_2_7_SW_PRG_INNER "PRGインナーSW ON/OFF
";
CM_ SG_ 1646 PRG66E_1_0_MSG_COUNTER "メッセージカウンタ
";
CM_ SG_ 1646 PRG66E_1_4_STATUS_PRG_OPER "PRG作動状態
";
CM_ SG_ 1646 PRG66E_1_7_PERMIT_MEM_POS_PRG "PRGメモリー位置登録　許可状態
";
CM_ SG_ 1646 PRG66E_0_0_CHECK_SUM "チェックサム
";
CM_ SG_ 818 PMN332_7_0_RES_CONTROL_STATUS "リモスタ制御状態
";
CM_ SG_ 818 PMN332_7_2_REQ_RES_P_LOCK "ﾘﾓｽﾀ制御ｼﾌﾄPﾛｯｸ要求
";
CM_ SG_ 818 PMN332_7_5_IGB_RELAY_REQ "IGbリレー指示値
";
CM_ SG_ 818 PMN332_7_6_IGA_RELAY_REQ "IGaリレー指示値
";
CM_ SG_ 818 PMN332_7_7_REQ_STOP_RES "ﾘﾓｽﾀ停止要求
";
CM_ SG_ 818 PMN332_6_0_RES_IDLE_TIME "ﾘﾓｽﾀ累積ｴﾝｼﾞﾝON時間
";
CM_ SG_ 818 PMN332_6_7_CUST "自動E/G停止カスタマイズ設定値
";
CM_ SG_ 818 PMN332_5_0_PUSHSTART_SW "ﾌﾟｯｼｭｽﾀｰﾄSW信号
";
CM_ SG_ 818 PMN332_5_1_SIG_KEY_PUSHSTART "ﾌﾟｯｼｭｽﾀｰﾄ用ｷｰ信号
";
CM_ SG_ 818 PMN332_5_2_STATE_MODE_POWER "電源ﾓｰﾄﾞ状態信号
";
CM_ SG_ 818 PMN332_5_4_BUZ_2SHOT_IN "室内ﾌﾞｻﾞｰ　単発2回吹鳴要求
";
CM_ SG_ 818 PMN332_5_5_BUZ_INTERMIT1_IN "室内ﾌﾞｻﾞｰ　断続吹鳴1要求
";
CM_ SG_ 818 PMN332_5_6_BUZ_INTERMIT2_IN "室内ﾌﾞｻﾞｰ　断続吹鳴2要求(0.7s周期)
";
CM_ SG_ 818 PMN332_5_7_BUZ_CONTINUE_IN "室内ﾌﾞｻﾞｰ　連続吹鳴要求
";
CM_ SG_ 818 PMN332_2_0_WARN_SSP_SIG1 "ｽﾏｰﾄｼｽﾃﾑ警報信号(電源)1
";
CM_ SG_ 818 PMN332_2_1_WARN_SSP_SIG2 "ｽﾏｰﾄｼｽﾃﾑ警報信号(電源)2
";
CM_ SG_ 818 PMN332_2_4_SMT_PWR_SIG "ｽﾏｰﾄｼｽﾃﾑ電源状態信号
";
CM_ SG_ 818 PMN332_2_7_BUZ_1SHOT_IN "室内ﾌﾞｻﾞｰ　単発1回吹鳴
";
CM_ SG_ 818 PMN332_1_0_MSG_COUNTER "ﾒｯｾｰｼﾞｶｳﾝﾀ
";
CM_ SG_ 818 PMN332_0_0_CHECK_SUM "ﾁｪｯｸｻﾑ
";
CM_ SG_ 816 SMT330_7_0 "プッシュSW故障
";
CM_ SG_ 816 SMT330_7_1 "IG OFF予告
";
CM_ SG_ 816 SMT330_7_3_HF_CAPA_ERR_ST "HFｾﾝｻｰ静電容量異常状態
";
CM_ SG_ 816 SMT330_7_6_HF_RESP_ERR_ST "HFｾﾝｻｰﾚｽﾎﾟﾝｽｴﾗｰ
";
CM_ SG_ 816 SMT330_6_0_REQ_MESS_PUSHSTART "ﾌﾟｯｼｭｽﾀｰﾄﾒｯｾｰｼﾞ要求
";
CM_ SG_ 816 SMT330_6_4_WARN_SSP_SIG1 "ｽﾏｰﾄｼｽﾃﾑ警報信号1
";
CM_ SG_ 816 SMT330_5_1_WIUL_CUST "WIUL機能ｶｽﾀﾏｲｽﾞ
";
CM_ SG_ 816 SMT330_5_2_WAL_CUST "WAL機能ｶｽﾀﾏｲｽﾞ
";
CM_ SG_ 816 SMT330_5_3_WARN_SSP_SIG2 "ｽﾏｰﾄｼｽﾃﾑ警報信号2
";
CM_ SG_ 816 SMT330_5_5_WARN_SSP_SIG3 "ｽﾏｰﾄｼｽﾃﾑ警報信号3
";
CM_ SG_ 816 SMT330_4_0_PUSHSTART_SW "ﾌﾟｯｼｭｽﾀｰﾄSW信号
";
CM_ SG_ 816 SMT330_4_1_SIG_KEY_PUSHSTART "ﾌﾟｯｼｭｽﾀｰﾄ用ｷｰ信号
";
CM_ SG_ 816 SMT330_4_2_HF_TOUCH_STATUS "HFｾﾝｻｰ検出状態
";
CM_ SG_ 816 SMT330_4_5_HF_KICK_STATUS "ｷｯｸｾﾝｻｰ検出状態
";
CM_ SG_ 816 SMT330_3_0_BUZ_1SHOT_IN "室内ﾌﾞｻﾞｰ　単発1回吹鳴要求
";
CM_ SG_ 816 SMT330_3_1_BUZ_2SHOT_IN "室内ﾌﾞｻﾞｰ　単発2回吹鳴要求
";
CM_ SG_ 816 SMT330_3_2_BUZ_INTERMIT1_IN "室内ﾌﾞｻﾞｰ　断続吹鳴1要求
";
CM_ SG_ 816 SMT330_3_3_BUZ_INTERMIT2_IN "室内ﾌﾞｻﾞｰ　断続吹鳴2要求（0.7s周期）
";
CM_ SG_ 816 SMT330_3_4_BUZ_CONTINUE_IN "室内ﾌﾞｻﾞｰ　連続吹鳴要求
";
CM_ SG_ 816 SMT330_3_5_BUZ_TRPON_OK_IN "室内ﾌﾞｻﾞｰ　ﾄﾗﾎﾟﾝ照合完了通知要求
";
CM_ SG_ 816 SMT330_3_6_STATE_MODE_POWER "電源ﾓｰﾄﾞ状態信号
";
CM_ SG_ 816 SMT330_1_0_MSG_COUNTER "ﾒｯｾｰｼﾞｶｳﾝﾀ
";
CM_ SG_ 816 SMT330_1_4_WAKE_UP_FRAME "ｳｪｲｸｱｯﾌﾟﾌﾚｰﾑ識別ﾌﾗｸﾞ
";
CM_ SG_ 816 SMT330_1_5_REQ_COMM_CONT "通信継続要求ﾌﾗｸﾞ
";
CM_ SG_ 816 SMT330_1_6 "予約:通信継続要求ﾌﾗｸﾞ(拡張)
";
CM_ SG_ 816 SMT330_0_0_CHECK_SUM "ﾁｪｯｸｻﾑ
";
CM_ SG_ 1622 BIU656_6_0_KICK_OPEN_REQ_PRG "ｷｯｸ要因PRGｵｰﾌﾟﾝ要求
";
CM_ SG_ 1622 BIU656_6_1_KICK_CLOSE_REQ_PRG "ｷｯｸ要因PRGｸﾛｰｽﾞ要求
";
CM_ SG_ 1622 BIU656_6_6_CARGO_LAMP_OUT "カーゴランプ出力情報
";
CM_ SG_ 1622 BIU656_6_7_PERMITT_KEY_RG_UNL "キーレス R/G SW RG解錠許可状態
";
CM_ SG_ 1622 BIU656_5_0_PRG_DRVR_OPENERSW "PRGD席ｵｰﾌﾟﾅSW
";
CM_ SG_ 1622 BIU656_5_1_HF_PRG_OFF_SW "ﾊﾝｽﾞﾌﾘｰPRG OFF SW
";
CM_ SG_ 1622 BIU656_5_2_PERMIT_OPEN_RG "R/Gｵｰﾌﾟﾝ許可状態
";
CM_ SG_ 1622 BIU656_5_3_BUZ_ON_OFF "ﾌﾞｻﾞｰ吹鳴ON/OFF
";
CM_ SG_ 1622 BIU656_5_4_PRG_DRVR_SW_PERMIT "PRG D席ｵｰﾌﾟﾅｰSW許可状態
";
CM_ SG_ 1622 BIU656_5_5_CSTM_HF_PRG_LOCK "ﾊﾝｽﾞﾌﾘｰPRGﾛｯｸ有無
";
CM_ SG_ 1622 BIU656_5_6_CSTM_KICK_SENSOR "ｷｯｸｾﾝｻ有無
";
CM_ SG_ 1622 BIU656_5_7_KICK_REQ_PRG "ｷｯｸ要因PRG駆動要求
";
CM_ SG_ 1622 BIU656_4_0_NOT_SMT_KEY_RG_SW "ｷｰﾚｽ R/G SW（ｽﾏｰﾄ無し車）
";
CM_ SG_ 1622 BIU656_4_2_SMT_KEY_RG_SW "ｷｰﾚｽ R/G SW（ｽﾏｰﾄ有り車）
";
CM_ SG_ 1622 BIU656_4_4_OPEN_RG_OPENER_SW "RｹﾞｰﾄｵｰﾌﾟﾅSW駆動処理
";
CM_ SG_ 1622 BIU656_3_4_CHECKED_KEYNO "照合ｷｰNo.
";
CM_ SG_ 1622 BIU656_3_7_LOCKSTATUS_DRVR "ﾄﾞｱﾛｯｸ状態信号（運席）
";
CM_ SG_ 1622 BIU656_2_0_TRIG_LOCK_UNLOCK "ﾄﾞｱﾛｯｸ/ｱﾝﾛｯｸ出力情報
";
CM_ SG_ 1622 BIU656_1_0_MSG_COUNTER "ﾒｯｾｰｼﾞｶｳﾝﾀ
";
CM_ SG_ 1622 BIU656_0_0_CHECK_SUM "ﾁｪｯｸｻﾑ
";
CM_ SG_ 1621 BIU655_4_0_BUZZER_PATTERN "ﾌﾞｻﾞｰ出力ﾊﾟﾀｰﾝ要求
";
CM_ SG_ 1621 BIU655_3_0_BUZZER_VOL_REQ "室外ﾌﾞｻﾞｰ音量要求
";
CM_ SG_ 1621 BIU655_3_3_RDEF_RELAY_REQ "ﾘｱﾃﾞﾌｫｯｶﾞ出力要求
";
CM_ SG_ 1621 BIU655_3_4_WIPER_DEICER_REQ "ﾜｲﾊﾟﾃﾞｱｲｻ出力要求
";
CM_ SG_ 1621 BIU655_3_5_FT_WIPER_REQ "Fﾜｲﾊﾟ駆動要求
";
CM_ SG_ 1621 BIU655_2_0_RR_WIPER_REQ "Rﾜｲﾊﾟ駆動要求
";
CM_ SG_ 1621 BIU655_2_1_WASHER_REQ "ｳｫｯｼｬ出力要求
";
CM_ SG_ 1621 BIU655_2_3_HL_WASHER_REQ "H/Lｳｫｯｼｬ出力要求
";
CM_ SG_ 1621 BIU655_2_4_FT_FOG_RELAY_REQ "Fﾌｫｸﾞﾗﾝﾌﾟﾘﾚｰ出力要求
";
CM_ SG_ 1621 BIU655_2_5_HEADLAMP_HI_REQ "ﾗｲﾃｨﾝｸﾞHi出力要求
";
CM_ SG_ 1621 BIU655_2_7_HEADLAMP_LO_REQ "ﾗｲﾃｨﾝｸﾞLo出力要求
";
CM_ SG_ 1621 BIU655_1_0_MSG_COUNTER "ﾒｯｾｰｼﾞｶｳﾝﾀ
";
CM_ SG_ 1621 BIU655_0_0_CHECK_SUM "ﾁｪｯｸｻﾑ
";
CM_ SG_ 1620 BIU654_7_4_KEYSW "ｷｰSW
";
CM_ SG_ 1620 BIU654_7_5_ALARM "ｱﾗｰﾑｼｽﾃﾑ情報
";
CM_ SG_ 1620 BIU654_7_6_RES_STOP_JPN "ｴﾝｽﾀ停止要求
";
CM_ SG_ 1620 BIU654_6_0_CONT_DATA_FOR_RES "RES用ｺﾏﾝﾄﾞ
";
CM_ SG_ 1620 BIU654_2_0_CODE_IMB_FOR_RES "Iﾃﾞｰﾀ
";
CM_ SG_ 1620 BIU654_1_0_MSG_COUNTER "ﾒｯｾｰｼﾞｶｳﾝﾀ
";
CM_ SG_ 1620 BIU654_0_0_CHECK_SUM "ﾁｪｯｸｻﾑ
";
CM_ SG_ 1618 BIU652_7_0_IND_SECURITY_IMB "ｾｷｭﾘﾃｨ(ｲﾓﾋﾞ)ｲﾝｼﾞｹｰﾀ表示
";
CM_ SG_ 1618 BIU652_6_0_OCCUPATION_3RDRH "3列目右乗員有無信号
";
CM_ SG_ 1618 BIU652_6_1_OCCUPATION_3RDCTR "3列目中央乗員有無信号
";
CM_ SG_ 1618 BIU652_6_2_OCCUPATION_3RDLH "3列目左乗員有無信号
";
CM_ SG_ 1618 BIU652_6_3_OCCUPATION_RRRH "後席右乗員有無信号
";
CM_ SG_ 1618 BIU652_6_4_OCCUPATION_RRCTR "後席中央乗員有無信号
";
CM_ SG_ 1618 BIU652_6_5_OCCUPATION_RRLH "後席左乗員有無信号
";
CM_ SG_ 1618 BIU652_6_6_HORNHAZARD_RES_SIG "ﾘﾓｰﾄﾎｰﾝ&ﾗｲﾄ応答信号
";
CM_ SG_ 1618 BIU652_6_7_OCCUPATION_DRVR "D席乗員有無信号
";
CM_ SG_ 1618 BIU652_5_0_STATUS_ROOMLAMP "ﾙｰﾑﾗﾝﾌﾟ状態
";
CM_ SG_ 1618 BIU652_5_3_HEADLAMP_SMALL "ﾍｯﾄﾞﾗﾝﾌﾟ　ｽﾓｰﾙ
";
CM_ SG_ 1618 BIU652_5_4_ALL_UNLOCK_STATE "全席ｱﾝﾛｯｸ出力状態
";
CM_ SG_ 1618 BIU652_5_5_DRVR_UNLOCK_STATE "運転席ｱﾝﾛｯｸ出力状態
";
CM_ SG_ 1618 BIU652_5_6_ALL_LOCK_STATE "全席ﾛｯｸ出力状態
";
CM_ SG_ 1618 BIU652_4_0_TRIG_LOCK_UNLOCK "ﾄﾞｱﾛｯｸ/ｱﾝﾛｯｸ出力要因信号
";
CM_ SG_ 1618 BIU652_3_0_DOOR_DRVR "ﾄﾞｱSW　D席
";
CM_ SG_ 1618 BIU652_3_1_DOOR_PASS "ﾄﾞｱSW　P席
";
CM_ SG_ 1618 BIU652_3_2_DOOR_RRRH "ﾄﾞｱSW　後席右
";
CM_ SG_ 1618 BIU652_3_3_DOOR_RRLH "ﾄﾞｱSW　後席左
";
CM_ SG_ 1618 BIU652_3_4_DOOR_RG "ﾄﾞｱSW　Rｹﾞｰﾄ
";
CM_ SG_ 1618 BIU652_3_5_DOOR_TR "ﾄﾞｱSW　ﾄﾗﾝｸ
";
CM_ SG_ 1618 BIU652_3_7_OPENSW_RG "ﾘﾔｹﾞｰﾄｵｰﾌﾟﾅSW信号
";
CM_ SG_ 1618 BIU652_2_0_LOCKSTATUS_DRVR "ﾄﾞｱﾛｯｸ状態信号（運席）
";
CM_ SG_ 1618 BIU652_2_1_LOCKSTATUS_PASS "ﾄﾞｱﾛｯｸ状態信号（助手席）
";
CM_ SG_ 1618 BIU652_2_2_LOCKSTATUS_RRRH "ﾄﾞｱﾛｯｸ状態信号（後席右）
";
CM_ SG_ 1618 BIU652_2_3_LOCKSTATUS_RRLH "ﾄﾞｱﾛｯｸ状態信号（後席左）
";
CM_ SG_ 1618 BIU652_2_4_LOCKSTATUS_RG "ﾄﾞｱﾛｯｸ状態信号（Rｹﾞｰﾄ）
";
CM_ SG_ 1618 BIU652_2_6_UNLOCK_DOORKEYSW "ﾄﾞｱｷｰSW　ｱﾝﾛｯｸ
";
CM_ SG_ 1618 BIU652_2_7_LOCK_DOORKEYSW "ﾄﾞｱｷｰSW ﾛｯｸ
";
CM_ SG_ 1618 BIU652_1_0_MSG_COUNTER "ﾒｯｾｰｼﾞｶｳﾝﾀ
";
CM_ SG_ 1618 BIU652_0_0_CHECK_SUM "ﾁｪｯｸｻﾑ
";
CM_ SG_ 1617 BIU651_7_0_PWPOS_RL "RL席窓位置
";
CM_ SG_ 1617 BIU651_7_2_PWPOS_RR "RR席窓位置
";
CM_ SG_ 1617 BIU651_7_4_PWPOS_PASS "P席窓位置
";
CM_ SG_ 1617 BIU651_7_6_PWPOS_DRVR "D席窓位置
";
CM_ SG_ 1617 BIU651_6_0_IND_ACTIVE_HBA "HBA作動灯
";
CM_ SG_ 1617 BIU651_6_2_ADB_ACTIVE "ADB有無ﾌﾗｸﾞ
";
CM_ SG_ 1617 BIU651_6_3_JUDGE_ILL "照度判定信号
";
CM_ SG_ 1617 BIU651_6_4_TYPE_LO_BEAM "Loﾋﾞｰﾑ光源種類
";
CM_ SG_ 1617 BIU651_6_6_TYPE_HI_BEAM "Hiﾋﾞｰﾑ光源種類
";
CM_ SG_ 1617 BIU651_5_0_SRF_ACTIVE "SRF有無ﾌﾗｸﾞ
";
CM_ SG_ 1617 BIU651_5_1_SRF_IND "SRF OFF ｲﾝｼﾞｹｰﾀ
";
CM_ SG_ 1617 BIU651_5_3_SRF_LAMP_LIGHT "SRF（右）点灯状態
";
CM_ SG_ 1617 BIU651_5_4_SRF_LAMP_LEFT "SRF（左）点灯状態
";
CM_ SG_ 1617 BIU651_5_5_MSG_STATUS_HBA "HBA文言表示
";
CM_ SG_ 1617 BIU651_5_7_IND_FAIL_HBA "HBAﾌｪｰﾙ灯
";
CM_ SG_ 1617 BIU651_4_0_BUZ_PATTERN "ﾌﾞｻﾞｰ吹鳴ﾊﾟﾀｰﾝ情報
";
CM_ SG_ 1617 BIU651_4_4_CSTM_OPE_ALARM "ｾｷｭﾘﾃｨｱﾗｰﾑ　ｶｽﾀﾏｲｽﾞ
";
CM_ SG_ 1617 BIU651_4_6_CSTM_HBA "HBA（ﾐﾗｰ/ｱｲｻｲﾄ）有無ﾌﾗｸﾞ
";
CM_ SG_ 1617 BIU651_3_0_HEADLAMP_PASS_SW "ﾍｯﾄﾞﾗﾝﾌﾟ　PASSｽｲｯﾁ
";
CM_ SG_ 1617 BIU651_3_1_HEADLAMP_AUTO_SW "ﾍｯﾄﾞﾗﾝﾌﾟ　AUTOｽｲｯﾁ
";
CM_ SG_ 1617 BIU651_3_2_JUDGE_DOOR_LOCK "室内照明制御用ﾄﾞｱﾛｯｸ判定ﾌﾗｸﾞ
";
CM_ SG_ 1617 BIU651_3_3_JUDGE_DOOR_UNLOCK "室内照明制御用ﾄﾞｱｱﾝﾛｯｸ判定
";
CM_ SG_ 1617 BIU651_3_4_HEADLAMP_Lo_SW "ﾍｯﾄﾞﾗﾝﾌﾟ　Loｽｲｯﾁ
";
CM_ SG_ 1617 BIU651_3_5_HEADLAMP_HI_SW "ﾍｯﾄﾞﾗﾝﾌﾟ　Hiｽｲｯﾁ
";
CM_ SG_ 1617 BIU651_3_6_WIPER_AUTO_SW "ﾜｲﾊﾟｰ AUTO SW
";
CM_ SG_ 1617 BIU651_3_7_PRG_LIN_MEMORY_ON_OFF "PRG LIN通信用 メモリ機能 ON/OFF状態
";
CM_ SG_ 1617 BIU651_2_0_CSTM_ILLUMI_SSR "照度ｾﾝｻ有無ﾌﾗｸﾞ
";
CM_ SG_ 1617 BIU651_2_1_HANDLE "ﾊﾝﾄﾞﾙ情報
";
CM_ SG_ 1617 BIU651_2_2_CSTM_SMT "ｽﾏｰﾄ有無
";
CM_ SG_ 1617 BIU651_2_3_AJARDOOR_STATUS "半ﾄﾞｱ判定結果
";
CM_ SG_ 1617 BIU651_2_4_ONETOUCH_LAMP_OUT "ﾜﾝﾀｯﾁ全照明出力
";
CM_ SG_ 1617 BIU651_2_5_PRG_FAIL_FLAG "PRG通信異常フラグ
";
CM_ SG_ 1617 BIU651_2_6_CSTM_PSMECU "ｼｰﾄﾒﾓﾘ有無ﾌﾗｸﾞ
";
CM_ SG_ 1617 BIU651_2_7_STATE_REGIST_DEL "ﾒﾓﾘ登録/消去状態ﾌﾗｸﾞ
";
CM_ SG_ 1617 BIU651_1_0_MSG_COUNTER "ﾒｯｾｰｼﾞｶｳﾝﾀ
";
CM_ SG_ 1617 BIU651_1_4_SRPOS "サンルーフガラス位置
";
CM_ SG_ 1617 BIU651_1_7_WIPER_INT_STATUS "Fﾜｲﾊﾟ間欠作動状態
";
CM_ SG_ 1617 BIU651_0_0_CHECK_SUM "ﾁｪｯｸｻﾑ
";
CM_ SG_ 995 BIU3E3_7_2_FAIL_HUMID "湿度ｾﾝｻ故障
";
CM_ SG_ 995 BIU3E3_6_0_DATA_HUMID "湿度ｾﾝｻ
";
CM_ SG_ 995 BIU3E3_5_2_FAIL_HUMID_ATM_TMP "湿度(雰囲気温度)ｾﾝｻ故障
";
CM_ SG_ 995 BIU3E3_4_0_DATA_HUMID_ATM_TMP "湿度(雰囲気温度)ｾﾝｻ
";
CM_ SG_ 995 BIU3E3_3_2_FAIL_HUMID_GLA_TMP "湿度(窓ｶﾞﾗｽ温度)ｾﾝｻ故障
";
CM_ SG_ 995 BIU3E3_3_6_STATUS_HUMID "湿度ｾﾝｻｽﾃｰﾀｽ
";
CM_ SG_ 995 BIU3E3_2_0_DATA_HUMID_GLA_TMP "湿度(窓ｶﾞﾗｽ温度)ｾﾝｻ
";
CM_ SG_ 995 BIU3E3_1_0_MSG_COUNTER "ﾒｯｾｰｼﾞｶｳﾝﾀ
";
CM_ SG_ 995 BIU3E3_1_4_CSTM_HUMID "湿度ｾﾝｻ有無
";
CM_ SG_ 995 BIU3E3_1_5_COMM_HUMID "湿度ｾﾝｻ通信状態
";
CM_ SG_ 995 BIU3E3_1_7_RX_FAIL_HUMID "LIN通信受信ﾃﾞｰﾀ異常1
";
CM_ SG_ 995 BIU3E3_0_0_CHECK_SUM "ﾁｪｯｸｻﾑ
";
CM_ SG_ 942 BIU3AE_5_0_WIPER_FT_VOLUME "ﾄﾞﾗｲﾊﾞAUTO感度設定
";
CM_ SG_ 942 BIU3AE_4_0_DATA_RAINDROP "雨滴情報
";
CM_ SG_ 942 BIU3AE_4_4_FT_WIPER_FAIL "Fﾜｲﾊﾟﾌｪｰﾙ状態
";
CM_ SG_ 942 BIU3AE_4_5_WIPER_FT "FtﾜｲﾊﾟSW状態
";
CM_ SG_ 942 BIU3AE_3_0_WINKER_LEVER_STATUS "ウィンカーレバー状態
";
CM_ SG_ 942 BIU3AE_3_4_WINKER_FACTOR "ｳｨﾝｶｰ出力要因
";
CM_ SG_ 942 BIU3AE_2_0_TURN_LAMP_FAIL_LEFT "メインバルブ異常検知(左)
";
CM_ SG_ 942 BIU3AE_2_1_TURN_LAMP_FAIL_RIGHT "メインバルブ異常検知(右)
";
CM_ SG_ 942 BIU3AE_2_3_HAZARD_SW "ハザードSW状態
";
CM_ SG_ 942 BIU3AE_1_0_MSG_COUNTER "ﾒｯｾｰｼﾞｶｳﾝﾀ
";
CM_ SG_ 942 BIU3AE_0_0_CHECK_SUM "ﾁｪｯｸｻﾑ
";
BA_DEF_ SG_  "Fhi_SignalComment" STRING ;
BA_DEF_ SG_  "GenSigInactiveValue" INT 0 10000;
BA_DEF_ SG_  "GenSigStartValue" FLOAT 0 100000000000;
BA_DEF_ SG_  "GenSigSendType" ENUM  "Cyclic","OnWrite","OnWriteWithRepetition","OnChange","OnChangeWithRepetition","IfActive","IfActiveWithRepetition","NoSigSendType";
BA_DEF_ BO_  "MsgRoutingId" STRING ;
BA_DEF_ BO_  "DiagResponse" ENUM  "No","Yes";
BA_DEF_ BO_  "DiagRequest" ENUM  "No","Yes";
BA_DEF_ BO_  "DiagState" ENUM  "No","Yes";
BA_DEF_ BO_  "GenMsgILSupport" ENUM  "No","Yes";
BA_DEF_ BO_  "GenMsgNrOfRepetition" INT 0 999999;
BA_DEF_ BO_  "GenMsgDelayTime" INT 0 1000;
BA_DEF_ BO_  "GenMsgCycleTimeFast" INT 0 10000;
BA_DEF_ BO_  "GenMsgCycleTime" INT 0 10000;
BA_DEF_ BO_  "GenMsgSendType" ENUM  "Cyclic","NotUsed","NotUsed","NotUsed","NotUsed","Cyclic","NotUsed","IfActive","NoMsgSendType";
BA_DEF_ BO_  "CANFD_BRS" ENUM  "0","1";
BA_DEF_ BO_  "VFrameFormat" ENUM  "StandardCAN","ExtendedCAN","reserved","reserved","reserved","reserved","reserved","reserved","reserved","reserved","reserved","reserved","reserved","reserved","StandardCAN_FD","ExtendedCAN_FD";
BA_DEF_DEF_  "Fhi_SignalComment" "";
BA_DEF_DEF_  "GenSigInactiveValue" 0;
BA_DEF_DEF_  "GenSigStartValue" 0;
BA_DEF_DEF_  "GenSigSendType" "NoSigSendType";
BA_DEF_DEF_  "MsgRoutingId" "";
BA_DEF_DEF_  "DiagResponse" "No";
BA_DEF_DEF_  "DiagRequest" "No";
BA_DEF_DEF_  "DiagState" "No";
BA_DEF_DEF_  "GenMsgILSupport" "Yes";
BA_DEF_DEF_  "GenMsgNrOfRepetition" 0;
BA_DEF_DEF_  "GenMsgDelayTime" 0;
BA_DEF_DEF_  "GenMsgCycleTimeFast" 0;
BA_DEF_DEF_  "GenMsgCycleTime" 0;
BA_DEF_DEF_  "GenMsgSendType" "Cyclic";
BA_DEF_DEF_  "CANFD_BRS" "1";
BA_DEF_DEF_  "VFrameFormat" "StandardCAN";
BA_ "GenMsgCycleTime" BO_ 914 100;
BA_ "GenMsgDelayTime" BO_ 914 10;
BA_ "GenMsgCycleTimeFast" BO_ 914 50;
BA_ "GenMsgNrOfRepetition" BO_ 914 4;
BA_ "MsgRoutingId" BO_ 914 "103 ";
BA_ "GenMsgILSupport" BO_ 914 0;
BA_ "VFrameFormat" BO_ 914 14;
BA_ "GenMsgCycleTime" BO_ 937 100;
BA_ "GenMsgDelayTime" BO_ 937 10;
BA_ "GenMsgCycleTimeFast" BO_ 937 50;
BA_ "GenMsgNrOfRepetition" BO_ 937 4;
BA_ "MsgRoutingId" BO_ 937 "102 ";
BA_ "GenMsgILSupport" BO_ 937 0;
BA_ "VFrameFormat" BO_ 937 14;
BA_ "GenMsgCycleTime" BO_ 1679 1200;
BA_ "GenMsgDelayTime" BO_ 1679 10;
BA_ "GenMsgCycleTimeFast" BO_ 1679 50;
BA_ "GenMsgNrOfRepetition" BO_ 1679 4;
BA_ "MsgRoutingId" BO_ 1679 "100 ";
BA_ "GenMsgILSupport" BO_ 1679 0;
BA_ "VFrameFormat" BO_ 1679 14;
BA_ "GenMsgCycleTime" BO_ 1678 1200;
BA_ "GenMsgDelayTime" BO_ 1678 10;
BA_ "GenMsgCycleTimeFast" BO_ 1678 50;
BA_ "GenMsgNrOfRepetition" BO_ 1678 4;
BA_ "MsgRoutingId" BO_ 1678 "99 ";
BA_ "GenMsgILSupport" BO_ 1678 0;
BA_ "VFrameFormat" BO_ 1678 14;
BA_ "GenMsgCycleTime" BO_ 1674 1200;
BA_ "GenMsgDelayTime" BO_ 1674 10;
BA_ "GenMsgCycleTimeFast" BO_ 1674 50;
BA_ "GenMsgNrOfRepetition" BO_ 1674 4;
BA_ "MsgRoutingId" BO_ 1674 "98 ";
BA_ "GenMsgILSupport" BO_ 1674 0;
BA_ "VFrameFormat" BO_ 1674 14;
BA_ "GenMsgCycleTime" BO_ 1673 1200;
BA_ "GenMsgDelayTime" BO_ 1673 10;
BA_ "GenMsgCycleTimeFast" BO_ 1673 50;
BA_ "GenMsgNrOfRepetition" BO_ 1673 4;
BA_ "MsgRoutingId" BO_ 1673 "97 ";
BA_ "GenMsgILSupport" BO_ 1673 0;
BA_ "VFrameFormat" BO_ 1673 14;
BA_ "GenMsgCycleTime" BO_ 1658 1000;
BA_ "MsgRoutingId" BO_ 1658 "95 ";
BA_ "GenMsgILSupport" BO_ 1658 0;
BA_ "VFrameFormat" BO_ 1658 14;
BA_ "GenMsgCycleTime" BO_ 1657 1000;
BA_ "MsgRoutingId" BO_ 1657 "94 ";
BA_ "GenMsgILSupport" BO_ 1657 0;
BA_ "VFrameFormat" BO_ 1657 14;
BA_ "GenMsgCycleTime" BO_ 826 120;
BA_ "GenMsgDelayTime" BO_ 826 10;
BA_ "GenMsgCycleTimeFast" BO_ 826 120;
BA_ "GenMsgNrOfRepetition" BO_ 826 50;
BA_ "MsgRoutingId" BO_ 826 "92 ";
BA_ "GenMsgILSupport" BO_ 826 0;
BA_ "VFrameFormat" BO_ 826 14;
BA_ "GenMsgCycleTime" BO_ 961 120;
BA_ "GenMsgCycleTimeFast" BO_ 961 50;
BA_ "GenMsgNrOfRepetition" BO_ 961 3;
BA_ "MsgRoutingId" BO_ 961 "91 ";
BA_ "GenMsgILSupport" BO_ 961 0;
BA_ "VFrameFormat" BO_ 961 14;
BA_ "GenMsgCycleTime" BO_ 1651 1200;
BA_ "GenMsgDelayTime" BO_ 1651 10;
BA_ "GenMsgCycleTimeFast" BO_ 1651 20;
BA_ "GenMsgNrOfRepetition" BO_ 1651 3;
BA_ "MsgRoutingId" BO_ 1651 "89 ";
BA_ "GenMsgILSupport" BO_ 1651 0;
BA_ "VFrameFormat" BO_ 1651 14;
BA_ "GenMsgCycleTime" BO_ 1650 1200;
BA_ "GenMsgDelayTime" BO_ 1650 10;
BA_ "GenMsgCycleTimeFast" BO_ 1650 20;
BA_ "GenMsgNrOfRepetition" BO_ 1650 3;
BA_ "MsgRoutingId" BO_ 1650 "88 ";
BA_ "GenMsgILSupport" BO_ 1650 0;
BA_ "VFrameFormat" BO_ 1650 14;
BA_ "GenMsgCycleTime" BO_ 722 30;
BA_ "MsgRoutingId" BO_ 722 "87 ";
BA_ "GenMsgILSupport" BO_ 722 0;
BA_ "VFrameFormat" BO_ 722 14;
BA_ "GenMsgCycleTime" BO_ 1667 1200;
BA_ "GenMsgDelayTime" BO_ 1667 10;
BA_ "GenMsgCycleTimeFast" BO_ 1667 20;
BA_ "GenMsgNrOfRepetition" BO_ 1667 3;
BA_ "MsgRoutingId" BO_ 1667 "86 ";
BA_ "GenMsgILSupport" BO_ 1667 0;
BA_ "VFrameFormat" BO_ 1667 14;
BA_ "GenMsgCycleTime" BO_ 1731 1200;
BA_ "GenMsgDelayTime" BO_ 1731 10;
BA_ "GenMsgCycleTimeFast" BO_ 1731 50;
BA_ "GenMsgNrOfRepetition" BO_ 1731 4;
BA_ "VFrameFormat" BO_ 1731 14;
BA_ "GenMsgCycleTime" BO_ 1730 1200;
BA_ "GenMsgDelayTime" BO_ 1730 10;
BA_ "GenMsgCycleTimeFast" BO_ 1730 50;
BA_ "GenMsgNrOfRepetition" BO_ 1730 4;
BA_ "MsgRoutingId" BO_ 1730 "77 ";
BA_ "VFrameFormat" BO_ 1730 14;
BA_ "GenMsgCycleTime" BO_ 1005 500;
BA_ "GenMsgDelayTime" BO_ 1005 10;
BA_ "GenMsgCycleTimeFast" BO_ 1005 20;
BA_ "GenMsgNrOfRepetition" BO_ 1005 3;
BA_ "MsgRoutingId" BO_ 1005 "76 ";
BA_ "VFrameFormat" BO_ 1005 14;
BA_ "GenMsgCycleTime" BO_ 1729 1200;
BA_ "GenMsgDelayTime" BO_ 1729 10;
BA_ "GenMsgCycleTimeFast" BO_ 1729 50;
BA_ "GenMsgNrOfRepetition" BO_ 1729 4;
BA_ "MsgRoutingId" BO_ 1729 "75 ";
BA_ "VFrameFormat" BO_ 1729 14;
BA_ "GenMsgCycleTime" BO_ 1725 1200;
BA_ "GenMsgDelayTime" BO_ 1725 10;
BA_ "GenMsgCycleTimeFast" BO_ 1725 50;
BA_ "GenMsgNrOfRepetition" BO_ 1725 4;
BA_ "MsgRoutingId" BO_ 1725 "74 ";
BA_ "VFrameFormat" BO_ 1725 14;
BA_ "GenMsgCycleTime" BO_ 1724 1200;
BA_ "GenMsgDelayTime" BO_ 1724 200;
BA_ "GenMsgCycleTimeFast" BO_ 1724 1000;
BA_ "GenMsgNrOfRepetition" BO_ 1724 1;
BA_ "MsgRoutingId" BO_ 1724 "73 ";
BA_ "VFrameFormat" BO_ 1724 14;
BA_ "GenMsgCycleTime" BO_ 1723 1200;
BA_ "GenMsgDelayTime" BO_ 1723 10;
BA_ "GenMsgCycleTimeFast" BO_ 1723 50;
BA_ "GenMsgNrOfRepetition" BO_ 1723 4;
BA_ "MsgRoutingId" BO_ 1723 "72 ";
BA_ "VFrameFormat" BO_ 1723 14;
BA_ "GenMsgDelayTime" BO_ 1722 10;
BA_ "GenMsgSendType" BO_ 1722 8;
BA_ "GenMsgCycleTimeFast" BO_ 1722 20;
BA_ "GenMsgNrOfRepetition" BO_ 1722 3;
BA_ "MsgRoutingId" BO_ 1722 "71 ";
BA_ "VFrameFormat" BO_ 1722 14;
BA_ "GenMsgCycleTime" BO_ 1713 1200;
BA_ "GenMsgDelayTime" BO_ 1713 10;
BA_ "GenMsgCycleTimeFast" BO_ 1713 20;
BA_ "GenMsgNrOfRepetition" BO_ 1713 1;
BA_ "MsgRoutingId" BO_ 1713 "70 ";
BA_ "VFrameFormat" BO_ 1713 14;
BA_ "GenMsgCycleTime" BO_ 1019 500;
BA_ "GenMsgDelayTime" BO_ 1019 10;
BA_ "GenMsgCycleTimeFast" BO_ 1019 20;
BA_ "GenMsgNrOfRepetition" BO_ 1019 3;
BA_ "MsgRoutingId" BO_ 1019 "69 ";
BA_ "VFrameFormat" BO_ 1019 14;
BA_ "GenMsgCycleTime" BO_ 1299 1000;
BA_ "VFrameFormat" BO_ 1299 14;
BA_ "GenMsgCycleTime" BO_ 1696 1200;
BA_ "GenMsgDelayTime" BO_ 1696 10;
BA_ "GenMsgCycleTimeFast" BO_ 1696 50;
BA_ "GenMsgNrOfRepetition" BO_ 1696 2;
BA_ "MsgRoutingId" BO_ 1696 "66 ";
BA_ "GenMsgILSupport" BO_ 1696 0;
BA_ "VFrameFormat" BO_ 1696 14;
BA_ "GenMsgCycleTime" BO_ 1635 1000;
BA_ "MsgRoutingId" BO_ 1635 "65 ";
BA_ "GenMsgILSupport" BO_ 1635 0;
BA_ "VFrameFormat" BO_ 1635 14;
BA_ "GenMsgCycleTime" BO_ 985 200;
BA_ "MsgRoutingId" BO_ 985 "64 ";
BA_ "GenMsgILSupport" BO_ 985 0;
BA_ "VFrameFormat" BO_ 985 14;
BA_ "GenMsgDelayTime" BO_ 1631 10;
BA_ "GenMsgSendType" BO_ 1631 8;
BA_ "GenMsgCycleTimeFast" BO_ 1631 20;
BA_ "GenMsgNrOfRepetition" BO_ 1631 1;
BA_ "MsgRoutingId" BO_ 1631 "63 ";
BA_ "GenMsgILSupport" BO_ 1631 0;
BA_ "VFrameFormat" BO_ 1631 14;
BA_ "GenMsgCycleTime" BO_ 1626 1200;
BA_ "GenMsgDelayTime" BO_ 1626 15;
BA_ "GenMsgCycleTimeFast" BO_ 1626 120;
BA_ "GenMsgNrOfRepetition" BO_ 1626 4;
BA_ "VFrameFormat" BO_ 1626 14;
BA_ "GenMsgCycleTime" BO_ 1625 1200;
BA_ "GenMsgDelayTime" BO_ 1625 15;
BA_ "GenMsgCycleTimeFast" BO_ 1625 120;
BA_ "GenMsgNrOfRepetition" BO_ 1625 4;
BA_ "VFrameFormat" BO_ 1625 14;
BA_ "GenMsgCycleTime" BO_ 1660 1200;
BA_ "GenMsgDelayTime" BO_ 1660 15;
BA_ "GenMsgCycleTimeFast" BO_ 1660 120;
BA_ "GenMsgNrOfRepetition" BO_ 1660 4;
BA_ "VFrameFormat" BO_ 1660 14;
BA_ "GenMsgCycleTime" BO_ 1645 1000;
BA_ "GenMsgDelayTime" BO_ 1645 10;
BA_ "GenMsgNrOfRepetition" BO_ 1645 1;
BA_ "VFrameFormat" BO_ 1645 14;
BA_ "GenMsgCycleTime" BO_ 1646 1000;
BA_ "GenMsgDelayTime" BO_ 1646 10;
BA_ "GenMsgNrOfRepetition" BO_ 1646 1;
BA_ "MsgRoutingId" BO_ 1646 "62 ";
BA_ "GenMsgILSupport" BO_ 1646 0;
BA_ "VFrameFormat" BO_ 1646 14;
BA_ "GenMsgCycleTime" BO_ 818 120;
BA_ "GenMsgDelayTime" BO_ 818 10;
BA_ "GenMsgNrOfRepetition" BO_ 818 1;
BA_ "MsgRoutingId" BO_ 818 "61 ";
BA_ "GenMsgILSupport" BO_ 818 0;
BA_ "VFrameFormat" BO_ 818 14;
BA_ "GenMsgCycleTime" BO_ 816 120;
BA_ "GenMsgDelayTime" BO_ 816 10;
BA_ "MsgRoutingId" BO_ 816 "57 ";
BA_ "GenMsgILSupport" BO_ 816 0;
BA_ "VFrameFormat" BO_ 816 14;
BA_ "GenMsgCycleTime" BO_ 1622 1000;
BA_ "GenMsgDelayTime" BO_ 1622 10;
BA_ "GenMsgCycleTimeFast" BO_ 1622 20;
BA_ "GenMsgNrOfRepetition" BO_ 1622 10;
BA_ "MsgRoutingId" BO_ 1622 "56 ";
BA_ "GenMsgILSupport" BO_ 1622 0;
BA_ "VFrameFormat" BO_ 1622 14;
BA_ "GenMsgCycleTime" BO_ 1621 1000;
BA_ "GenMsgDelayTime" BO_ 1621 10;
BA_ "GenMsgCycleTimeFast" BO_ 1621 20;
BA_ "GenMsgNrOfRepetition" BO_ 1621 10;
BA_ "VFrameFormat" BO_ 1621 14;
BA_ "GenMsgCycleTime" BO_ 1620 1200;
BA_ "GenMsgDelayTime" BO_ 1620 10;
BA_ "MsgRoutingId" BO_ 1620 "54 ";
BA_ "GenMsgILSupport" BO_ 1620 0;
BA_ "VFrameFormat" BO_ 1620 14;
BA_ "GenMsgCycleTime" BO_ 1618 1200;
BA_ "GenMsgDelayTime" BO_ 1618 10;
BA_ "MsgRoutingId" BO_ 1618 "53 ";
BA_ "GenMsgILSupport" BO_ 1618 0;
BA_ "VFrameFormat" BO_ 1618 14;
BA_ "GenMsgCycleTime" BO_ 1617 1200;
BA_ "GenMsgDelayTime" BO_ 1617 10;
BA_ "MsgRoutingId" BO_ 1617 "52 ";
BA_ "GenMsgILSupport" BO_ 1617 0;
BA_ "VFrameFormat" BO_ 1617 14;
BA_ "GenMsgCycleTime" BO_ 995 200;
BA_ "MsgRoutingId" BO_ 995 "51 ";
BA_ "GenMsgILSupport" BO_ 995 0;
BA_ "VFrameFormat" BO_ 995 14;
BA_ "GenMsgCycleTime" BO_ 942 100;
BA_ "GenMsgDelayTime" BO_ 942 10;
BA_ "GenMsgCycleTimeFast" BO_ 942 20;
BA_ "GenMsgNrOfRepetition" BO_ 942 2;
BA_ "MsgRoutingId" BO_ 942 "50 ";
BA_ "GenMsgILSupport" BO_ 942 0;
BA_ "VFrameFormat" BO_ 942 14;
BA_ "GenSigStartValue" SG_ 914 MET392_23_0_ADD_ACNON_DRVRANG 2046;
BA_ "GenSigStartValue" SG_ 914 MET392_21_0_ADD_ACNOFF_DRVRANG 2046;
BA_ "GenSigStartValue" SG_ 914 MET392_18_0_TRIP_LASTCHG_TOTM 1048574;
BA_ "GenSigStartValue" SG_ 914 MET392_15_0_TRIPB_TOTAL_TIME 1048574;
BA_ "GenSigStartValue" SG_ 914 MET392_12_0_TRIPA_TOTAL_TIME 1048574;
BA_ "GenSigStartValue" SG_ 1678 MET68E_4_2_CSTM_SHIFT 1;
BA_ "GenSigStartValue" SG_ 1678 MET68E_4_3_CSTM_WOW 1;
BA_ "GenSigStartValue" SG_ 1678 MET68E_4_4_CSTM_GBYE 1;
BA_ "GenSigStartValue" SG_ 1678 MET68E_4_6_CSTM_WLCM 1;
BA_ "GenSigStartValue" SG_ 1674 MET68A_19_0_AVSP_TRIPB_VAL 510;
BA_ "GenSigStartValue" SG_ 1674 MET68A_17_0_AVSP_TRIPA_VAL 65534;
BA_ "GenSigStartValue" SG_ 1674 MET68A_12_0_TEMPBAR_PER 254;
BA_ "GenSigStartValue" SG_ 1674 MET68A_11_0_FUELBAR_PER 254;
BA_ "GenSigStartValue" SG_ 1674 MET68A_9_0_TACHOREV_VAL 65535;
BA_ "GenSigStartValue" SG_ 1674 MET68A_6_1_CID_TONE_DOWN 31;
BA_ "GenSigStartValue" SG_ 1674 MET68A_4_2_TEMP_ICON 7;
BA_ "GenSigStartValue" SG_ 1673 MET689_9_3_REAR_REMIND_SUP 1;
BA_ "GenSigStartValue" SG_ 1673 MET689_9_5_TPMSDISP_SUP 1;
BA_ "GenSigStartValue" SG_ 1673 MET689_9_6_GSI_SUP 1;
BA_ "GenSigSendType" SG_ 1658 TPM67A_6_1_TIRE_COLOR_RR 3;
BA_ "GenSigSendType" SG_ 1658 TPM67A_6_5_TIRE_COLOR_RL 3;
BA_ "GenSigSendType" SG_ 1658 TPM67A_6_7_TIRE_PRESSURE_RL 3;
BA_ "GenSigSendType" SG_ 1658 TPM67A_5_0_TIRE_PRESSURE_RR 3;
BA_ "GenSigSendType" SG_ 1658 TPM67A_3_1_TIRE_COLOR_FL 3;
BA_ "GenSigSendType" SG_ 1658 TPM67A_3_5_TIRE_COLOR_FR 3;
BA_ "GenSigSendType" SG_ 1658 TPM67A_3_7_TIRE_PRESSURE_FR 3;
BA_ "GenSigSendType" SG_ 1658 TPM67A_2_0_TIRE_PRESSURE_FL 3;
BA_ "GenSigSendType" SG_ 1658 TPM67A_1_5_UNIT_IND_PRESSURE 3;
BA_ "GenSigSendType" SG_ 1658 TPM67A_1_7_IND_PRESSURE 3;
BA_ "GenSigSendType" SG_ 1657 TPM679_3_0_STATE_TPMS 3;
BA_ "Fhi_SignalComment" SG_ 1657 TPM679_3_2_DEFINED_STATE_TPMS "※閾値設定スイッチがタッチパネルの車は、送信値を0固定とする。

";
BA_ "GenSigSendType" SG_ 1657 TPM679_3_2_DEFINED_STATE_TPMS 3;
BA_ "GenSigSendType" SG_ 1657 TPM679_2_0_WARN_TPMS 3;
BA_ "GenSigSendType" SG_ 1657 TPM679_2_3_INTERRUPT 3;
BA_ "GenSigStartValue" SG_ 826 ABG33A_3_0_BELT_WRNING_PASS 2;
BA_ "GenSigStartValue" SG_ 826 ABG33A_3_4_OCCUPATION_PASS 2;
BA_ "GenSigStartValue" SG_ 826 ABG33A_2_0_IND_WARN_ABG 3;
BA_ "GenSigStartValue" SG_ 961 DMS3C1_6_2_PERMIT_AVN_FLAG 1;
BA_ "GenSigStartValue" SG_ 961 DMS3C1_6_7_NOT_DETECTED_STATUS 1;
BA_ "GenSigStartValue" SG_ 961 DMS3C1_4_0_DMS_IND_REQ_FLAG 7;
BA_ "GenSigStartValue" SG_ 961 DMS3C1_4_3_DMS_RECOG_STATUS 1;
BA_ "GenSigStartValue" SG_ 1724 AVN6BC_1_4_GNSS_STATUS 1;
BA_ "GenSigStartValue" SG_ 1723 AVN6BB_7_0_ISA_IACC_OFFSET_CSTM 10;
BA_ "GenSigSendType" SG_ 1722 AVN6BA_7_0_GUIDE_LINE_REAR 4;
BA_ "GenSigSendType" SG_ 1722 AVN6BA_7_1_GUIDE_LINE_SIDE 4;
BA_ "GenSigSendType" SG_ 1722 AVN6BA_7_2_GUIDE_LINE_FRONT 4;
BA_ "GenSigSendType" SG_ 1722 AVN6BA_7_3_STEER_ANGLE_INTERLOCK 4;
BA_ "GenSigSendType" SG_ 1722 AVN6BA_7_4_BACK_CAMERA_DELAY 4;
BA_ "GenSigSendType" SG_ 1722 AVN6BA_7_5_REQ_STOP_CAMERA_OUT 4;
BA_ "GenSigSendType" SG_ 1722 AVN6BA_7_6_VIEW_CHANGE_SW 4;
BA_ "GenSigStartValue" SG_ 1722 AVN6BA_6_0_CLIMAITE_PA_TEMP 63;
BA_ "Fhi_SignalComment" SG_ 1722 AVN6BA_6_0_CLIMAITE_PA_TEMP "分解能、ｵﾌｾｯﾄは摂氏時の値。華氏の場合はﾃﾞｰﾀｼｰﾄ参照。

";
BA_ "GenSigSendType" SG_ 1722 AVN6BA_6_0_CLIMAITE_PA_TEMP 4;
BA_ "GenSigSendType" SG_ 1722 AVN6BA_6_6_CLIMATE_SYNC 4;
BA_ "GenSigSendType" SG_ 1722 AVN6BA_6_7_CLIMATE_F_DEF 4;
BA_ "Fhi_SignalComment" SG_ 1722 AVN6BA_5_0_CLIMAITE_DR_TEMP "分解能、ｵﾌｾｯﾄは摂氏時の値。華氏の場合はﾃﾞｰﾀｼｰﾄ参照。

";
BA_ "GenSigSendType" SG_ 1722 AVN6BA_5_0_CLIMAITE_DR_TEMP 4;
BA_ "GenSigSendType" SG_ 1722 AVN6BA_5_6_CLIMAITE_AUTO 4;
BA_ "GenSigSendType" SG_ 1722 AVN6BA_5_7_CLIMAITE_MAX_AC 4;
BA_ "GenSigSendType" SG_ 1722 AVN6BA_4_0_CLIMAITE_VR 4;
BA_ "GenSigSendType" SG_ 1722 AVN6BA_4_3_CLIMATE_AC 4;
BA_ "GenSigSendType" SG_ 1722 AVN6BA_4_4_CLIMAITE_FAN 4;
BA_ "GenSigSendType" SG_ 1722 AVN6BA_3_0_PERSONAL_IC_SH 4;
BA_ "GenSigSendType" SG_ 1722 AVN6BA_3_4_CSTM_SONNER 4;
BA_ "GenSigSendType" SG_ 1722 AVN6BA_3_5_CSTM_RAB 4;
BA_ "GenSigSendType" SG_ 1722 AVN6BA_3_6_REQ_CHG_CSTM_RAB 4;
BA_ "GenSigSendType" SG_ 1722 AVN6BA_3_7_CLIMATE_R_DEF 4;
BA_ "GenSigSendType" SG_ 1722 AVN6BA_2_0_CLIMATE_PTC 4;
BA_ "GenSigSendType" SG_ 1722 AVN6BA_2_1_CLIMATE_MODE 4;
BA_ "GenSigSendType" SG_ 1722 AVN6BA_2_2_CLIMATE_SEAT_C_L 4;
BA_ "GenSigSendType" SG_ 1722 AVN6BA_2_3_CLIMATE_SEAT_C_R 4;
BA_ "GenSigSendType" SG_ 1722 AVN6BA_2_4_CLIMATE_SEAT_H_L 4;
BA_ "GenSigSendType" SG_ 1722 AVN6BA_2_5_CLIMATE_SEAT_H_R 4;
BA_ "GenSigSendType" SG_ 1722 AVN6BA_2_6_CLIMATE_INNER_AIR 4;
BA_ "GenSigSendType" SG_ 1722 AVN6BA_2_7_CLIMATE_ON_OFF 4;
BA_ "GenSigSendType" SG_ 1722 AVN6BA_1_4_CLIMAITE_STATUS 4;
BA_ "GenSigSendType" SG_ 1722 AVN6BA_1_7_CLIMAITE_ON_OFF 4;
BA_ "GenSigStartValue" SG_ 1713 AVN6B1_7_1_PRESENT_YEAR 127;
BA_ "GenSigStartValue" SG_ 1713 AVN6B1_4_0_PRESENT_TIME_SEC 60;
BA_ "GenSigStartValue" SG_ 1713 AVN6B1_3_0_PRESENT_TIME_MIN 60;
BA_ "GenSigStartValue" SG_ 1713 AVN6B1_2_1_PRESENT_TIME_HOUR 30;
BA_ "GenSigStartValue" SG_ 1019 AVN3FB_6_0_ACPANEL_PA_TEMP 63;
BA_ "GenSigStartValue" SG_ 1019 AVN3FB_5_0_ACPANEL_DR_TEMP 63;
BA_ "GenSigStartValue" SG_ 1635 AHL663_2_0_FAIL_AHL 4;
BA_ "GenSigStartValue" SG_ 985 AHL3D9_3_0_ROLL_ANGLE 255;
BA_ "GenSigStartValue" SG_ 985 AHL3D9_2_0_PITCH_ANGLE 255;
BA_ "GenSigSendType" SG_ 1631 IMB65F_2_0_DATA2 4;
BA_ "GenSigSendType" SG_ 1631 IMB65F_1_4_DATA1 4;
BA_ "GenSigStartValue" SG_ 1625 PSM659_4_4_REQ_BTN_TRAY_SEAT 2;
BA_ "GenSigSendType" SG_ 1645 PRG66D_4_0_BUZZER_RQ_PRG 3;
BA_ "GenSigSendType" SG_ 1645 PRG66D_4_7_PRG_HF_ON_OFF 3;
BA_ "GenSigSendType" SG_ 1645 PRG66D_3_1_PRG_MEMORY_ON_OFF 3;
BA_ "GenSigSendType" SG_ 1645 PRG66D_3_3_PRG_LOCK_SW_RQ 3;
BA_ "GenSigSendType" SG_ 1645 PRG66D_3_5_KICK_CSTM_TIMER 3;
BA_ "GenSigSendType" SG_ 1645 PRG66D_2_2_HAZARD 3;
BA_ "GenSigSendType" SG_ 1646 PRG66E_7_0_FACT_PRG_REFUSE_FAIL 3;
BA_ "GenSigSendType" SG_ 1646 PRG66E_6_0_FACT_PRG_REFUSE 3;
BA_ "GenSigSendType" SG_ 1646 PRG66E_5_5_PERMIT_PRG_OPER 3;
BA_ "GenSigSendType" SG_ 1646 PRG66E_4_0_PERM_PRG_OPER_OPEN 3;
BA_ "GenSigSendType" SG_ 1646 PRG66E_4_1_PERM_PRG_OPER_OPEN 3;
BA_ "GenSigSendType" SG_ 1646 PRG66E_4_2_FACT_PRG_OPER 3;
BA_ "GenSigSendType" SG_ 1646 PRG66E_4_6_CUR_RG_STATE 3;
BA_ "GenSigSendType" SG_ 1646 PRG66E_2_4_SW_PRG_PULS_CLOSE 3;
BA_ "GenSigSendType" SG_ 1646 PRG66E_2_5_SW_PRG_PULS_OPEN 3;
BA_ "GenSigSendType" SG_ 1646 PRG66E_2_6_SW_PRG_LOCK 3;
BA_ "GenSigSendType" SG_ 1646 PRG66E_2_7_SW_PRG_INNER 3;
BA_ "GenSigStartValue" SG_ 1646 PRG66E_1_4_STATUS_PRG_OPER 5;
BA_ "GenSigSendType" SG_ 1646 PRG66E_1_4_STATUS_PRG_OPER 3;
BA_ "GenSigSendType" SG_ 1646 PRG66E_1_7_PERMIT_MEM_POS_PRG 3;
BA_ "GenSigSendType" SG_ 818 PMN332_7_0_RES_CONTROL_STATUS 3;
BA_ "GenSigSendType" SG_ 818 PMN332_7_2_REQ_RES_P_LOCK 3;
BA_ "GenSigSendType" SG_ 818 PMN332_7_5_IGB_RELAY_REQ 3;
BA_ "GenSigSendType" SG_ 818 PMN332_7_6_IGA_RELAY_REQ 3;
BA_ "GenSigSendType" SG_ 818 PMN332_7_7_REQ_STOP_RES 3;
BA_ "GenSigSendType" SG_ 818 PMN332_6_0_RES_IDLE_TIME 3;
BA_ "GenSigSendType" SG_ 818 PMN332_6_7_CUST 3;
BA_ "GenSigSendType" SG_ 818 PMN332_5_0_PUSHSTART_SW 3;
BA_ "GenSigSendType" SG_ 818 PMN332_5_1_SIG_KEY_PUSHSTART 3;
BA_ "GenSigSendType" SG_ 818 PMN332_5_2_STATE_MODE_POWER 3;
BA_ "GenSigSendType" SG_ 818 PMN332_5_4_BUZ_2SHOT_IN 3;
BA_ "GenSigSendType" SG_ 818 PMN332_5_5_BUZ_INTERMIT1_IN 3;
BA_ "GenSigSendType" SG_ 818 PMN332_5_6_BUZ_INTERMIT2_IN 3;
BA_ "GenSigSendType" SG_ 818 PMN332_5_7_BUZ_CONTINUE_IN 3;
BA_ "GenSigSendType" SG_ 818 PMN332_2_0_WARN_SSP_SIG1 3;
BA_ "GenSigSendType" SG_ 818 PMN332_2_1_WARN_SSP_SIG2 3;
BA_ "GenSigSendType" SG_ 818 PMN332_2_4_SMT_PWR_SIG 3;
BA_ "GenSigSendType" SG_ 818 PMN332_2_7_BUZ_1SHOT_IN 3;
BA_ "GenSigSendType" SG_ 816 SMT330_7_0 3;
BA_ "GenSigSendType" SG_ 816 SMT330_7_1 3;
BA_ "GenSigSendType" SG_ 816 SMT330_7_3_HF_CAPA_ERR_ST 3;
BA_ "GenSigSendType" SG_ 816 SMT330_7_6_HF_RESP_ERR_ST 3;
BA_ "GenSigSendType" SG_ 816 SMT330_6_0_REQ_MESS_PUSHSTART 3;
BA_ "GenSigSendType" SG_ 816 SMT330_6_4_WARN_SSP_SIG1 3;
BA_ "GenSigSendType" SG_ 816 SMT330_5_1_WIUL_CUST 3;
BA_ "GenSigSendType" SG_ 816 SMT330_5_2_WAL_CUST 3;
BA_ "GenSigSendType" SG_ 816 SMT330_5_3_WARN_SSP_SIG2 3;
BA_ "GenSigSendType" SG_ 816 SMT330_5_5_WARN_SSP_SIG3 3;
BA_ "GenSigSendType" SG_ 816 SMT330_4_0_PUSHSTART_SW 3;
BA_ "GenSigSendType" SG_ 816 SMT330_4_1_SIG_KEY_PUSHSTART 3;
BA_ "GenSigSendType" SG_ 816 SMT330_4_2_HF_TOUCH_STATUS 3;
BA_ "GenSigSendType" SG_ 816 SMT330_4_5_HF_KICK_STATUS 3;
BA_ "GenSigSendType" SG_ 816 SMT330_3_0_BUZ_1SHOT_IN 3;
BA_ "GenSigSendType" SG_ 816 SMT330_3_1_BUZ_2SHOT_IN 3;
BA_ "GenSigSendType" SG_ 816 SMT330_3_2_BUZ_INTERMIT1_IN 3;
BA_ "GenSigSendType" SG_ 816 SMT330_3_3_BUZ_INTERMIT2_IN 3;
BA_ "GenSigSendType" SG_ 816 SMT330_3_4_BUZ_CONTINUE_IN 3;
BA_ "GenSigSendType" SG_ 816 SMT330_3_5_BUZ_TRPON_OK_IN 3;
BA_ "GenSigSendType" SG_ 816 SMT330_3_6_STATE_MODE_POWER 3;
BA_ "GenSigSendType" SG_ 1620 BIU654_7_4_KEYSW 3;
BA_ "GenSigSendType" SG_ 1620 BIU654_7_5_ALARM 3;
BA_ "GenSigSendType" SG_ 1620 BIU654_7_6_RES_STOP_JPN 3;
BA_ "GenSigSendType" SG_ 1620 BIU654_6_0_CONT_DATA_FOR_RES 3;
BA_ "GenSigSendType" SG_ 1620 BIU654_2_0_CODE_IMB_FOR_RES 3;
BA_ "GenSigSendType" SG_ 1618 BIU652_7_0_IND_SECURITY_IMB 3;
BA_ "GenSigSendType" SG_ 1618 BIU652_6_0_OCCUPATION_3RDRH 3;
BA_ "GenSigSendType" SG_ 1618 BIU652_6_1_OCCUPATION_3RDCTR 3;
BA_ "GenSigSendType" SG_ 1618 BIU652_6_2_OCCUPATION_3RDLH 3;
BA_ "GenSigSendType" SG_ 1618 BIU652_6_3_OCCUPATION_RRRH 3;
BA_ "GenSigSendType" SG_ 1618 BIU652_6_4_OCCUPATION_RRCTR 3;
BA_ "GenSigSendType" SG_ 1618 BIU652_6_5_OCCUPATION_RRLH 3;
BA_ "GenSigSendType" SG_ 1618 BIU652_6_6_HORNHAZARD_RES_SIG 3;
BA_ "GenSigSendType" SG_ 1618 BIU652_6_7_OCCUPATION_DRVR 3;
BA_ "GenSigSendType" SG_ 1618 BIU652_5_0_STATUS_ROOMLAMP 3;
BA_ "GenSigSendType" SG_ 1618 BIU652_5_3_HEADLAMP_SMALL 3;
BA_ "GenSigSendType" SG_ 1618 BIU652_5_4_ALL_UNLOCK_STATE 3;
BA_ "GenSigSendType" SG_ 1618 BIU652_5_5_DRVR_UNLOCK_STATE 3;
BA_ "GenSigSendType" SG_ 1618 BIU652_5_6_ALL_LOCK_STATE 3;
BA_ "GenSigSendType" SG_ 1618 BIU652_4_0_TRIG_LOCK_UNLOCK 3;
BA_ "GenSigSendType" SG_ 1618 BIU652_3_0_DOOR_DRVR 3;
BA_ "GenSigSendType" SG_ 1618 BIU652_3_1_DOOR_PASS 3;
BA_ "GenSigSendType" SG_ 1618 BIU652_3_2_DOOR_RRRH 3;
BA_ "GenSigSendType" SG_ 1618 BIU652_3_3_DOOR_RRLH 3;
BA_ "GenSigSendType" SG_ 1618 BIU652_3_4_DOOR_RG 3;
BA_ "GenSigSendType" SG_ 1618 BIU652_3_5_DOOR_TR 3;
BA_ "GenSigSendType" SG_ 1618 BIU652_3_7_OPENSW_RG 3;
BA_ "GenSigSendType" SG_ 1618 BIU652_2_0_LOCKSTATUS_DRVR 3;
BA_ "GenSigSendType" SG_ 1618 BIU652_2_1_LOCKSTATUS_PASS 3;
BA_ "GenSigSendType" SG_ 1618 BIU652_2_2_LOCKSTATUS_RRRH 3;
BA_ "GenSigSendType" SG_ 1618 BIU652_2_3_LOCKSTATUS_RRLH 3;
BA_ "GenSigSendType" SG_ 1618 BIU652_2_4_LOCKSTATUS_RG 3;
BA_ "GenSigSendType" SG_ 1618 BIU652_2_6_UNLOCK_DOORKEYSW 3;
BA_ "GenSigSendType" SG_ 1618 BIU652_2_7_LOCK_DOORKEYSW 3;
BA_ "GenSigSendType" SG_ 1617 BIU651_7_0_PWPOS_RL 3;
BA_ "GenSigSendType" SG_ 1617 BIU651_7_2_PWPOS_RR 3;
BA_ "GenSigSendType" SG_ 1617 BIU651_7_4_PWPOS_PASS 3;
BA_ "GenSigSendType" SG_ 1617 BIU651_7_6_PWPOS_DRVR 3;
BA_ "GenSigSendType" SG_ 1617 BIU651_6_0_IND_ACTIVE_HBA 3;
BA_ "GenSigSendType" SG_ 1617 BIU651_6_2_ADB_ACTIVE 3;
BA_ "GenSigSendType" SG_ 1617 BIU651_6_3_JUDGE_ILL 3;
BA_ "GenSigSendType" SG_ 1617 BIU651_6_4_TYPE_LO_BEAM 3;
BA_ "GenSigSendType" SG_ 1617 BIU651_6_6_TYPE_HI_BEAM 3;
BA_ "GenSigSendType" SG_ 1617 BIU651_5_0_SRF_ACTIVE 3;
BA_ "GenSigSendType" SG_ 1617 BIU651_5_1_SRF_IND 3;
BA_ "GenSigSendType" SG_ 1617 BIU651_5_3_SRF_LAMP_LIGHT 3;
BA_ "GenSigSendType" SG_ 1617 BIU651_5_4_SRF_LAMP_LEFT 3;
BA_ "GenSigSendType" SG_ 1617 BIU651_5_5_MSG_STATUS_HBA 3;
BA_ "GenSigSendType" SG_ 1617 BIU651_5_7_IND_FAIL_HBA 3;
BA_ "GenSigSendType" SG_ 1617 BIU651_4_0_BUZ_PATTERN 3;
BA_ "GenSigSendType" SG_ 1617 BIU651_4_4_CSTM_OPE_ALARM 3;
BA_ "GenSigSendType" SG_ 1617 BIU651_4_6_CSTM_HBA 3;
BA_ "GenSigSendType" SG_ 1617 BIU651_3_0_HEADLAMP_PASS_SW 3;
BA_ "GenSigSendType" SG_ 1617 BIU651_3_1_HEADLAMP_AUTO_SW 3;
BA_ "GenSigSendType" SG_ 1617 BIU651_3_2_JUDGE_DOOR_LOCK 3;
BA_ "GenSigSendType" SG_ 1617 BIU651_3_3_JUDGE_DOOR_UNLOCK 3;
BA_ "GenSigSendType" SG_ 1617 BIU651_3_4_HEADLAMP_Lo_SW 3;
BA_ "GenSigSendType" SG_ 1617 BIU651_3_5_HEADLAMP_HI_SW 3;
BA_ "GenSigSendType" SG_ 1617 BIU651_3_6_WIPER_AUTO_SW 3;
BA_ "GenSigSendType" SG_ 1617 BIU651_3_7_PRG_LIN_MEMORY_ON_OFF 3;
BA_ "GenSigSendType" SG_ 1617 BIU651_2_0_CSTM_ILLUMI_SSR 3;
BA_ "GenSigSendType" SG_ 1617 BIU651_2_1_HANDLE 3;
BA_ "GenSigSendType" SG_ 1617 BIU651_2_2_CSTM_SMT 3;
BA_ "GenSigSendType" SG_ 1617 BIU651_2_3_AJARDOOR_STATUS 3;
BA_ "GenSigSendType" SG_ 1617 BIU651_2_4_ONETOUCH_LAMP_OUT 3;
BA_ "GenSigSendType" SG_ 1617 BIU651_2_5_PRG_FAIL_FLAG 3;
BA_ "GenSigSendType" SG_ 1617 BIU651_2_6_CSTM_PSMECU 3;
BA_ "GenSigSendType" SG_ 1617 BIU651_2_7_STATE_REGIST_DEL 3;
BA_ "GenSigSendType" SG_ 1617 BIU651_1_4_SRPOS 3;
BA_ "GenSigSendType" SG_ 1617 BIU651_1_7_WIPER_INT_STATUS 3;
BA_ "GenSigStartValue" SG_ 942 BIU3AE_5_0_WIPER_FT_VOLUME 2;
VAL_ 914 MET392_8_2_TRIPB_RESET 1 "RESET" 0 "NOT_RESET" ;
VAL_ 914 MET392_5_2_TRIPA_RESET 1 "RESET" 0 "NOT_RESET" ;
VAL_ 937 MET3A9_3_5_DAY_NIGHT_STATE 1 "Night" 0 "Day" ;
VAL_ 937 MET3A9_3_0_ILL_LEVEL 21 "STEP_21" 20 "STEP_20" 19 "STEP_19" 18 "STEP_18" 17 "STEP_17" 16 "STEP_16" 15 "STEP_15" 14 "STEP_14" 13 "STEP_13" 12 "STEP_12" 11 "STEP_11" 10 "STEP_10" 9 "STEP_9" 8 "STEP_8" 7 "STEP_7" 6 "STEP_6" 5 "STEP_5" 4 "STEP_4" 3 "STEP_3" 2 "STEP_2" 1 "STEP_1" 0 "Not_required" ;
VAL_ 937 MET3A9_1_7_BRIGHT_STATE 1 "ON" 0 "OFF" ;
VAL_ 937 MET3A9_1_6_UI_THEME_STATE 1 "Night" 0 "Day" ;
VAL_ 1679 MET68F_3_0_DOWNSW_STS 1 "DOWNSW_ON" 0 "DOWNSW_OFF" ;
VAL_ 1679 MET68F_3_1_UPSW_STS 1 "UPSW_ON" 0 "UPSW_OFF" ;
VAL_ 1679 MET68F_3_2_ISETSW_STS 1 "ISETSW_ON" 0 "ISETSW_OFF" ;
VAL_ 1679 MET68F_3_3_MUD_SAND_SW_STS 1 "MUD_SAND_SW_ON" 0 "MUD_SAND_SW_OFF" ;
VAL_ 1679 MET68F_3_4_SNOW_DIRT_SW_STS 1 "SNOW_DIRT_SW_ON" 0 "SNOW_DIRT_SW_OFF" ;
VAL_ 1679 MET68F_3_5_WIDGET_SW_STS 1 "WIDGET_SW_ON" 0 "WIDGET_SW_OFF" ;
VAL_ 1679 MET68F_3_6_OK_SW_STS 1 "OK_SW_ON" 0 "OK_SW_OFF" ;
VAL_ 1679 MET68F_2_0_SIDRVSW_STS 3 "SIDRVSW_STS_SWB3_ON" 2 "SIDRVSW_STS_SWB2_ON" 1 "SIDRVSW_STS_SWB1_ON" 0 "SIDRVSW_STS_SW_OFF" ;
VAL_ 1678 MET68E_7_0_EGO_CAR_DISP_COLOR 9 "EGO_CAR_DISP_COLOR_P10" 8 "EGO_CAR_DISP_COLOR_P9" 7 "EGO_CAR_DISP_COLOR_P8" 6 "EGO_CAR_DISP_COLOR_P7" 5 "EGO_CAR_DISP_COLOR_P6" 4 "EGO_CAR_DISP_COLOR_P5" 3 "EGO_CAR_DISP_COLOR_P4" 2 "EGO_CAR_DISP_COLOR_P3" 1 "EGO_CAR_DISP_COLOR_P2" 0 "EGO_CAR_DISP_COLOR_P1" ;
VAL_ 1678 MET68E_4_0_CSTM_ALERT_VOL_VAL 3 "RESERVED" 2 "LARGE" 1 "MIDDLE" 0 "SMALL" ;
VAL_ 1678 MET68E_4_2_CSTM_SHIFT 1 "CSTM_SHIFT_ON" 0 "CSTM_SHIFT_OFF" ;
VAL_ 1678 MET68E_4_3_CSTM_WOW 1 "CSTM_WOW_ON" 0 "CSTM_WOW_OFF" ;
VAL_ 1678 MET68E_4_4_CSTM_GBYE 3 "Undefined" 2 "Undefined" 1 "CSTM_WLCM_ON" 0 "CSTM_WLCM_OFF" ;
VAL_ 1678 MET68E_4_6_CSTM_WLCM 3 "Undefined" 2 "Undefined" 1 "CSTM_WLCM_ON" 0 "CSTM_WLCM_OFF" ;
VAL_ 1678 MET68E_3_1_CSTM_REAR_REMIND 1 "CSTM_REAR_REMIND_ON" 0 "CSTM_REAR_REMIND_OFF" ;
VAL_ 1678 MET68E_3_2_SET_UNIT_OF_ELEC 7 "RESERVED" 6 "RESERVED" 5 "miles_MPH_kWh/100mile" 4 "miles_MPH_Wh/mile" 3 "miles_MPH_mile/kWh" 2 "km_km/h_kWh/100km" 1 "km_km/h_Wh/km" 0 "km_km/h_km/kWh" ;
VAL_ 1678 MET68E_3_5_CSTM_ES_STARTBZ 2 "CSTM_ES_STARTBZ_VOICE_ON" 1 "CSTM_ES_STARTBZ_BUZZER_ON" 0 "CSTM_ES_STARTBZ_OFF" ;
VAL_ 1678 MET68E_3_7_CSTM_ES_CATCHBZ 1 "CSTM_ES_CATCHBZ_ON" 0 "CSTM_ES_CATCHBZ_OFF" ;
VAL_ 1678 MET68E_2_0_CSTM_METUNIT 4 "RESERVED" 3 "miles_MPH_gal(UK)" 2 "miles_MPH_gal(US)" 1 "km_km/h_l/100km" 0 "km_km/h_km/l" ;
VAL_ 1674 MET68A_16_0_TRIP_DISP_TYPE 3 "RESERVED" 2 "TRIP_DISP_TYPE_TRIPB" 1 "TRIP_DISP_TYPE_TRIPA" 0 "TRIP_DISP_TYPE_ODO" ;
VAL_ 1674 MET68A_6_6_SI_FAIL_FLAG 1 "FAIL" 0 "NORMAL" ;
VAL_ 1674 MET68A_4_1_ILM_AIDM 1 "ILM_AIDM_NIGHT" 0 "ILM_AIDM_DAYTIME" ;
VAL_ 1674 MET68A_4_2_TEMP_ICON 7 "TEMP_ICON_NONE" 6 "TEMP_ICON_BLUEWHITE" 5 "TEMP_ICON_REDWHITE" 4 "TEMP_ICON_RED" 3 "TEMP_ICON_BLUE_BLINK" 2 "TEMP_ICON_REDBLUE" 1 "TEMP_ICON_BLUE" 0 "TEMP_ICON_WHITE" ;
VAL_ 1674 MET68A_4_5_SIDRIVE_MET_DISP 7 " RESERVED" 6 "S" 5 "ECO-C" 4 "I" 3 "DEEP_SNOW_MUD" 2 "S#" 1 "X_SNOW_DIRT" 0 "NO_INPUT" ;
VAL_ 1673 MET689_20_0_VOICE_GUIDE_SUP 1 "ACTIVE" 0 "NON_ACTIVE" ;
VAL_ 1673 MET689_16_0_GSR_ELKS_SUP 1 "GSR_ELKS_SUP_ACTIVE" 0 "GSR_ELKS_SUP_NONE" ;
VAL_ 1673 MET689_16_1_GSR_AEBS_SUP 1 "GSR_AEBS_SUP_ACTIVE" 0 "GSR_AEBS_SUP_NONE" ;
VAL_ 1673 MET689_16_2_GSR_DDAW_SUP 1 "GSR_DDAW_SUP_ACTIVE" 0 "GSR_DDAW_SUP_NONE" ;
VAL_ 1673 MET689_16_3_GSR_ISA_SUP 1 "GSR_ISA_SUP_ACTIVE" 0 "GSR_ISA_SUP_NONE" ;
VAL_ 1673 MET689_16_4_IACC_SUP 1 "IACC_SUP_ACTIVE" 0 "IACC_SUP_NONE" ;
VAL_ 1673 MET689_16_7_SEAT_VENT_SUP 1 "SEAT_VENT_SUP_ACTIVE" 0 "SEAT_VENT_SUP_NONE" ;
VAL_ 1673 MET689_15_0_CAMERA 8 "CAMERA_SIDE(LVDS)" 7 "CAMERA_REAR_FRONT_SIDE2(LVDS)" 6 "CAMERA_REAR_FRONT_SIDE(LVDS)" 5 "CAMERA_REAR_FRONT(LVDS)" 4 "CAMERA_REAR(LVDS)" 3 "CAMERA_REAR_FRONT_SIDE(NTSC)" 2 "CAMERA_REAR_FRONT(NTSC)" 1 "CAMERA_REAR" 0 "CAMERA_NONE" ;
VAL_ 1673 MET689_12_0_SPK_AMP 17 "SPK_AMP_EXTERNALAMP_LEATHER_8SP" 16 "SPK_AMP_EXTERNALAMP_LEATHER_12SP" 9 "SPK_AMP_EXTERNALAMP_CLOTH_8SP" 8 "SPK_AMP_EXTERNALAMP_CLOTH_12SP" 7 "SPK_AMP_INTERNALAMP_BOOOSTER_10SP" 6 "SPK_AMP_INTERNALAMP_BOOOSTER_11SP" 5 "SPK_AMP_EXTERNALAMP_8SP" 4 "SPK_AMP_EXTERNALAMP_LEATHER" 3 "SPK_AMP_EXTERNALAMP_CLOTH" 2 "SPK_AMP_INTERNALAMP_6SP" 1 "SPK_AMP_INTERNALAMP_4SP" 0 "SPK_AMP_NON_CONNECT" ;
VAL_ 1673 MET689_10_1_SIDRIVE_SW_TYPE 3 "RESERVE" 2 "SOFT_SW" 1 "HARD_SW" 0 "NONE" ;
VAL_ 1673 MET689_10_3_XMODE_SW_TYPE 3 "RESERVE" 2 "SOFT_SW" 1 "HARD_SW" 0 "NONE" ;
VAL_ 1673 MET689_9_0_GPF_SUP 1 "GPF_SUP_ACTIVE" 0 "GPF_SUP_NONE" ;
VAL_ 1673 MET689_9_3_REAR_REMIND_SUP 1 "REAR_REMIND_SUP_ACTIVE" 0 "REAR_REMIND_SUP_NONE" ;
VAL_ 1673 MET689_9_5_TPMSDISP_SUP 1 "TPMSDISP_SUP_ACTIVE" 0 "TPMSDISP_SUP_NONE" ;
VAL_ 1673 MET689_9_6_GSI_SUP 1 "GSI_SUP_ACTIVE" 0 "GSI_SUP_NONE" ;
VAL_ 1673 MET689_9_7_SRVD_SUP 1 "SRVD_SUP_ACTIVE" 0 "SRVD_SUP_NONE" ;
VAL_ 1673 MET689_8_0_XMODE_SUP 3 "XMODE_SUP_ACTIVE(2MODE_GRAVEL)" 2 "XMODE_SUP_ACTIVE(2MODE)" 1 "XMODE_SUP_ACTIVE(1MODE)" 0 "XMODE_SUP_NONE" ;
VAL_ 1673 MET689_7_0_SIDRIVE_SUP 19 "3MODE_1SW" 18 "SI-DS(I,S,S#,TRACK+Individual)_3SW" 17 "SI-DS(I,S,S#,ECO(VTD)+Individual)_2SW" 16 "SI-DS(I,S,S#,ECO(VTD)+Individual)_1SW" 9 "SI-DS(I,S,S#,ECO(ACT4)+Individual)_2SW" 8 "SI-DS(I,S,S#,ECO(ACT4)+Individual)_1SW" 7 "1MODE(ECO-C)" 6 "3MODE(I,S,ECO-C)" 5 "2MODE_1SW(I,S)" 4 "2MODE(I,S#)" 3 "3MODE_3SW" 2 "3MODE_2SW" 1 "2MODE(I,S)" 0 "NONE" ;
VAL_ 1673 MET689_6_0_GRADE_INFO 1 "GRADE_INFO_WILDERNESS" 0 "GRADE_INFO_NONE" ;
VAL_ 1658 TPM67A_6_1_TIRE_COLOR_RR 3 "NON" 2 "NON" 1 "LOW_PRESSURE(YELLOW)" 0 "NOMAL(WHITE)" ;
VAL_ 1658 TPM67A_6_5_TIRE_COLOR_RL 3 "NON" 2 "NON" 1 "LOW_PRESSURE(YELLOW)" 0 "NOMAL(WHITE)" ;
VAL_ 1658 TPM67A_3_1_TIRE_COLOR_FL 3 "NON" 2 "NON" 1 "LOW_PRESSURE(YELLOW)" 0 "NOMAL(WHITE)" ;
VAL_ 1658 TPM67A_3_5_TIRE_COLOR_FR 3 "NON" 2 "NON" 1 "LOW_PRESSURE(YELLOW)" 0 "NOMAL(WHITE)" ;
VAL_ 1658 TPM67A_1_5_UNIT_IND_PRESSURE 3 "NON" 2 "NON" 1 "kPa" 0 "psi" ;
VAL_ 1658 TPM67A_1_7_IND_PRESSURE 1 "IND_PRESSURE" 0 "NO_IND_PRESSURE" ;
VAL_ 1657 TPM679_3_0_STATE_TPMS 3 "MODE_ERROR" 2 "TPMS3" 1 "TPMS2" 0 "TPMS1" ;
VAL_ 1657 TPM679_3_2_DEFINED_STATE_TPMS 3 "UNDER_CONFIRMATION" 2 "THRESHOLD_DECISION" 1 "UNDER_THRESHOLDING" 0 "NOMAL" ;
VAL_ 1657 TPM679_3_4_MODE_SELECT_TPMS 3 "Undefined" 2 "2Mode" 1 "3Mode" 0 "NOMAL" ;
VAL_ 1657 TPM679_2_0_WARN_TPMS 7 "FLASH_ON_1" 6 "FLASH_ON_3" 5 "FLASH_ON_3" 4 "FLASH_ON_2" 3 "FLASH_ON_1" 2 "FLASH_ON_1" 1 "LAMP_ON" 0 "LAMP_OFF" ;
VAL_ 1657 TPM679_2_3_INTERRUPT 2 "SYSTEM_FAIL" 1 "LOW_PRESSURE" 0 "NON_IND" ;
VAL_ 1657 TPM679_2_5_CHECKLUMP_TPMS 1 "LAMP_ON" 0 "LAMP_OFF" ;
VAL_ 826 ABG33A_5_0_P_SIDE_ABG_DEPLOY 1 "ON" 0 "OFF" ;
VAL_ 826 ABG33A_5_1_D_SIDE_ABG_DEPLOY 1 "ON" 0 "OFF" ;
VAL_ 826 ABG33A_5_2_FRONT_FAR_ABG_DEPLOY 1 "ON" 0 "OFF" ;
VAL_ 826 ABG33A_5_3_REAR_FAR_ABG_DEPLOY 1 "ON" 0 "OFF" ;
VAL_ 826 ABG33A_5_4_REAR_RH_ABG_DEPLOY 1 "ON" 0 "OFF" ;
VAL_ 826 ABG33A_5_5_REAR_LH_ABG_DEPLOY 1 "ON" 0 "OFF" ;
VAL_ 826 ABG33A_5_6_P_CURTAIN_ABG_DEPLOY 1 "ON" 0 "OFF" ;
VAL_ 826 ABG33A_5_7_D_CURTAIN_ABG_DEPLOY 1 "ON" 0 "OFF" ;
VAL_ 826 ABG33A_4_0_D_FRONT_ABG_DEPLOY 1 "ON" 0 "OFF" ;
VAL_ 826 ABG33A_4_1_P_FRONT_ABG_DEPLOY 1 "ON" 0 "OFF" ;
VAL_ 826 ABG33A_4_2_P_ABG_DEPLOY 1 "ON" 0 "OFF" ;
VAL_ 826 ABG33A_4_3_D_ABG_DEPLOY 1 "ON" 0 "OFF" ;
VAL_ 826 ABG33A_4_4_P_BELT_PRETENTION 1 "ON" 0 "OFF" ;
VAL_ 826 ABG33A_4_5_D_BELT_PRETENTION 1 "ON" 0 "OFF" ;
VAL_ 826 ABG33A_4_6_D_KNEE_ABG_DEPLOY 1 "ON" 0 "OFF" ;
VAL_ 826 ABG33A_4_7_P_KNEE_ABG_DEPLOY 1 "ON" 0 "OFF" ;
VAL_ 826 ABG33A_3_0_BELT_WRNING_PASS 3 "SW_FAIL" 2 "UNDECIDED" 1 "UNBUCKLED(PASSENGER OCCUPANT)" 0 "BUCKLE OR UNBUCKLED(PASSENGER EMPTY)" ;
VAL_ 826 ABG33A_3_2_BUCKLESW_DRVR 3 "NOT RECEIVED" 2 "INVALID" 1 "BUCKLE SW OFF" 0 "BUCKLE SW ON" ;
VAL_ 826 ABG33A_3_4_OCCUPATION_PASS 3 "SYS_FAIL" 2 "NON" 1 "ACTIVE" 0 "Non_PASSENGER" ;
VAL_ 826 ABG33A_3_6_IND_ACT_ABG_PASS 3 "NON" 2 "ON_IND" 1 "OFF_IND" 0 "ON_IND and OFF_IND" ;
VAL_ 826 ABG33A_2_0_IND_WARN_ABG 3 "OTHER_FAIL" 2 "RESERVE" 1 "FAIL_Turn_ON" 0 "Turn_OFF" ;
VAL_ 826 ABG33A_2_2_DETECT_CRUSH 7 "RESERVE" 6 "RESERVE" 5 "CRUSH_DETECT" 4 "RESERVE" 3 "RESERVE" 2 "RESERVE" 1 "RESERVE" 0 "NORMAL" ;
VAL_ 826 ABG33A_2_5_STATUS_CRUSH_ECALL 7 "RESERVE" 6 "RESERVE" 5 "REAR COLLISION" 4 "ROLLOVER" 3 "RIGHT SIDE COLLISION" 2 "LEFT SIDE COLLISION" 1 "FRONTAL COLLISION" 0 "NORMAL" ;
VAL_ 826 ABG33A_1_4_FLG_ABGIND_CTRL 1 "ACTIVE_PassengerSeat IND contorol" 0 "NON_PassengerSeat IND contorol" ;
VAL_ 826 ABG33A_1_5_REQ_COMM_CONT 1 "REQ" 0 "NON_REQ" ;
VAL_ 826 ABG33A_1_6_COLLISION_COUNTER 3 "RESERVD" 2 "MORE THAN ONCE" 1 "ONECE" 0 "NORMAL" ;
VAL_ 961 DMS3C1_7_4_SHORT_DIST_DETECT 1 "SHORT_DIST_DETECT" 0 "NO_SHORT_DIST_DETECT" ;
VAL_ 961 DMS3C1_7_5_PRESENCE_DETECT 1 "PRESENCE" 0 "NO_PRESENCE" ;
VAL_ 961 DMS3C1_7_6_RADER_EQUIP 1 "RADAR_EQUIP" 0 "NO_RADAR_EQUIP" ;
VAL_ 961 DMS3C1_7_7_LOSING_POSTURE_DETECT 1 "LOSING_POSTURE" 0 "NO_LOSING_POSTURE" ;
VAL_ 961 DMS3C1_6_0_ID_RECOG_CANCEL 1 "ID_RECOG_CANCEL" 0 "DEFAULT" ;
VAL_ 961 DMS3C1_6_1_ID_ENABLE_FLAG 1 "ID_VALID" 0 "ID_INVALID" ;
VAL_ 961 DMS3C1_6_2_PERMIT_AVN_FLAG 1 "PERMIT" 0 "PROHIBIT" ;
VAL_ 961 DMS3C1_6_4_DISTRACTION_STATUS 1 "DISTRACTION" 0 "DEFAULT" ;
VAL_ 961 DMS3C1_6_5_DROWSINESS_STATUS 1 "DROWSINESS" 0 "DEFAULT" ;
VAL_ 961 DMS3C1_6_6_DROWSINESS_LV2_STATUS 1 "DROWSINESS_LEVEL2" 0 "DEFAULT" ;
VAL_ 961 DMS3C1_6_7_NOT_DETECTED_STATUS 1 "NOT_DETECTED" 0 "DETECTED" ;
VAL_ 961 DMS3C1_5_0_ID_LIST 31 "ID_1_2_3_4_5" 1 "ID_1" 0 "DEFAULT" ;
VAL_ 961 DMS3C1_5_5_ID_EDIT_FLAG 6 "REQ_ID_DEL_ALL" 5 "REQ_CUST_DEL_DELECT" 4 "REQ_ID_DEL_DELECT" 3 "REQ_ID_CUST_EDIT" 2 "REQ_ID_REGIST" 0 "DEFAULT" ;
VAL_ 961 DMS3C1_4_0_DMS_IND_REQ_FLAG 7 "UNDEFINED" 5 "FAULT_IND" 4 "HALT_IND" 3 "OFF_IND" 2 "ID_DEF_IND" 1 "ID_UNDEF_IND" 0 "DEFAULT" ;
VAL_ 961 DMS3C1_4_3_DMS_RECOG_STATUS 1 "IDENTIFING_ON" 0 "IDENTIFING_OFF" ;
VAL_ 961 DMS3C1_4_4_DRIVER_STATUS 3 "DRV_GLASSES" 2 "DRV_MASK" 1 "DRV_NORMAL" 0 "DEFAULT" ;
VAL_ 961 DMS3C1_3_0_DRIVER_REGIST_ID 15 "IDENTIFING" 14 "ALL_ID" 5 "ID_5" 4 "ID_4" 3 "ID_3" 2 "ID_2" 1 "ID_1" 0 "DEFAULT" ;
VAL_ 961 DMS3C1_3_4_CUST_EDIT_FLAG 3 "REQ_CUST_FAIL" 2 "REQ_CUST_COMP" 1 "REQ_CUST_PRESENT" 0 "DEFAULT" ;
VAL_ 961 DMS3C1_3_6_ID_RECOG_FLAG 1 "ID_DEFINED" 0 "ID_UNDIFINED" ;
VAL_ 961 DMS3C1_2_0_LEVEL_DROWS 2 "DROWS_LEVEL2" 1 "DROWS_LEVEL1" 0 "NO_DROWSINESS" ;
VAL_ 961 DMS3C1_2_3_DROWS_DETECT_FLAG 1 "DROWS_DETECT" 0 "NO_DROWS_DETECT" ;
VAL_ 961 DMS3C1_2_7_DIST_DETECT_FLAG 1 "DIST_DETECT" 0 "NO_DIST_DETECT" ;
VAL_ 961 DMS3C1_1_4_WAKE_UP_FRAME 1 "WakeUP_FRAME" 0 "Normal_FRAME" ;
VAL_ 961 DMS3C1_1_5_REQ_COMM_CONT 1 "REQUEST" 0 "NO_REQUEST" ;
VAL_ 961 DMS3C1_1_7_EYE_DIST_FLAG 1 "EYE_DIST_DETECT" 0 "NO_DETECT" ;
VAL_ 1651 ACN673_7_2_REQ_STRG_H 3 "NO_DIFINITION" 2 "LOW" 1 "HIGH" 0 "OFF" ;
VAL_ 1651 ACN673_7_1_SEAT_H_L_AUTOIND 1 "ON" 0 "OFF" ;
VAL_ 1651 ACN673_7_0_SEAT_H_R_AUTOIND 1 "ON" 0 "OFF" ;
VAL_ 1651 ACN673_6_0_RR_FAN_SYMBOL 1 "ON" 0 "OFF" ;
VAL_ 1651 ACN673_6_2_SEAT_H_R 7 "VENT HI" 6 "VENT MI" 5 "VENT LO" 4 "UNDEFINED" 3 "HEATER HI" 2 "HEATER MI" 1 "HEATER LO" 0 "OFF" ;
VAL_ 1651 ACN673_6_5_SEAT_H_L 7 "VENT HI" 6 "VENT MI" 5 "VENT LO" 4 "UNDEFINED" 3 "HEATER HI" 2 "HEATER MI" 1 "HEATER LO" 0 "OFF" ;
VAL_ 1651 ACN673_5_0_DR_ONLY 3 "ALL" 2 "FRONT" 1 "DRIVER" 0 "BLANK" ;
VAL_ 1651 ACN673_5_4_AC_SI_DS_SET 3 "Reserve" 2 "Normal" 1 "Mild" 0 "Invalid" ;
VAL_ 1651 ACN673_5_6_STRG_H_AUTOIND 1 "ON" 0 "OFF" ;
VAL_ 1651 ACN673_5_7_AC_SI_DS_FLG 1 "WITH" 0 "WITHOUT" ;
VAL_ 1651 ACN673_4_0_SEAT_HEATER_DR 3 "3段" 2 "2段" 1 "1段" 0 "OFF" ;
VAL_ 1651 ACN673_4_2_SEAT_HEATER_PA 3 "3段" 2 "2段" 1 "1段" 0 "OFF" ;
VAL_ 1651 ACN673_4_4_SEAT_HEATER 1 "有り" 0 "なし" ;
VAL_ 1651 ACN673_4_5_TEMP_SET_TYPE 3 "不使用" 2 "華氏" 1 "欧州摂氏" 0 "欧州摂氏以外" ;
VAL_ 1651 ACN673_4_7_VENTI_SEAT_EX_HI 1 "ON" 0 "OFF" ;
VAL_ 1651 ACN673_1_6_SYNC_RR 1 "ON" 0 "OFF" ;
VAL_ 1651 ACN673_1_7_RR_LOCK 1 "ON" 0 "OFF" ;
VAL_ 1650 ACN672_6_0_DEF 1 "ON" 0 "OFF" ;
VAL_ 1650 ACN672_6_1_FAN_SYMBOL 1 "ON" 0 "OFF" ;
VAL_ 1650 ACN672_6_2_REAR_MODE 3 "FOOT" 2 "B/L" 1 "VENT" 0 "BLANK" ;
VAL_ 1650 ACN672_6_4_UNIT_TEMP 1 "deg F" 0 "deg C" ;
VAL_ 1650 ACN672_6_5_SPEC_AC_UNIT 3 "DUAL" 2 "SINGLE" 1 "MANU" 0 "LESS" ;
VAL_ 1650 ACN672_6_7_REAR_AC 1 "WITH" 0 "WITHOUT" ;
VAL_ 1650 ACN672_5_0_AC_VR_MODE 3 "No_Definition" 2 "VOICE_MODE_ERROR" 1 "VOICE_MODE_ON" 0 "OFF" ;
VAL_ 1650 ACN672_4_0_AC_INTERRUPT_DISPLAY 1 "ON" 0 "OFF" ;
VAL_ 1650 ACN672_4_1_AC_VR_ACTION 1 "INVALID" 0 "NORMAL" ;
VAL_ 1650 ACN672_3_0_MAX_AC 1 "ON" 0 "OFF" ;
VAL_ 1650 ACN672_3_1_INFO_SYNC_OR_SING 1 "ON" 0 "OFF" ;
VAL_ 1650 ACN672_3_2_INFO_FULL_OR_AUTO 3 "NONE" 2 "FULL_AUTO" 1 "AUTO" 0 "BLANK" ;
VAL_ 1650 ACN672_3_4_INFO_AC_ON 1 "ON" 0 "OFF" ;
VAL_ 1650 ACN672_3_5_INFO_RDEF 1 "ON" 0 "OFF" ;
VAL_ 1650 ACN672_3_6_INFO_CIRCULATION 3 "TURN_ON_ALL" 2 "Outside Air" 1 "Recirculation" 0 "TURN_OFF" ;
VAL_ 1650 ACN672_2_0_INFO_MODE_VENT 15 "ALL" 7 "ALL FLOW" 6 "DEF" 5 "FOOT/DEF" 4 "FOOT" 3 "B/L" 2 "VENTⅡ" 1 "VENT" 0 "BLANK" ;
VAL_ 1650 ACN672_2_5_INFO_LEV_BLOWERFAN 7 "HI" 6 "M5" 5 "M4" 4 "M3" 3 "M2" 2 "M1" 1 "LO" 0 "OFF" ;
VAL_ 1650 ACN672_1_4_LVL_BLOWERFAN_RR 7 "HI" 6 "M5" 5 "M4" 4 "M3" 3 "M2" 2 "M1" 1 "LO" 0 "OFF" ;
VAL_ 1650 ACN672_1_7_REAR_AUTO 1 "AUTO" 0 "BLANK" ;
VAL_ 722 ACN2D2_5_0_REQ_ENG_RPM 6 "HOT_LOLO (ME2-H/BF4)" 5 "HOT_Mi (ME2-H/BF4)" 4 "HOT_LO" 3 "COOL_LO" 2 "HOT_HI" 1 "COOL_HI" 0 "NON_REQ" ;
VAL_ 722 ACN2D2_4_0_LVL_PTC 3 "3RD" 2 "2ND" 1 "1ST" 0 "OFF" ;
VAL_ 722 ACN2D2_4_2_MARGIN_OF_AC 7 "7" 6 "6" 5 "5" 4 "4" 3 "3" 2 "2" 1 "1" 0 "0" ;
VAL_ 722 ACN2D2_4_5_LVL_BLOWER_FAN 7 "HI(AS1)/NONE(Other)" 6 "M5(AS1)/HI(Other)" 5 "M4" 4 "M3" 3 "M2/BLW_ON" 2 "M1" 1 "LO" 0 "OFF" ;
VAL_ 722 ACN2D2_3_0_PERMIT_ISS 3 "INHIBIT" 2 "PERMIT" 1 "PERMIT" 0 "PERMIT" ;
VAL_ 722 ACN2D2_3_2_TRQ_PAT_COMP_ESTM 6 "Pattern6" 5 "Pattern5" 4 "Pattern4" 3 "Pattern3" 2 "Pattern2" 1 "Pattern1" 0 "DEFAULT" ;
VAL_ 722 ACN2D2_3_5_IND_ROOM_TEMP 4 "40≦TR" 3 "30≦TR<40" 2 "20≦TR<30" 1 "10≦TR<20" 0 "<10" ;
VAL_ 722 ACN2D2_2_0_FAIL_TRQ_COMP_ESTM 1 "FAIL" 0 "NORMAL" ;
VAL_ 722 ACN2D2_2_1_FAIL_AC 1 "FAIL" 0 "NORMAL" ;
VAL_ 722 ACN2D2_2_2_REQ_INHIBIT_LOCKUP 1 "INHIBIT" 0 "PERMIT" ;
VAL_ 722 ACN2D2_2_3_AC_ON 1 "ON" 0 "OFF" ;
VAL_ 722 ACN2D2_2_4_RDEFOGSW 1 "ON" 0 "OFF" ;
VAL_ 722 ACN2D2_2_5_WARM_UP 1 "WARM_UP" 0 "WARM_UP_OUT" ;
VAL_ 722 ACN2D2_2_6_AC_AUTO_MANUAL 1 "Auto" 0 "Manu" ;
VAL_ 722 ACN2D2_2_7_COMP_TYPE 1 "VAR_COMP" 0 "FIX_COMP" ;
VAL_ 722 ACN2D2_1_7_WARM_POWER_CONT 1 "ON" 0 "OFF" ;
VAL_ 1667 ACN683_3_2_AC_DEFALTSET 1 "DEFALTSET" 0 "NO DEFALTSET" ;
VAL_ 1667 ACN683_3_0_RCC_ACN_RES 3 "NO_DIFINITION" 2 "ERROR" 1 "SUCCESS" 0 "UNDECIDED" ;
VAL_ 1667 ACN683_2_7_JUDGE_FANONLY 1 "OK" 0 "NG" ;
VAL_ 1667 ACN683_2_6_CSTM_LINK_SEAT_R 1 "ON" 0 "OFF" ;
VAL_ 1730 AVN6C2_7_0_LANGUAGE_SET 33 "Vietnamese" 32 "Thai" 31 "Bahasa Indonesia" 30 "Malay" 29 "Ukrainian" 28 "Turkish" 27 "Swedish" 26 "Slovak" 25 "Traditional Chinese" 24 "Simplified Chinese" 23 "Russian" 22 "Romanian" 21 "European Portuguese" 20 "Polish" 19 "Norwegian" 18 "Japanese" 17 "Italian" 16 "Hungarian" 15 "Hebrew" 14 "Greek" 13 "German" 12 "Finnish" 11 "European Spanish" 10 "European French" 9 "Dutch" 8 "Danish" 7 "Czech" 6 "British English" 5 "Australian English" 4 "Arabic" 3 "Mexican Spanish" 2 "Canadian French" 1 "American English" 0 "Invalid" ;
VAL_ 1730 AVN6C2_7_6_VALETMODE_ON_OFF 3 "Reserve" 2 "Valet ON" 1 "Valet OFF" 0 "Invalid" ;
VAL_ 1005 AVN3ED_7_0_ACPANEL_PA_TEMP_DIAL 7 "Counterclockwise 3 count" 6 "Counterclockwise 2 count" 5 "Counterclockwise 1 count" 4 "Invalid" 3 "Clockwize 3 count" 2 "Clockwize 2 count" 1 "Clockwize 1 count" 0 "Stop" ;
VAL_ 1005 AVN3ED_7_3_ACPANEL_DR_TEMP_DIAL 7 "Counterclockwise 3 count" 6 "Counterclockwise 2 count" 5 "Counterclockwise 1 count" 4 "Invalid" 3 "Clockwize 3 count" 2 "Clockwize 2 count" 1 "Clockwize 1 count" 0 "Stop" ;
VAL_ 1729 AVN6C1_7_0_MVS_VIEW_SELECT_SW 6 "Top+3D View (REAR)" 5 "Top View+Side and Side View" 4 "Top View+Front Narrow" 3 "Top View+Front Wide" 2 "Top View+Rear Narrow" 1 "Top View+Rear Wide" 0 "No request" ;
VAL_ 1729 AVN6C1_7_4_MVS_AUTO_DISPLAY_SW 3 "Reserved" 2 "ON" 1 "OFF" 0 "No request" ;
VAL_ 1729 AVN6C1_7_6_MVS_HITCH_GUIDE_REQ 3 "Reserved" 2 "ON" 1 "OFF" 0 "No request" ;
VAL_ 1725 AVN6BD_7_1_EYE_SAFETY_MODE_CSTM 1 "ON" 0 "OFF" ;
VAL_ 1725 AVN6BD_7_2_EYE_BRAKE_HAPTIC_CSTM 3 "BUZZER OFF/BREAK OFF" 2 "BUZZER OFF/BREAK ON" 1 "BUZZER ON/BREAK OFF" 0 "BUZZER ON/BREAK ON" ;
VAL_ 1725 AVN6BD_7_4_LDW_SW_PUSH_STATE 1 "SW_Push" 0 "SW_Release" ;
VAL_ 1725 AVN6BD_7_5_LDW_SW_FAIL_STATE 1 "Fail" 0 "No_Fail" ;
VAL_ 1725 AVN6BD_7_6_FCW_SW_PUSH_STATE 1 "SW_Push" 0 "SW_Release" ;
VAL_ 1725 AVN6BD_7_7_FCW_SW_FAIL_STATE 1 "Fail" 0 "No_Fail" ;
VAL_ 1725 AVN6BD_6_0_REQ_CHG_CSTM_EYE 1 "required" 0 "NOT required" ;
VAL_ 1725 AVN6BD_6_1_REQ_RESET_CSTM_EYE 1 "required" 0 "NOT required" ;
VAL_ 1725 AVN6BD_6_3_CSTM_LANE_CONT 1 "LEFT" 0 "RIGHT" ;
VAL_ 1725 AVN6BD_6_4_CSTM_MIS_AT_BACK 3 "ON_FAST" 2 "ON_MIDDLE" 1 "ON_SLOW" 0 "OFF" ;
VAL_ 1725 AVN6BD_6_6_CSTM_ACC_CONT 3 "Dynamic" 2 "Standard" 1 "Comfort" 0 "Eco" ;
VAL_ 1724 AVN6BC_5_0_LAT_N_S 1 "South" 0 "North" ;
VAL_ 1724 AVN6BC_1_4_GNSS_STATUS 7 "GNSS fail" 6 "Estimation error level 5" 5 "Estimation error level 4" 4 "Estimation error level 3" 3 "Estimation error level 2" 2 "Estimation error level 1" 1 "No fix" 0 "Invalid" ;
VAL_ 1724 AVN6BC_1_7_LON_E_W 1 "East" 0 "West" ;
VAL_ 1723 AVN6BB_7_0_ISA_IACC_OFFSET_CSTM 20 "10" 19 "9" 18 "8" 17 "7" 16 "6" 15 "5" 14 "4" 13 "3" 12 "2" 11 "1" 10 "0" 9 "-1" 8 "-2" 7 "-3" 6 "-4" 5 "-5" 4 "-6" 3 "-7" 2 "-8" 1 "-9" 0 "-10" ;
VAL_ 1723 AVN6BB_7_5_EYE_TOLLBOOTH_DECEL 1 "ON" 0 "OFF" ;
VAL_ 1723 AVN6BB_7_6_EYE_CURVE_DECEL_CSTM 1 "ON" 0 "OFF" ;
VAL_ 1723 AVN6BB_7_7_EYE_GREEN_LIGHT_CSTM 1 "ON" 0 "OFF" ;
VAL_ 1723 AVN6BB_6_0_CCU_FAIL 1 "FAIL" 0 "NORMAL" ;
VAL_ 1723 AVN6BB_6_1_EYE_P_CR_CSTM 1 "ON" 0 "OFF" ;
VAL_ 1723 AVN6BB_6_2_EYE_ALK_B_LDW_CSTM 3 "ALK-B ON+LDW ON" 2 "ALK-B ON+LDW OFF" 1 "ALK-B OFF+LDW ON" 0 "ALK-B OFF+LDW OFF" ;
VAL_ 1723 AVN6BB_6_4_EYE_CSTM_REQ 1 "required" 0 "NOT required" ;
VAL_ 1723 AVN6BB_6_5_EYE_ELK_CSTM 1 "ON" 0 "OFF" ;
VAL_ 1723 AVN6BB_6_6_EYE_ALKB_EDGE_CSTM 1 "ON" 0 "OFF" ;
VAL_ 1723 AVN6BB_6_7_FCW_ON_OFF 1 "ON" 0 "OFF" ;
VAL_ 1723 AVN6BB_5_0_DMS_SELECT_ID 5 "ID5" 4 "ID4" 3 "ID3" 2 "ID2" 1 "ID1" 0 "DEFAULT" ;
VAL_ 1723 AVN6BB_5_4_TPMS_TH_MODE_CSTM 3 "TPMS3 SW (Towing)" 2 "TPMS2 SW (Loading)" 1 "TPMS1 SW (Normal)" 0 "No Operation" ;
VAL_ 1723 AVN6BB_5_6_DMS_SET_REQ 1 "required" 0 "NOT required" ;
VAL_ 1723 AVN6BB_5_7_DMS_RECOG_SET 1 "RECOG_ON" 0 "RECOG_OFF" ;
VAL_ 1723 AVN6BB_4_0_DMS_EDIT_REQ 15 "Operation Failure" 6 "MANUAL_SCAN" 5 "ID_CUST_DEL" 4 "ID_CUST_SET" 3 "ALL_ID_DEL" 2 "ID_DEL_SELECT" 1 "ID_REGIST" 0 "DEFAULT" ;
VAL_ 1723 AVN6BB_4_4_VEHICLE_DEMO 1 "ON" 0 "OFF (Default)" ;
VAL_ 1723 AVN6BB_4_5_SRVD_CSTM_REQ 1 "required" 0 "NOT required" ;
VAL_ 1723 AVN6BB_4_6_SEAT_RESET_REQ 1 "required" 0 "NOT required" ;
VAL_ 1723 AVN6BB_4_7_SEATAWAY_SET_CSTM 1 "required" 0 "NOT required" ;
VAL_ 1723 AVN6BB_3_0_SRVD_ON_OFF 1 "ON" 0 "OFF" ;
VAL_ 1723 AVN6BB_3_1_PRG_RESET_REQ 1 "required" 0 "NOT required" ;
VAL_ 1723 AVN6BB_3_2_PRG_MEM_CSTM 1 "required" 0 "NOT required" ;
VAL_ 1723 AVN6BB_3_3_DMS_ON_OFF 1 "ON/OFF Change" 0 "invalid" ;
VAL_ 1723 AVN6BB_3_4_MIR_RESET_REQ 1 "required" 0 "NOT required" ;
VAL_ 1723 AVN6BB_3_5_MIR_AFOLD_CSTM 1 "required" 0 "NOT required" ;
VAL_ 1723 AVN6BB_3_6_MIR_RTILT_CSTM 1 "required" 0 "NOT required" ;
VAL_ 1723 AVN6BB_3_7_EYE_TSA_CSTM 1 "TSA Enable(ISA)" 0 "TSA Disable(MSA)" ;
VAL_ 1723 AVN6BB_2_0_AVH_ON_OFF 3 "BLANK_NoInput" 2 "AVH ON_Input" 1 "AVH OFF_Input" 0 "Neutral" ;
VAL_ 1723 AVN6BB_2_2_VDC_ON_OFF 3 "BLANK_NoInput" 2 "VDC ON_Input" 1 "VDC OFF_Input" 0 "Neutral" ;
VAL_ 1723 AVN6BB_2_4_CCU_HALT_RESET 1 "Reset/Halt" 0 "Normal" ;
VAL_ 1723 AVN6BB_2_5_EYE_LDW_TIMING_CSTM 1 "LATE" 0 "EARLY" ;
VAL_ 1723 AVN6BB_2_6_FCW_CSTM 3 "OFF" 2 "FAR" 1 "NEAR" 0 "ON/NORM" ;
VAL_ 1723 AVN6BB_1_4_EYE_WARN_CSTM 1 "Steering Wheel Vibration" 0 "Buzzer" ;
VAL_ 1723 AVN6BB_1_5_EYE_FCTI_CSTM 3 "Reserve" 2 "Display + Sound" 1 "Display" 0 "OFF" ;
VAL_ 1723 AVN6BB_1_7_LDW_WARNING_ON_OFF 1 "ON" 0 "OFF" ;
VAL_ 1722 AVN6BA_7_0_GUIDE_LINE_REAR 1 "ON" 0 "OFF" ;
VAL_ 1722 AVN6BA_7_1_GUIDE_LINE_SIDE 1 "ON" 0 "OFF" ;
VAL_ 1722 AVN6BA_7_2_GUIDE_LINE_FRONT 1 "ON" 0 "OFF" ;
VAL_ 1722 AVN6BA_7_3_STEER_ANGLE_INTERLOCK 1 "ON" 0 "OFF" ;
VAL_ 1722 AVN6BA_7_4_BACK_CAMERA_DELAY 1 "ON" 0 "OFF" ;
VAL_ 1722 AVN6BA_7_5_REQ_STOP_CAMERA_OUT 1 "REQ" 0 "NON_REQ" ;
VAL_ 1722 AVN6BA_7_6_VIEW_CHANGE_SW 3 "NO_DEFINITION" 2 "LONG_PUSH" 1 "SHORT_PUSH" 0 "INVALID" ;
VAL_ 1722 AVN6BA_6_6_CLIMATE_SYNC 1 "ON/OFF Change" 0 "invalid" ;
VAL_ 1722 AVN6BA_6_7_CLIMATE_F_DEF 1 "ON/OFF Change" 0 "invalid" ;
VAL_ 1722 AVN6BA_5_6_CLIMAITE_AUTO 1 "FULL AUTO ON" 0 "invalid" ;
VAL_ 1722 AVN6BA_5_7_CLIMAITE_MAX_AC 1 "ON/OFF Change" 0 "invalid" ;
VAL_ 1722 AVN6BA_4_0_CLIMAITE_VR 4 "Voice recognition" 0 "No voice recognition" ;
VAL_ 1722 AVN6BA_4_3_CLIMATE_AC 1 "ON/OFF Change" 0 "invalid" ;
VAL_ 1722 AVN6BA_4_4_CLIMAITE_FAN 15 "No change" 14 "Reserve" 13 "Reserve" 12 "Reserve" 11 "Reserve" 10 "Reserve" 9 "Reserve" 8 "Reserve" 7 "HI" 6 "M5" 5 "M4" 4 "M3" 3 "M2" 2 "M1" 1 "LO" 0 "invalid" ;
VAL_ 1722 AVN6BA_3_0_PERSONAL_IC_SH 7 "Reserve" 6 "Reserve" 5 "Reserve" 4 "Reserve" 3 "type C" 2 "type B" 1 "type A" 0 "No information" ;
VAL_ 1722 AVN6BA_3_4_CSTM_SONNER 1 "ON" 0 "OFF" ;
VAL_ 1722 AVN6BA_3_5_CSTM_RAB 1 "ON" 0 "OFF" ;
VAL_ 1722 AVN6BA_3_6_REQ_CHG_CSTM_RAB 1 "request" 0 "no request" ;
VAL_ 1722 AVN6BA_3_7_CLIMATE_R_DEF 1 "ON/OFF Change" 0 "invalid" ;
VAL_ 1722 AVN6BA_2_0_CLIMATE_PTC 1 "ON/OFF Change" 0 "invalid" ;
VAL_ 1722 AVN6BA_2_1_CLIMATE_MODE 1 "ON/OFF Change" 0 "invalid" ;
VAL_ 1722 AVN6BA_2_2_CLIMATE_SEAT_C_L 1 "ON/OFF Change" 0 "invalid" ;
VAL_ 1722 AVN6BA_2_3_CLIMATE_SEAT_C_R 1 "ON/OFF Change" 0 "invalid" ;
VAL_ 1722 AVN6BA_2_4_CLIMATE_SEAT_H_L 1 "ON/OFF Change" 0 "invalid" ;
VAL_ 1722 AVN6BA_2_5_CLIMATE_SEAT_H_R 1 "ON/OFF Change" 0 "invalid" ;
VAL_ 1722 AVN6BA_2_6_CLIMATE_INNER_AIR 1 "ON/OFF Change" 0 "invalid" ;
VAL_ 1722 AVN6BA_2_7_CLIMATE_ON_OFF 1 "ON/OFF Change" 0 "invalid" ;
VAL_ 1722 AVN6BA_1_4_CLIMAITE_STATUS 7 "Not Found" 6 "Detected" 5 "Replay" 4 "Loading" 3 "Accepting" 2 "Ready" 1 "Standby" 0 "Start up" ;
VAL_ 1722 AVN6BA_1_7_CLIMAITE_ON_OFF 1 "ON" 0 "OFF" ;
VAL_ 1713 AVN6B1_5_0_FAIL_AVN 1 "improperly" 0 "properly" ;
VAL_ 1713 AVN6B1_5_1_IN_OPERATION 1 "operating" 0 "non operating" ;
VAL_ 1713 AVN6B1_5_2_TYPE_NAVI 3 "High" 2 "Mid" 1 "Base" 0 "Non" ;
VAL_ 1713 AVN6B1_5_4_XM_ENABLE 3 "Reservation" 2 "Reservation" 1 "Receivable" 0 "Non" ;
VAL_ 1713 AVN6B1_5_6_FLG_ABLE_WELCOME_SCL 1 "表示可" 0 "表示不可" ;
VAL_ 1713 AVN6B1_5_7_STEER_ANGLE_INTERLOCK 1 "ON" 0 "OFF" ;
VAL_ 1713 AVN6B1_4_7_BACK_CAMERA_DELAY 1 "ON" 0 "OFF" ;
VAL_ 1713 AVN6B1_3_7_MVS_FTSNR_INTERRUPT 1 "ON" 0 "OFF" ;
VAL_ 1713 AVN6B1_2_0_GPS_CLOCK_FLG 1 "validity" 0 "invalidity" ;
VAL_ 1713 AVN6B1_2_6_TIME_FORMAT 3 "Reserved" 2 "24h" 1 "12h" 0 "Invalid" ;
VAL_ 1713 AVN6B1_1_4_WAKE_UP_FRAME 1 "WakeUP_FRAME" 0 "Normal_FRAME" ;
VAL_ 1713 AVN6B1_1_5_REQ_COMM_CONT 1 "REQ" 0 "NON_REQ" ;
VAL_ 1713 AVN6B1_1_6_ACTIVE_AVN_CSTM 1 "Customize" 0 "Non Customize" ;
VAL_ 1713 AVN6B1_1_7_REQ_STOP_CAMERA_OUT 1 "Request" 0 "No request" ;
VAL_ 1019 AVN3FB_7_0_SMT_TIM_RESET_REQ 1 "required" 0 "NOT required" ;
VAL_ 1019 AVN3FB_7_1_SMT_EG_CSTM_REQ 1 "required" 0 "NOT required" ;
VAL_ 1019 AVN3FB_7_2_EYE_YEILD_CSTM 1 "ON" 0 "OFF" ;
VAL_ 1019 AVN3FB_7_3_EYE_STOP_CSTM 1 "ON" 0 "OFF" ;
VAL_ 1019 AVN3FB_7_4_EYE_NO_ENTRY_CSTM 1 "ON" 0 "OFF" ;
VAL_ 1019 AVN3FB_7_5_MVS_CAMERA_SELECT_SW 1 "SW Push Event" 0 "No Operation(SW Release Event)" ;
VAL_ 1019 AVN3FB_7_7_ACPANEL_DR_ONLY 1 "SW Push Event" 0 "invalid" ;
VAL_ 1019 AVN3FB_6_6_ACPANEL_MODE_DOWN 1 "SW Push Event" 0 "invalid" ;
VAL_ 1019 AVN3FB_6_7_ACPANEL_MODE_UP 1 "SW Push Event" 0 "invalid" ;
VAL_ 1019 AVN3FB_5_6_ACPANEL_FAN_DOWN 1 "SW Push Event" 0 "invalid" ;
VAL_ 1019 AVN3FB_5_7_ACPANEL_FAN_UP 1 "SW Push Event" 0 "invalid" ;
VAL_ 1019 AVN3FB_4_0_ACPANEL_FAN_LEVEL 15 "No change" 14 "Reserve" 13 "Reserve" 12 "Reserve" 11 "Reserve" 10 "Reserve" 9 "Reserve" 8 "Reserve" 7 "HI" 6 "M5" 5 "M4" 4 "M3" 3 "M2" 2 "M1" 1 "LO" 0 "invalid" ;
VAL_ 1019 AVN3FB_4_4_ACPANEL_MODE_VENT 15 "Invalid" 6 "DEF" 5 "FOOT/DEF" 4 "FOOT" 3 "B/L" 2 "VENTⅡ" 1 "VENT" 0 "Invalid" ;
VAL_ 1019 AVN3FB_3_0_ACPANEL_PA_TEMP_DOWN 1 "SW Push Event" 0 "invalid" ;
VAL_ 1019 AVN3FB_3_1_ACPANEL_PA_TEMP_UP 1 "SW Push Event" 0 "invalid" ;
VAL_ 1019 AVN3FB_3_2_ACPANEL_DR_TEMP_DOWN 1 "SW Push Event" 0 "invalid" ;
VAL_ 1019 AVN3FB_3_3_ACPANEL_DR_TEMP_UP 1 "SW Push Event" 0 "invalid" ;
VAL_ 1019 AVN3FB_3_4_ACPANEL_SYNC 1 "SW Push Event" 0 "invalid" ;
VAL_ 1019 AVN3FB_3_5_ACPANEL_AC 1 "SW Push Event" 0 "invalid" ;
VAL_ 1019 AVN3FB_3_6_F_DEF_SW 1 "SW Push Event" 0 "invalid" ;
VAL_ 1019 AVN3FB_3_7_R_DEF_SW 1 "SW Push Event" 0 "invalid" ;
VAL_ 1019 AVN3FB_2_0_ACPANEL_AUTO 1 "SW Push Event" 0 "invalid" ;
VAL_ 1019 AVN3FB_2_1_ACPANEL_MAX_AC 1 "SW Push Event" 0 "invalid" ;
VAL_ 1019 AVN3FB_2_2_ACPANEL_SEAT_C_P 1 "SW Push Event" 0 "invalid" ;
VAL_ 1019 AVN3FB_2_3_ACPANEL_SEAT_C_D 1 "SW Push Event" 0 "invalid" ;
VAL_ 1019 AVN3FB_2_4_ACPANEL_SEAT_H_P 1 "SW Push Event" 0 "invalid" ;
VAL_ 1019 AVN3FB_2_5_ACPANEL_SEAT_H_D 1 "SW Push Event" 0 "invalid" ;
VAL_ 1019 AVN3FB_2_6_ACPANEL_INNER_AIR 1 "SW Push Event" 0 "invalid" ;
VAL_ 1019 AVN3FB_2_7_ACPANEL_AC_ON_OFF 1 "SW Push Event" 0 "invalid" ;
VAL_ 1019 AVN3FB_1_4_EYE_CSTM_REQ_3FB 1 "required" 0 "NOT required" ;
VAL_ 1019 AVN3FB_1_5_DDAW_WARNING_CSTM 1 "ON" 0 "OFF" ;
VAL_ 1019 AVN3FB_1_6_SIGN_SWITCH_SND 1 "ON" 0 "OFF" ;
VAL_ 1019 AVN3FB_1_7_SLWF_CSTM 1 "ON" 0 "OFF" ;
VAL_ 1299 AVN513_1_4_ActiveWakeUpBit 1 "active wakeup" 0 "passive wakeup" ;
VAL_ 1696 AIL6A0_7_0_AIL_RENDER_STA 7 "undefined" 6 "undefined" 5 "CUSTOM" 4 "DR_MD_Linkage" 3 "PAT_D" 2 "PAT_C" 1 "PAT_B" 0 "PAT_A" ;
VAL_ 1696 AIL6A0_7_3_AIL_RENDER_PAT_A_DIS 1 "ON" 0 "OFF" ;
VAL_ 1696 AIL6A0_7_4_AIL_RENDER_PAT_B_DIS 1 "ON" 0 "OFF" ;
VAL_ 1696 AIL6A0_7_5_AIL_RENDER_PAT_C_DIS 1 "ON" 0 "OFF" ;
VAL_ 1696 AIL6A0_7_6_AIL_RENDER_PAT_D_DIS 1 "ON" 0 "OFF" ;
VAL_ 1696 AIL6A0_7_7_AIL_RENDER_DR_MD_DIS 1 "ON" 0 "OFF" ;
VAL_ 1696 AIL6A0_5_6_AIL_CSTM_PRS_DIS_REQ 1 "Display" 0 "tone down" ;
VAL_ 1696 AIL6A0_5_7_AIL_RENDER_CSTM_DIS 1 "ON" 0 "OFF" ;
VAL_ 1696 AIL6A0_4_6_AIL_SECOND_COLOR_DIS 1 "ON" 0 "OFF" ;
VAL_ 1696 AIL6A0_4_7_AIL_SECOND_BRIGHT_DIS 1 "ON" 0 "OFF" ;
VAL_ 1696 AIL6A0_3_0_AIL_ADAS_VEH_DIS_STA 1 "ON" 0 "OFF" ;
VAL_ 1696 AIL6A0_3_1_AIL_ADAS_VEH_DIS__DIS 1 "ON" 0 "OFF" ;
VAL_ 1696 AIL6A0_3_2_AIL_ADAS_LANE_DEV_STA 1 "ON" 0 "OFF" ;
VAL_ 1696 AIL6A0_3_3_AIL_ADAS_LANE_DEV_DIS 1 "ON" 0 "OFF" ;
VAL_ 1696 AIL6A0_3_4_AIL_ADAS_FT_CROSS_STA 1 "ON" 0 "OFF" ;
VAL_ 1696 AIL6A0_3_5_AIL_ADAS_FT_CROSS_DIS 1 "ON" 0 "OFF" ;
VAL_ 1696 AIL6A0_3_6_AIL_ADAS_HANDS_FR_STA 1 "ON" 0 "OFF" ;
VAL_ 1696 AIL6A0_3_7_AIL_ADAS_HANDS_FR_DIS 1 "ON" 0 "OFF" ;
VAL_ 1696 AIL6A0_2_0_AIL_ADAS_EXP_STA 1 "ON" 0 "OFF" ;
VAL_ 1696 AIL6A0_2_1_AIL_ADAS_EXP_DIS 1 "ON" 0 "OFF" ;
VAL_ 1696 AIL6A0_2_2_AIL_NOTIFI_EXP_STA 1 "ON" 0 "OFF" ;
VAL_ 1696 AIL6A0_2_3_AIL_NOTIFI_EXP_DIS 1 "ON" 0 "OFF" ;
VAL_ 1696 AIL6A0_2_4_AIL_AIR_CON_EXP_STA 1 "ON" 0 "OFF" ;
VAL_ 1696 AIL6A0_2_5_AIL_AIR_CON_EXP_DIS 1 "ON" 0 "OFF" ;
VAL_ 1696 AIL6A0_1_4_AIL_ON_OFF_STA 1 "ON" 0 "OFF" ;
VAL_ 1696 AIL6A0_1_6_AIL_WEL_FOL_STA 1 "ON" 0 "OFF" ;
VAL_ 1696 AIL6A0_1_7_AIL_WEL_FOL_DIS 1 "ON" 0 "OFF" ;
VAL_ 1635 AHL663_3_0_FAIL_ADB 3 "NONE" 2 "BULB_CHECK" 1 "ON" 0 "OFF" ;
VAL_ 1635 AHL663_3_2_HEADLAMP_HI_IND 1 "ON" 0 "OFF" ;
VAL_ 1635 AHL663_3_3_ADB_ACTIVE_IND 1 "ON" 0 "OFF" ;
VAL_ 1635 AHL663_3_4_CSTM_SRH_OFF 1 "ON" 0 "OFF" ;
VAL_ 1635 AHL663_2_0_FAIL_AHL 7 "3_BLINK_ALARM(Only_MS2)" 6 "2_BLINK_ALARM(Only_MS2)" 5 "6_BLINK_ALARM(Only_MS2)" 4 "BULB_CHECK" 3 "2_BLINK_ALARM" 2 "3_BLINK_ALARM" 1 "ON" 0 "OFF" ;
VAL_ 1635 AHL663_2_3_FAIL_LED_HEADLAMP 3 "NONE" 2 "BULB_CHECK" 1 "ON" 0 "OFF" ;
VAL_ 1635 AHL663_2_5_IND_AFS 7 "NONE" 6 "NONE" 5 "NONE" 4 "BULB_CHECK" 3 "2_BLINK_ALARM" 2 "3_BLINK_ALARM" 1 "ON" 0 "OFF" ;
VAL_ 985 AHL3D9_1_4_AHL_STATE 1 "FAIL" 0 "Normal" ;
VAL_ 1625 PSM659_5_4_REQ_BTN_MIRCON_PTN 7 "Undefined" 6 "Undefined" 5 "Undefined" 4 "R linked (Disabled)" 3 "Restoring (Stop Only Enabled)" 2 "Save Only Enabled" 1 "Save and Restore Enabled" 0 "Disabled" ;
VAL_ 1625 PSM659_4_4_REQ_BTN_TRAY_SEAT 3 "Undefined" 2 "Disabled" 1 "Stop Enabled" 0 "Restore Enabled" ;
VAL_ 1625 PSM659_3_4_VAL_SEAT_AWAY 1 "ON" 0 "OFF" ;
VAL_ 1625 PSM659_2_4_DVR_SEAT_POSI_MNL_MOV 1 "In operation" 0 "No operation" ;
VAL_ 1660 MED67C_6_0_STATE_AFOLD_MIR_SW 3 "Undefined" 2 "Undefined" 1 "Restore (Restoring)" 0 "Retract (Retracting)" ;
VAL_ 1660 MED67C_6_2_STATE_LR_MIR_SW 3 "Undefined" 2 "Undefined" 1 "Right" 0 "Left" ;
VAL_ 1660 MED67C_6_4_ENBL_AFOLD_MIR_SW 1 "Disable" 0 "Enable" ;
VAL_ 1660 MED67C_4_4_VAL_MIR_RTILT_AMOUNT_ 3 "Small" 2 "Medium" 1 "Large" 0 "Undefined" ;
VAL_ 1660 MED67C_4_6_VAL_MIR_RTILT_AMOUNT_ 3 "Small" 2 "Medium" 1 "Large" 0 "Undefined" ;
VAL_ 1660 MED67C_3_5_VAL_MIR_AFOLD 1 "ON" 0 "OFF" ;
VAL_ 1645 PRG66D_4_0_BUZZER_RQ_PRG 15 "吹鳴停止要求" 13 "警報Type-3 要求" 12 "警報Type-2 要求" 11 "警報Type-1 要求" 4 "ｱﾝｻｰﾊﾞｯｸType-4要求" 3 "ｱﾝｻｰﾊﾞｯｸType-3要求" 2 "ｱﾝｻｰﾊﾞｯｸType-2要求" 1 "ｱﾝｻｰﾊﾞｯｸType-1要求" 0 "吹鳴要求なし" ;
VAL_ 1645 PRG66D_4_7_PRG_HF_ON_OFF 1 "ON" 0 "OFF" ;
VAL_ 1645 PRG66D_3_1_PRG_MEMORY_ON_OFF 1 "ON" 0 "OFF" ;
VAL_ 1645 PRG66D_3_3_PRG_LOCK_SW_RQ 1 "REQUEST" 0 "NON REQUEST" ;
VAL_ 1645 PRG66D_3_5_KICK_CSTM_TIMER 7 "7秒" 6 "6秒" 5 "5秒" 4 "4秒" 3 "3秒" 2 "2秒" 1 "1秒" 0 "0秒" ;
VAL_ 1645 PRG66D_2_2_HAZARD 3 "Type-3 要求" 2 "Type-2 要求" 1 "Type-1 要求" 0 "点滅要求無" ;
VAL_ 1646 PRG66E_5_5_PERMIT_PRG_OPER 7 "No_Definition" 6 "No_Definition" 5 "No_Definition" 4 "PERMIT" 3 "TEMPORARY_INHIBIT(NO_ACTION)" 2 "TEMPORARY_INHIBIT(REFUSAL)" 1 "INHIBIT(FAULT)" 0 "INHIBIT(UNINITIALIZED)" ;
VAL_ 1646 PRG66E_4_0_PERM_PRG_OPER_OPEN 1 "PERMIT" 0 "INHIBIT" ;
VAL_ 1646 PRG66E_4_1_PERM_PRG_OPER_OPEN 1 "PERMIT" 0 "INHIBIT" ;
VAL_ 1646 PRG66E_4_2_FACT_PRG_OPER 7 "ASSIST_OPERATION" 6 "OPERATION_REJECTED" 5 "FAIL-SAFE2" 4 "FAIL-SAFE" 3 "JAMPRO_CLOSING" 2 "JAMPRO_OPENING" 1 "CECU_REQUEST" 0 "STOPPED" ;
VAL_ 1646 PRG66E_4_6_CUR_RG_STATE 3 "No_Definition" 2 "OPEN" 1 "FULL_CLOSE" 0 "UNKNOWN (UNLEARNED)" ;
VAL_ 1646 PRG66E_2_4_SW_PRG_PULS_CLOSE 1 "ON" 0 "OFF" ;
VAL_ 1646 PRG66E_2_5_SW_PRG_PULS_OPEN 1 "ON" 0 "OFF" ;
VAL_ 1646 PRG66E_2_6_SW_PRG_LOCK 1 "ON" 0 "OFF" ;
VAL_ 1646 PRG66E_2_7_SW_PRG_INNER 1 "ON" 0 "OFF" ;
VAL_ 1646 PRG66E_1_4_STATUS_PRG_OPER 7 "No_Definition" 6 "No_Definition" 5 "UNKNOWN" 4 "FULL_CLOSE" 3 "CLOSING" 2 "OPENING" 1 "MID_OPEN_STOP" 0 "FULL_OPEN" ;
VAL_ 1646 PRG66E_1_7_PERMIT_MEM_POS_PRG 1 "PERMIT" 0 "INHIBIT" ;
VAL_ 818 PMN332_7_0_RES_CONTROL_STATUS 3 "Termination for Remote engine start control (Termination sequence for Remote engine start control)" 2 "Remote engine start heating operation (During Remote engine start running)" 1 "Remote engine start starting control (Before engine starts)" 0 "OFF (Remote engine start uncontrolled)" ;
VAL_ 818 PMN332_7_2_REQ_RES_P_LOCK 1 "REQ_RES_P_LOCK" 0 "NON_REQ" ;
VAL_ 818 PMN332_7_7_REQ_STOP_RES 1 "REQ_STOP_RES" 0 "NON_REQ" ;
VAL_ 818 PMN332_6_7_CUST 1 "ON" 0 "OFF" ;
VAL_ 818 PMN332_5_0_PUSHSTART_SW 1 "ON" 0 "OFF" ;
VAL_ 818 PMN332_5_1_SIG_KEY_PUSHSTART 1 "Key_DEFINED" 0 "Key_NOT_DEFINED" ;
VAL_ 818 PMN332_5_2_STATE_MODE_POWER 2 "RES_Start_MODE" 1 "Pre_Air_Cond_MODE" 0 "Normal_MODE" ;
VAL_ 818 PMN332_5_4_BUZ_2SHOT_IN 1 "REQ" 0 "NON_REQ" ;
VAL_ 818 PMN332_5_5_BUZ_INTERMIT1_IN 1 "REQ" 0 "NON_REQ" ;
VAL_ 818 PMN332_5_6_BUZ_INTERMIT2_IN 1 "REQ" 0 "NON_REQ" ;
VAL_ 818 PMN332_5_7_BUZ_CONTINUE_IN 1 "REQ" 0 "NON_REQ" ;
VAL_ 818 PMN332_2_0_WARN_SSP_SIG1 1 "SMART_FAIL_WARN" 0 "NON_REQ" ;
VAL_ 818 PMN332_2_1_WARN_SSP_SIG2 4 "TIMER_RESET_DISPLAY" 3 "30S_BEFORE_ENGINE_STOP" 2 "SMART_EMERGENCY_STOP_OPERATION" 1 "SMART_FAIL_WARN" 0 "NON_REQ" ;
VAL_ 818 PMN332_2_4_SMT_PWR_SIG 2 "IGNITION_ON_IND" 1 "ACCESSORY_IND" 0 "NON_REQ" ;
VAL_ 818 PMN332_2_7_BUZ_1SHOT_IN 1 "REQ" 0 "NON_REQ" ;
VAL_ 816 SMT330_7_3_HF_CAPA_ERR_ST 1 "error" 0 "normal" ;
VAL_ 816 SMT330_7_6_HF_RESP_ERR_ST 1 "error" 0 "normal" ;
VAL_ 816 SMT330_6_0_REQ_MESS_PUSHSTART 8 "Power_OFF_REQ_INDI" 7 "SHIFT_P_REQ_INDI" 6 "Power_OFF_by_Battery_Protect_INDI" 4 "(Reseved)" 3 "MT_EG_Start_Support_INDI" 2 "AT_EG_Start_Support2_INDI" 1 "AT_EG_Start_Support1_INDI" 0 "NON_REQ" ;
VAL_ 816 SMT330_6_4_WARN_SSP_SIG1 14 "EV_Get_Off_Safety2_INDI" 13 "EV_Get_Off_Safety1_INDI" 12 "AT_EG_Start_Support4_INDI" 11 "(Reserved)AT_EG_Start_Support3_INDI" 10 "KEY_Battery_LOW_WARN" 9 "(AS1 series only)EG_Start_OK_INDI" 8 "(AS1 series only)POWER_ON_INDI" 7 "NO_KEY_WARN" 6 "EG_Start_OK_INDI（MT）" 5 "Emergency_OPERATE_INDI_(MT)" 4 "Emergency_OPERATE_INDI_(AT)" 3 "EG_Start_OK_INDI（AT）" 2 "Steering_Lock_NON_Release_WARN" 1 "SMART_FAIL_WARN" 0 "NON_REQ" ;
VAL_ 816 SMT330_5_2_WAL_CUST 1 "SW_FAIL" 0 "Normal" ;
VAL_ 816 SMT330_5_3_WARN_SSP_SIG2 2 "SHIFT_POS_WARN" 1 "POWER_OFF_OPERATE_REQ" 0 "NON_REQ" ;
VAL_ 816 SMT330_5_5_WARN_SSP_SIG3 4 "KEY_Leaved_WARN" 3 "(Reserved)" 2 "EG_Start_OPERATE_INDI_MT" 1 "EG_Start_OPERATE_INDI_AT" 0 "NON_REQ" ;
VAL_ 816 SMT330_4_0_PUSHSTART_SW 1 "ON" 0 "OFF" ;
VAL_ 816 SMT330_4_1_SIG_KEY_PUSHSTART 1 "Key_DEFINED" 0 "Key_NOT_DEFINED" ;
VAL_ 816 SMT330_4_2_HF_TOUCH_STATUS 7 "initialize" 6 "(rezerved)" 5 "stop" 4 "stay" 3 "release" 2 "hold" 1 "approach" 0 "absence" ;
VAL_ 816 SMT330_4_5_HF_KICK_STATUS 17 "hand sensor" 16 "(reserved)" 1 "detection" 0 "undetected" ;
VAL_ 816 SMT330_3_0_BUZ_1SHOT_IN 1 "REQ" 0 "NON_REQ" ;
VAL_ 816 SMT330_3_1_BUZ_2SHOT_IN 1 "REQ" 0 "NON_REQ" ;
VAL_ 816 SMT330_3_2_BUZ_INTERMIT1_IN 1 "REQ" 0 "NON_REQ" ;
VAL_ 816 SMT330_3_3_BUZ_INTERMIT2_IN 1 "REQ" 0 "NON_REQ" ;
VAL_ 816 SMT330_3_4_BUZ_CONTINUE_IN 1 "REQ" 0 "NON_REQ" ;
VAL_ 816 SMT330_3_5_BUZ_TRPON_OK_IN 1 "REQ" 0 "NON_REQ" ;
VAL_ 816 SMT330_3_6_STATE_MODE_POWER 2 "RES_Start_MODE" 1 "Pre_Air_Cond_MODE" 0 "Normal_MODE" ;
VAL_ 816 SMT330_1_4_WAKE_UP_FRAME 1 "WakeUP_FRAME" 0 "Normal_FRAME" ;
VAL_ 816 SMT330_1_5_REQ_COMM_CONT 1 "REQ" 0 "NON_REQ" ;
VAL_ 1622 BIU656_6_0_KICK_OPEN_REQ_PRG 1 "ACTIVE" 0 "NON_ACTIVE" ;
VAL_ 1622 BIU656_6_1_KICK_CLOSE_REQ_PRG 1 "ACTIVE" 0 "NON_ACTIVE" ;
VAL_ 1622 BIU656_6_6_CARGO_LAMP_OUT 1 "Turn_ON" 0 "Turn_OFF" ;
VAL_ 1622 BIU656_6_7_PERMITT_KEY_RG_UNL 1 "PERMIT" 0 "INHIBIT" ;
VAL_ 1622 BIU656_5_0_PRG_DRVR_OPENERSW 1 "ON" 0 "OFF" ;
VAL_ 1622 BIU656_5_1_HF_PRG_OFF_SW 1 "ON" 0 "OFF" ;
VAL_ 1622 BIU656_5_2_PERMIT_OPEN_RG 1 "PERMIT" 0 "INHIBIT" ;
VAL_ 1622 BIU656_5_3_BUZ_ON_OFF 1 "ON" 0 "OFF" ;
VAL_ 1622 BIU656_5_4_PRG_DRVR_SW_PERMIT 1 "PERMIT" 0 "INHIBIT" ;
VAL_ 1622 BIU656_5_5_CSTM_HF_PRG_LOCK 1 "ACTIVE" 0 "NON_ACTIVE" ;
VAL_ 1622 BIU656_5_6_CSTM_KICK_SENSOR 1 "ACTIVE" 0 "NON_ACTIVE" ;
VAL_ 1622 BIU656_5_7_KICK_REQ_PRG 1 "ACTIVE" 0 "NON_ACTIVE" ;
VAL_ 1622 BIU656_4_0_NOT_SMT_KEY_RG_SW 3 "No_definition" 2 "Long_Key_Press" 1 "Short_Key_Press" 0 "OFF" ;
VAL_ 1622 BIU656_4_2_SMT_KEY_RG_SW 3 "No_definition" 2 "Long_Key_Press" 1 "Short_Key_Press" 0 "OFF" ;
VAL_ 1622 BIU656_4_4_OPEN_RG_OPENER_SW 3 "No_definition" 2 "Long_Key_Press" 1 "Short_Key_Press" 0 "OFF" ;
VAL_ 1622 BIU656_3_4_CHECKED_KEYNO 7 "SMT_KEY_7" 6 "SMT_KEY_6" 5 "SMT_KEY_5" 4 "SMT_KEY_4" 3 "SMT_KEY_3" 2 "SMT_KEY_2" 1 "SMT_KEY_1" 0 "Unregistered" ;
VAL_ 1622 BIU656_3_7_LOCKSTATUS_DRVR 1 "UNLOCK" 0 "LOCK" ;
VAL_ 1621 BIU655_4_0_BUZZER_PATTERN 178 "BUZ_pattern2_by_autolock" 177 "BUZ_pattern1_by_autolock" 165 "BUZ_pattern5_by_answerback" 164 "BUZ_pattern4_by_answerback" 163 "BUZ_pattern3_by_answerback" 162 "BUZ_pattern2_by_answerback" 161 "BUZ_pattern1_by_answerback" 240 "BUZ_stop_by_keyless" 145 "BUZ_pattern4_by_keyless" 129 "BUZ_pattern3_by_keyless" 225 "BUZ_pattern2_by_keyless" 97 "BUZ_pattern1_by_keyless" 0 "BUZ_hold" ;
VAL_ 1621 BIU655_3_0_BUZZER_VOL_REQ 7 "ON_duty_7" 6 "ON_duty_6" 5 "ON_duty_5" 4 "ON_duty_4" 3 "ON_duty_3" 2 "ON_duty_2" 1 "ON_duty_1" 0 "NONE" ;
VAL_ 1621 BIU655_3_3_RDEF_RELAY_REQ 1 "ON_REQ" 0 "OFF_REQ" ;
VAL_ 1621 BIU655_3_4_WIPER_DEICER_REQ 1 "ON_REQ" 0 "OFF_REQ" ;
VAL_ 1621 BIU655_3_5_FT_WIPER_REQ 3 "NON" 2 "Hi_REQ" 1 "Lo_REQ" 0 "OFF" ;
VAL_ 1621 BIU655_2_0_RR_WIPER_REQ 1 "ON_REQ" 0 "OFF_REQ" ;
VAL_ 1621 BIU655_2_1_WASHER_REQ 3 "NON" 2 "Rr_REQ" 1 "Fr_REQ" 0 "OFF" ;
VAL_ 1621 BIU655_2_3_HL_WASHER_REQ 1 "ON_REQ" 0 "OFF_REQ" ;
VAL_ 1621 BIU655_2_4_FT_FOG_RELAY_REQ 1 "ON_REQ" 0 "OFF_REQ" ;
VAL_ 1621 BIU655_2_5_HEADLAMP_HI_REQ 3 "NON" 2 "ON_REQ" 1 "Dimmer_REQ" 0 "OFF" ;
VAL_ 1621 BIU655_2_7_HEADLAMP_LO_REQ 1 "ON_REQ" 0 "OFF_REQ" ;
VAL_ 1620 BIU654_7_4_KEYSW 1 "ON" 0 "OFF" ;
VAL_ 1620 BIU654_7_5_ALARM 1 "FAIL" 0 "NORMAL" ;
VAL_ 1620 BIU654_7_6_RES_STOP_JPN 1 "REQ" 0 "NON_REQ" ;
VAL_ 1618 BIU652_7_0_IND_SECURITY_IMB 6 "WARNING by the supersonic wave sensor" 5 "WARNING by the impact sensor" 4 "ALARM by the supersonic wave sensor" 3 "ALARM by the impact sensor" 7 "ALARM by open the hood" 2 "ALARM by open the trunk" 1 "ALARM by open the door" 240 "Four flashing with the immobilize" 224 "Three flashing by the immobilizer" 208 "Two flashing by the immobilizer" 192 "One flashing by the immobilizer" 144 "Flashing by the immobilizer" 128 "Lighting by the immobilizer" 112 "Lighting by the panic mode" 96 "Wait flashing by ALARM" 80 "Flashing by ALARM" 64 "Lighting by ALARM" 0 "OFF" ;
VAL_ 1618 BIU652_6_0_OCCUPATION_3RDRH 1 "ON" 0 "OFF" ;
VAL_ 1618 BIU652_6_1_OCCUPATION_3RDCTR 1 "ON" 0 "OFF" ;
VAL_ 1618 BIU652_6_2_OCCUPATION_3RDLH 1 "ON" 0 "OFF" ;
VAL_ 1618 BIU652_6_3_OCCUPATION_RRRH 1 "ON" 0 "OFF" ;
VAL_ 1618 BIU652_6_4_OCCUPATION_RRCTR 1 "ON" 0 "OFF" ;
VAL_ 1618 BIU652_6_5_OCCUPATION_RRLH 1 "ON" 0 "OFF" ;
VAL_ 1618 BIU652_6_6_HORNHAZARD_RES_SIG 1 "ON" 0 "OFF" ;
VAL_ 1618 BIU652_6_7_OCCUPATION_DRVR 1 "ON" 0 "OFF" ;
VAL_ 1618 BIU652_5_0_STATUS_ROOMLAMP 7 "TURN_ON_α_S4" 6 "TURN_ON_α_S3A" 5 "TURN_ON_α_S3" 4 "TURN_ON_Pattern2_S2A" 3 "TURN_ON_Pattern1_S2" 2 "TURN_OFF_Pattern2_S1A" 1 "TURN_OFF_Pattern1_S1" 0 "TURN_OFF_S0" ;
VAL_ 1618 BIU652_5_3_HEADLAMP_SMALL 1 "Turn_ON" 0 "Turn_OFF" ;
VAL_ 1618 BIU652_5_4_ALL_UNLOCK_STATE 1 "ON" 0 "OFF" ;
VAL_ 1618 BIU652_5_5_DRVR_UNLOCK_STATE 1 "ON" 0 "OFF" ;
VAL_ 1618 BIU652_5_6_ALL_LOCK_STATE 1 "ON" 0 "OFF" ;
VAL_ 1618 BIU652_3_0_DOOR_DRVR 1 "OPEN" 0 "CLOSE" ;
VAL_ 1618 BIU652_3_1_DOOR_PASS 1 "OPEN" 0 "CLOSE" ;
VAL_ 1618 BIU652_3_2_DOOR_RRRH 1 "OPEN" 0 "CLOSE" ;
VAL_ 1618 BIU652_3_3_DOOR_RRLH 1 "OPEN" 0 "CLOSE" ;
VAL_ 1618 BIU652_3_4_DOOR_RG 1 "OPEN" 0 "CLOSE" ;
VAL_ 1618 BIU652_3_5_DOOR_TR 1 "OPEN" 0 "CLOSE" ;
VAL_ 1618 BIU652_3_7_OPENSW_RG 1 "ON" 0 "OFF" ;
VAL_ 1618 BIU652_2_0_LOCKSTATUS_DRVR 1 "UNLOCK" 0 "LOCK" ;
VAL_ 1618 BIU652_2_1_LOCKSTATUS_PASS 1 "UNLOCK" 0 "LOCK" ;
VAL_ 1618 BIU652_2_2_LOCKSTATUS_RRRH 1 "UNLOCK" 0 "LOCK" ;
VAL_ 1618 BIU652_2_3_LOCKSTATUS_RRLH 1 "UNLOCK" 0 "LOCK" ;
VAL_ 1618 BIU652_2_4_LOCKSTATUS_RG 1 "UNLOCK OR PERMIT_UNLOCK" 0 "LOCK OR PROHIBIT_UNLOOK" ;
VAL_ 1618 BIU652_2_6_UNLOCK_DOORKEYSW 1 "ON" 0 "OFF" ;
VAL_ 1618 BIU652_2_7_LOCK_DOORKEYSW 1 "ON" 0 "OFF" ;
VAL_ 1617 BIU651_7_0_PWPOS_RL 3 "other" 2 "ALL CLOSE" 1 "ALL OPEN" 0 "INDEFINITE" ;
VAL_ 1617 BIU651_7_2_PWPOS_RR 3 "other" 2 "ALL CLOSE" 1 "ALL OPEN" 0 "INDEFINITE" ;
VAL_ 1617 BIU651_7_4_PWPOS_PASS 3 "other" 2 "ALL CLOSE" 1 "ALL OPEN" 0 "INDEFINITE" ;
VAL_ 1617 BIU651_7_6_PWPOS_DRVR 3 "other" 2 "ALL CLOSE" 1 "ALL OPEN" 0 "INDEFINITE" ;
VAL_ 1617 BIU651_6_0_IND_ACTIVE_HBA 3 "NONE" 2 "BLINK" 1 "Turn_ON" 0 "Turn_OFF" ;
VAL_ 1617 BIU651_6_2_ADB_ACTIVE 1 "ACTIVE" 0 "NON_ACTIVE" ;
VAL_ 1617 BIU651_6_3_JUDGE_ILL 1 "ACTIVE" 0 "NON_ACTIVE" ;
VAL_ 1617 BIU651_6_4_TYPE_LO_BEAM 3 "NONE" 2 "LED" 1 "HID" 0 "HALOGEN" ;
VAL_ 1617 BIU651_6_6_TYPE_HI_BEAM 3 "NONE" 2 "LED" 1 "HID" 0 "HALOGEN" ;
VAL_ 1617 BIU651_5_0_SRF_ACTIVE 1 "ACTIVE" 0 "NON_ACTIVE" ;
VAL_ 1617 BIU651_5_1_SRF_IND 3 "NONE" 2 "BLINK" 1 "Turn_ON" 0 "Turn_OFF" ;
VAL_ 1617 BIU651_5_3_SRF_LAMP_LIGHT 1 "Turn_ON" 0 "Turn_OFF" ;
VAL_ 1617 BIU651_5_4_SRF_LAMP_LEFT 1 "Turn_ON" 0 "Turn_OFF" ;
VAL_ 1617 BIU651_5_5_MSG_STATUS_HBA 3 "NONE" 2 "FAIL" 1 "HALT" 0 "OFF" ;
VAL_ 1617 BIU651_5_7_IND_FAIL_HBA 1 "Turn_ON" 0 "Turn_OFF" ;
VAL_ 1617 BIU651_4_0_BUZ_PATTERN 8 "NON" 7 "Customize_2" 6 "Customize_1" 5 "NON" 4 "NON" 3 "Light_Warning" 2 "Key_Warning" 1 "Reverse_BUZZ" 0 "BUZZ_STOP" ;
VAL_ 1617 BIU651_4_4_CSTM_OPE_ALARM 3 "NON" 2 "OFF" 1 "ON" 0 "BLINK" ;
VAL_ 1617 BIU651_4_6_CSTM_HBA 3 "BLANK" 2 "MIRROR_HBA" 1 "EYESIGHT_HBA" 0 "NON_ACTIVE" ;
VAL_ 1617 BIU651_3_0_HEADLAMP_PASS_SW 1 "ON" 0 "OFF" ;
VAL_ 1617 BIU651_3_1_HEADLAMP_AUTO_SW 1 "ON" 0 "OFF" ;
VAL_ 1617 BIU651_3_2_JUDGE_DOOR_LOCK 1 "REQ" 0 "NON_REQ" ;
VAL_ 1617 BIU651_3_3_JUDGE_DOOR_UNLOCK 1 "CONNECT" 0 "NON_CONNECT" ;
VAL_ 1617 BIU651_3_4_HEADLAMP_Lo_SW 1 "ON" 0 "OFF" ;
VAL_ 1617 BIU651_3_5_HEADLAMP_HI_SW 1 "ON" 0 "OFF" ;
VAL_ 1617 BIU651_3_6_WIPER_AUTO_SW 1 "ON" 0 "OFF" ;
VAL_ 1617 BIU651_3_7_PRG_LIN_MEMORY_ON_OFF 1 "ON" 0 "OFF" ;
VAL_ 1617 BIU651_2_0_CSTM_ILLUMI_SSR 1 "ACTIVE" 0 "NON_ACTIVE" ;
VAL_ 1617 BIU651_2_1_HANDLE 1 "RHD" 0 "LHD" ;
VAL_ 1617 BIU651_2_2_CSTM_SMT 1 "SMART" 0 "NOT SMART" ;
VAL_ 1617 BIU651_2_3_AJARDOOR_STATUS 1 "AJAR_DOOR" 0 "NOT_AJAR_DOOR" ;
VAL_ 1617 BIU651_2_4_ONETOUCH_LAMP_OUT 1 "ON" 0 "OFF" ;
VAL_ 1617 BIU651_2_5_PRG_FAIL_FLAG 1 "ON" 0 "OFF" ;
VAL_ 1617 BIU651_2_6_CSTM_PSMECU 1 "ACTIVE" 0 "NON_ACTIVE" ;
VAL_ 1617 BIU651_2_7_STATE_REGIST_DEL 1 "FINISIED" 0 "NOT_FINISIED" ;
VAL_ 1617 BIU651_1_4_SRPOS 7 "未使用" 6 "未使用" 5 "チルト区間で開" 4 "スライド区間で開" 3 "全閉" 2 "チルト全開" 1 "スライド全開" 0 "不定" ;
VAL_ 1617 BIU651_1_7_WIPER_INT_STATUS 1 "INT_ON" 0 "INT_OFF" ;
VAL_ 995 BIU3E3_7_2_FAIL_HUMID 1 "FAIL" 0 "NORMAL" ;
VAL_ 995 BIU3E3_5_2_FAIL_HUMID_ATM_TMP 1 "FAIL" 0 "NORMAL" ;
VAL_ 995 BIU3E3_3_2_FAIL_HUMID_GLA_TMP 1 "FAIL" 0 "NORMAL" ;
VAL_ 995 BIU3E3_3_6_STATUS_HUMID 3 "Normal" 2 "Diagnosis" 1 "Delivery_Inspection" 0 "Initialization" ;
VAL_ 995 BIU3E3_1_4_CSTM_HUMID 1 "ACTIVE" 0 "NON_ACTIVE" ;
VAL_ 995 BIU3E3_1_5_COMM_HUMID 3 "No_difinition" 2 "FAIL" 1 "NORMAL" 0 "UNDECIDED" ;
VAL_ 995 BIU3E3_1_7_RX_FAIL_HUMID 1 "FAIL" 0 "NORMAL" ;
VAL_ 942 BIU3AE_5_0_WIPER_FT_VOLUME 5 "NON" 4 "Vol.5" 3 "Vol.4" 2 "Vol.3" 1 "Vol.2" 0 "Vol.1" ;
VAL_ 942 BIU3AE_4_4_FT_WIPER_FAIL 1 "FAIL" 0 "NORMAL" ;
VAL_ 942 BIU3AE_4_5_WIPER_FT 3 "AUTO" 2 "HIGH" 1 "LOW(MIST)" 0 "OFF" ;
VAL_ 942 BIU3AE_3_0_WINKER_LEVER_STATUS 5 "NON" 4 "Left_ON_Hold" 3 "Right_ON_Hold" 2 "Left_ON" 1 "Right_ON" 0 "OFF" ;
VAL_ 942 BIU3AE_3_4_WINKER_FACTOR 15 "NON" 14 "NON" 13 "Turn_Right(ActiveLaneChange)" 12 "Turn_Left(ActiveLaneChange)" 11 "Turn_Right(MinimumRiskManeuver)" 10 "Turn_Left(MinimumRiskManeuver)" 9 "OFF(MinimumRiskManeuver)" 8 "Hazard(Other)" 7 "Hazard(MinimumRiskManeuver)" 6 "Hazard(Emergency Brake)" 5 "Hazard(Hazard SW)" 4 "Turn_Right(deep push)" 3 "Turn_Right(shallow push)" 2 "Turn_Left(deep push)" 1 "Turn_Left(shallow push)" 0 "OFF" ;
VAL_ 942 BIU3AE_2_0_TURN_LAMP_FAIL_LEFT 1 "FAIL" 0 "NORMAL" ;
VAL_ 942 BIU3AE_2_1_TURN_LAMP_FAIL_RIGHT 1 "FAIL" 0 "NORMAL" ;
VAL_ 942 BIU3AE_2_3_HAZARD_SW 1 "ON" 0 "OFF" ;
